VERSION ""

NS_ :

BS_:

BU_: L_3HKBD L_FHPTC L_ATCU L_2HKBD L_PCM L_ATCU_vMON L_EVNT L_HKBD L_RHPTC

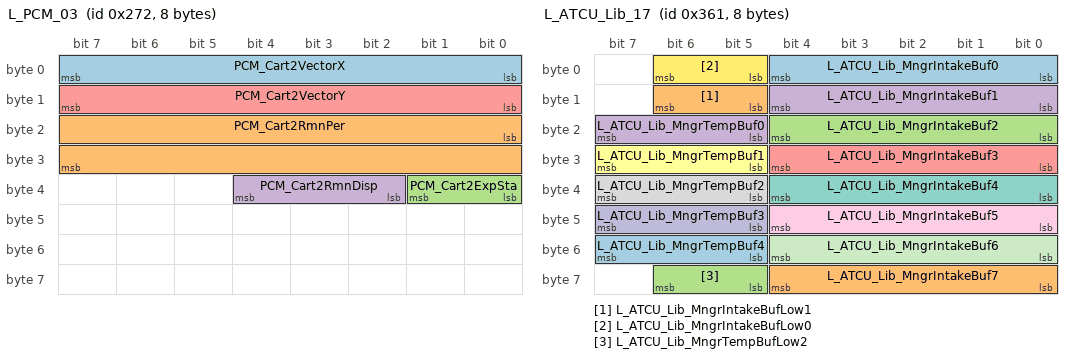
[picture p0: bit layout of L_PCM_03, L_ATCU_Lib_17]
BO_ 626 L_PCM_03: 8 L_PCM
 SG_ PCM_Cart2VectorX : 0|8@1+ (1,0) [0|0] ""  L_ATCU
 SG_ PCM_Cart2RmnPer : 16|16@1+ (0.01,0) [0|0] "%"  L_ATCU
 SG_ PCM_Cart2ExpSta : 32|2@1+ (1,0) [0|0] ""  L_ATCU
 SG_ PCM_Cart2RmnDisp : 34|3@1+ (1,0) [0|0] ""  L_ATCU
 SG_ PCM_Cart2VectorY : 8|8@1+ (1,0) [0|0] ""  L_ATCU

BO_ 327 L_FHPTC_08: 8 L_FHPTC
 SG_ FHPTC_2ndPsFlt : 0|1@1+ (1,0) [0|0] ""  L_ATCU
 SG_ FHPTC_2ndPsFltLVLow : 1|1@1+ (1,0) [0|0] ""  L_ATCU
 SG_ FHPTC_2ndPsFailLVSnr : 10|1@1+ (1,0) [0|0] ""  L_ATCU
 SG_ FHPTC_2ndPsFailCurrentSnr : 11|1@1+ (1,0) [0|0] ""  L_ATCU
 SG_ FHPTC_2ndPsFailCoreTempSnr : 12|1@1+ (1,0) [0|0] ""  L_ATCU
 SG_ FHPTC_2ndPsFailPcbTempSnr : 13|1@1+ (1,0) [0|0] ""  L_ATCU
 SG_ FHPTC_2ndPsFailIGBT : 14|1@1+ (1,0) [0|0] ""  L_ATCU
 SG_ FHPTC_2ndPsFailOpenLoad : 15|1@1+ (1,0) [0|0] ""  L_ATCU
 SG_ FHPTC_2ndPsLtdOpCause : 16|8@1+ (1,0) [0|0] ""  L_ATCU
 SG_ FHPTC_2ndPsFltLVHigh : 2|1@1+ (1,0) [0|0] ""  L_ATCU
 SG_ FHPTC_2ndPsSwVer : 24|8@1+ (1,0) [0|255] ""  L_ATCU
 SG_ FHPTC_2ndPsFltHVLow : 3|1@1+ (1,0) [0|0] ""  L_ATCU
 SG_ FHPTC_2ndPsFltHVHigh : 4|1@1+ (1,0) [0|0] ""  L_ATCU
 SG_ FHPTC_2ndPsFltOverCurrent : 5|1@1+ (1,0) [0|0] ""  L_ATCU
 SG_ FHPTC_2ndPsFltThermalShutDn : 6|1@1+ (1,0) [0|0] ""  L_ATCU
 SG_ FHPTC_2ndPsFltPcbThermalShutDn : 7|1@1+ (1,0) [0|0] ""  L_ATCU
 SG_ FHPTC_2ndPsFltMsgTmOutATCU : 8|1@1+ (1,0) [0|0] ""  L_ATCU
 SG_ FHPTC_2ndPsFailHVSnr : 9|1@1+ (1,0) [0|0] ""  L_ATCU

BO_ 865 L_ATCU_Lib_17: 8 L_ATCU
 SG_ L_ATCU_Lib_MngrIntakeBuf0 : 0|5@1+ (1,0) [0|31] ""  L_ATCU_vMON
 SG_ L_ATCU_Lib_MngrIntakeBufLow1 : 13|2@1+ (1,0) [0|3] ""  L_ATCU_vMON
 SG_ L_ATCU_Lib_MngrIntakeBuf2 : 16|5@1+ (1,0) [0|31] ""  L_ATCU_vMON
 SG_ L_ATCU_Lib_MngrTempBuf0 : 21|3@1+ (1,0) [0|7] ""  L_ATCU_vMON
 SG_ L_ATCU_Lib_MngrIntakeBuf3 : 24|5@1+ (1,0) [0|31] ""  L_ATCU_vMON
 SG_ L_ATCU_Lib_MngrTempBuf1 : 29|3@1+ (1,0) [0|7] ""  L_ATCU_vMON
 SG_ L_ATCU_Lib_MngrIntakeBuf4 : 32|5@1+ (1,0) [0|31] ""  L_ATCU_vMON
 SG_ L_ATCU_Lib_MngrTempBuf2 : 37|3@1+ (1,0) [0|7] ""  L_ATCU_vMON
 SG_ L_ATCU_Lib_MngrIntakeBuf5 : 40|5@1+ (1,0) [0|31] ""  L_ATCU_vMON
 SG_ L_ATCU_Lib_MngrTempBuf3 : 45|3@1+ (1,0) [0|7] ""  L_ATCU_vMON
 SG_ L_ATCU_Lib_MngrIntakeBuf6 : 48|5@1+ (1,0) [0|31] ""  L_ATCU_vMON
 SG_ L_ATCU_Lib_MngrIntakeBufLow0 : 5|2@1+ (1,0) [0|3] ""  L_ATCU_vMON
 SG_ L_ATCU_Lib_MngrTempBuf4 : 53|3@1+ (1,0) [0|7] ""  L_ATCU_vMON
 SG_ L_ATCU_Lib_MngrIntakeBuf7 : 56|5@1+ (1,0) [0|31] ""  L_ATCU_vMON
 SG_ L_ATCU_Lib_MngrTempBufLow2 : 61|2@1+ (1,0) [0|3] ""  L_ATCU_vMON
 SG_ L_ATCU_Lib_MngrIntakeBuf1 : 8|5@1+ (1,0) [0|31] ""  L_ATCU_vMON

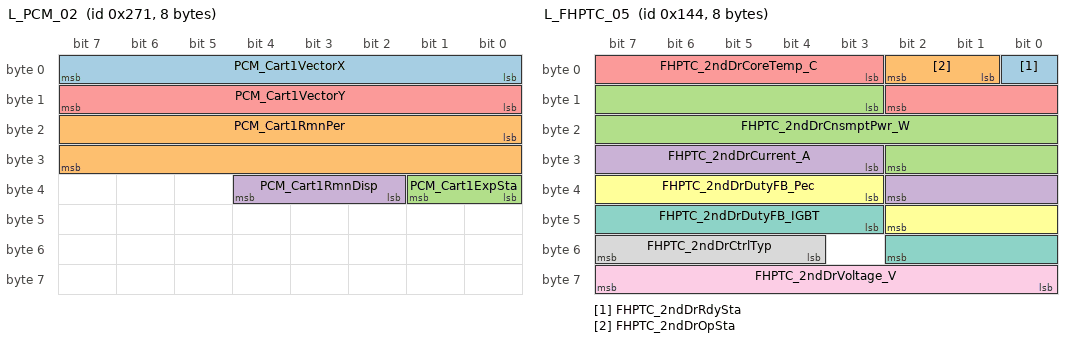
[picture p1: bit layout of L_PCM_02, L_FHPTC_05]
BO_ 625 L_PCM_02: 8 L_PCM
 SG_ PCM_Cart1VectorX : 0|8@1+ (1,0) [0|0] ""  L_ATCU
 SG_ PCM_Cart1RmnPer : 16|16@1+ (0.01,0) [0|0] "%"  L_ATCU
 SG_ PCM_Cart1ExpSta : 32|2@1+ (1,0) [0|0] ""  L_ATCU
 SG_ PCM_Cart1RmnDisp : 34|3@1+ (1,0) [0|0] ""  L_ATCU
 SG_ PCM_Cart1VectorY : 8|8@1+ (1,0) [0|0] ""  L_ATCU

BO_ 324 L_FHPTC_05: 8 L_FHPTC
 SG_ FHPTC_2ndDrRdySta : 0|1@1+ (1,0) [0|0] ""  L_ATCU
 SG_ FHPTC_2ndDrOpSta : 1|2@1+ (1,0) [0|0] ""  L_ATCU
 SG_ FHPTC_2ndDrCnsmptPwr_W : 11|16@1+ (1,0) [0|10000] "W"  L_ATCU
 SG_ FHPTC_2ndDrCurrent_A : 27|8@1+ (0.2,0) [0|50] "A"  L_ATCU
 SG_ FHPTC_2ndDrCoreTemp_C : 3|8@1+ (1,-40) [-40|200] "¡É"  L_ATCU
 SG_ FHPTC_2ndDrDutyFB_Pec : 35|8@1+ (0.5,0) [0|100] "%"  L_ATCU
 SG_ FHPTC_2ndDrDutyFB_IGBT : 43|8@1+ (0.5,0) [0|100] "%"  L_ATCU
 SG_ FHPTC_2ndDrCtrlTyp : 52|4@1+ (1,0) [0|0] ""  L_ATCU
 SG_ FHPTC_2ndDrVoltage_V : 56|8@1+ (4,0) [0|1000] "V"  L_ATCU

BO_ 866 L_ATCU_Lib_18: 8 L_ATCU
 SG_ L_ATCU_Lib_2LHMngrModBuf0 : 0|4@1+ (1,0) [0|15] ""  L_ATCU_vMON
 SG_ L_ATCU_Lib_2LHMngrModBuf3 : 12|4@1+ (1,0) [0|15] ""  L_ATCU_vMON
 SG_ L_ATCU_Lib_2LHMngrModBuf4 : 16|4@1+ (1,0) [0|15] ""  L_ATCU_vMON
 SG_ L_ATCU_Lib_2LHMngrModBuf5 : 20|4@1+ (1,0) [0|15] ""  L_ATCU_vMON
 SG_ L_ATCU_Lib_2LHMngrModBuf6 : 24|4@1+ (1,0) [0|15] ""  L_ATCU_vMON
 SG_ L_ATCU_Lib_2LHMngrModBuf7 : 28|4@1+ (1,0) [0|15] ""  L_ATCU_vMON
 SG_ L_ATCU_Lib_2LHMngrBlwBuf0 : 32|4@1+ (1,0) [0|15] ""  L_ATCU_vMON
 SG_ L_ATCU_Lib_2LHMngrBlwBuf1 : 36|4@1+ (1,0) [0|15] ""  L_ATCU_vMON
 SG_ L_ATCU_Lib_2LHMngrModBuf1 : 4|4@1+ (1,0) [0|15] ""  L_ATCU_vMON
 SG_ L_ATCU_Lib_2LHMngrBlwBuf2 : 40|4@1+ (1,0) [0|15] ""  L_ATCU_vMON
 SG_ L_ATCU_Lib_2LHMngrBlwBuf3 : 44|4@1+ (1,0) [0|15] ""  L_ATCU_vMON
 SG_ L_ATCU_Lib_2LHMngrBlwBuf4 : 48|4@1+ (1,0) [0|15] ""  L_ATCU_vMON
 SG_ L_ATCU_Lib_2LHMngrBlwBuf5 : 52|4@1+ (1,0) [0|15] ""  L_ATCU_vMON
 SG_ L_ATCU_Lib_2LHMngrBlwBuf6 : 56|4@1+ (1,0) [0|15] ""  L_ATCU_vMON
 SG_ L_ATCU_Lib_2LHMngrBlwBufHi0 : 60|2@1+ (1,0) [0|3] ""  L_ATCU_vMON
 SG_ L_ATCU_Lib_2LHMngrBlwBufHi1 : 62|2@1+ (1,0) [0|3] ""  L_ATCU_vMON
 SG_ L_ATCU_Lib_2LHMngrModBuf2 : 8|4@1+ (1,0) [0|15] ""  L_ATCU_vMON

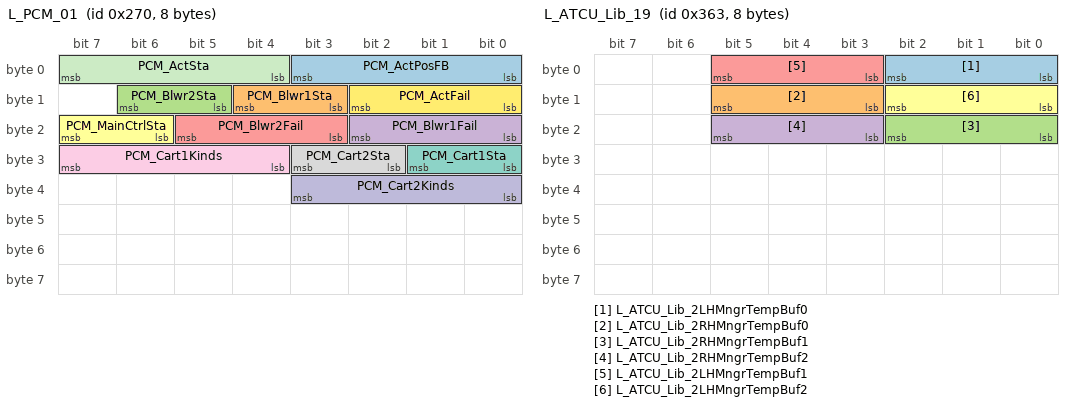
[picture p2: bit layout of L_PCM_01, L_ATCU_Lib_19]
BO_ 624 L_PCM_01: 8 L_PCM
 SG_ PCM_ActPosFB : 0|4@1+ (1,0) [0|0] ""  L_ATCU
 SG_ PCM_Blwr1Sta : 11|2@1+ (1,0) [0|0] ""  L_ATCU
 SG_ PCM_Blwr2Sta : 13|2@1+ (1,0) [0|0] ""  L_ATCU
 SG_ PCM_Blwr1Fail : 16|3@1+ (1,0) [0|0] ""  L_ATCU
 SG_ PCM_Blwr2Fail : 19|3@1+ (1,0) [0|0] ""  L_ATCU
 SG_ PCM_MainCtrlSta : 22|2@1+ (1,0) [0|0] ""  L_ATCU
 SG_ PCM_Cart1Sta : 24|2@1+ (1,0) [0|0] ""  L_ATCU
 SG_ PCM_Cart2Sta : 26|2@1+ (1,0) [0|0] ""  L_ATCU
 SG_ PCM_Cart1Kinds : 28|4@1+ (1,0) [0|0] ""  L_ATCU
 SG_ PCM_Cart2Kinds : 32|4@1+ (1,0) [0|0] ""  L_ATCU
 SG_ PCM_ActSta : 4|4@1+ (1,0) [0|0] ""  L_ATCU
 SG_ PCM_ActFail : 8|3@1+ (1,0) [0|0] ""  L_ATCU

BO_ 325 L_FHPTC_06: 8 L_FHPTC
 SG_ FHPTC_2ndDrFlt : 0|1@1+ (1,0) [0|0] ""  L_ATCU
 SG_ FHPTC_2ndDrFltLVLow : 1|1@1+ (1,0) [0|0] ""  L_ATCU
 SG_ FHPTC_2ndDrFailLVSnr : 10|1@1+ (1,0) [0|0] ""  L_ATCU
 SG_ FHPTC_2ndDrFailCurrentSnr : 11|1@1+ (1,0) [0|0] ""  L_ATCU
 SG_ FHPTC_2ndDrFailCoreTempSnr : 12|1@1+ (1,0) [0|0] ""  L_ATCU
 SG_ FHPTC_2ndDrFailPcbTempSnr : 13|1@1+ (1,0) [0|0] ""  L_ATCU
 SG_ FHPTC_2ndDrFailIGBT : 14|1@1+ (1,0) [0|0] ""  L_ATCU
 SG_ FHPTC_2ndDrFailOpenLoad : 15|1@1+ (1,0) [0|0] ""  L_ATCU
 SG_ FHPTC_2ndDrLtdOpCause : 16|8@1+ (1,0) [0|0] ""  L_ATCU
 SG_ FHPTC_2ndDrFltLVHigh : 2|1@1+ (1,0) [0|0] ""  L_ATCU
 SG_ FHPTC_2ndDrSwVer : 24|8@1+ (1,0) [0|0] ""  L_ATCU
 SG_ FHPTC_2ndDrFltHVLow : 3|1@1+ (1,0) [0|0] ""  L_ATCU
 SG_ FHPTC_2ndDrFltHVHigh : 4|1@1+ (1,0) [0|0] ""  L_ATCU
 SG_ FHPTC_2ndDrFltOverCurrent : 5|1@1+ (1,0) [0|0] ""  L_ATCU
 SG_ FHPTC_2ndDrFltThermalShutDn : 6|1@1+ (1,0) [0|0] ""  L_ATCU
 SG_ FHPTC_2ndDrFltPcbThermalShutDn : 7|1@1+ (1,0) [0|0] ""  L_ATCU
 SG_ FHPTC_2ndDrFltMsgTmOutATCU : 8|1@1+ (1,0) [0|0] ""  L_ATCU
 SG_ FHPTC_2ndDrFailHVSnr : 9|1@1+ (1,0) [0|0] ""  L_ATCU

BO_ 867 L_ATCU_Lib_19: 8 L_ATCU
 SG_ L_ATCU_Lib_2LHMngrTempBuf0 : 0|3@1+ (1,0) [0|7] ""  L_ATCU_vMON
 SG_ L_ATCU_Lib_2RHMngrTempBuf0 : 11|3@1+ (1,0) [0|7] ""  L_ATCU_vMON
 SG_ L_ATCU_Lib_2RHMngrTempBuf1 : 16|3@1+ (1,0) [0|7] ""  L_ATCU_vMON
 SG_ L_ATCU_Lib_2RHMngrTempBuf2 : 19|3@1+ (1,0) [0|7] ""  L_ATCU_vMON
 SG_ L_ATCU_Lib_2LHMngrTempBuf1 : 3|3@1+ (1,0) [0|7] ""  L_ATCU_vMON
 SG_ L_ATCU_Lib_2LHMngrTempBuf2 : 8|3@1+ (1,0) [0|7] ""  L_ATCU_vMON

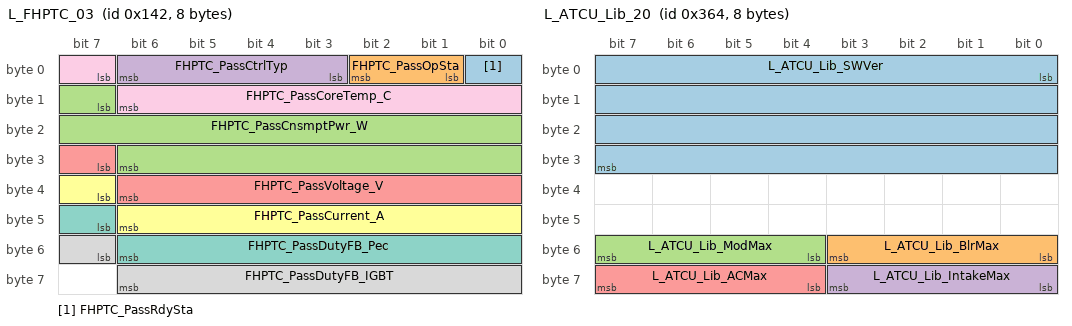
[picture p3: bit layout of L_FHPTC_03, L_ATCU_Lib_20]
BO_ 322 L_FHPTC_03: 8 L_FHPTC
 SG_ FHPTC_PassRdySta : 0|1@1+ (1,0) [0|0] ""  L_ATCU
 SG_ FHPTC_PassOpSta : 1|2@1+ (1,0) [0|0] ""  L_ATCU
 SG_ FHPTC_PassCnsmptPwr_W : 15|16@1+ (1,0) [0|10000] "W"  L_ATCU
 SG_ FHPTC_PassCtrlTyp : 3|4@1+ (1,0) [0|0] ""  L_ATCU
 SG_ FHPTC_PassVoltage_V : 31|8@1+ (4,0) [0|1000] "V"  L_ATCU
 SG_ FHPTC_PassCurrent_A : 39|8@1+ (0.2,0) [0|50] "A"  L_ATCU
 SG_ FHPTC_PassDutyFB_Pec : 47|8@1+ (0.5,0) [0|100] "%"  L_ATCU
 SG_ FHPTC_PassDutyFB_IGBT : 55|8@1+ (0.5,0) [0|100] "%"  L_ATCU
 SG_ FHPTC_PassCoreTemp_C : 7|8@1+ (1,-40) [-40|200] "¡É"  L_ATCU

BO_ 868 L_ATCU_Lib_20: 8 L_ATCU
 SG_ L_ATCU_Lib_SWVer : 0|32@1+ (1,0) [0|0] ""  L_ATCU_vMON
 SG_ L_ATCU_Lib_BlrMax : 48|4@1+ (1,0) [0|0] ""  L_ATCU_vMON
 SG_ L_ATCU_Lib_ModMax : 52|4@1+ (1,0) [0|0] ""  L_ATCU_vMON
 SG_ L_ATCU_Lib_IntakeMax : 56|4@1+ (1,0) [0|0] ""  L_ATCU_vMON
 SG_ L_ATCU_Lib_ACMax : 60|4@1+ (1,0) [0|0] ""  L_ATCU_vMON

BO_ 323 L_FHPTC_04: 8 L_FHPTC
 SG_ FHPTC_PassFlt : 0|1@1+ (1,0) [0|0] ""  L_ATCU
 SG_ FHPTC_PassFltLVLow : 1|1@1+ (1,0) [0|0] ""  L_ATCU
 SG_ FHPTC_PassFailLVSnr : 10|1@1+ (1,0) [0|0] ""  L_ATCU
 SG_ FHPTC_PassFailCurrentSnr : 11|1@1+ (1,0) [0|0] ""  L_ATCU
 SG_ FHPTC_PassFailCoreTempSnr : 12|1@1+ (1,0) [0|0] ""  L_ATCU
 SG_ FHPTC_PassFailPcbTempSnr : 13|1@1+ (1,0) [0|0] ""  L_ATCU
 SG_ FHPTC_PassFailIGBT : 14|1@1+ (1,0) [0|0] ""  L_ATCU
 SG_ FHPTC_PassFailOpenLoad : 15|1@1+ (1,0) [0|0] ""  L_ATCU
 SG_ FHPTC_PassLtdOpCause : 16|8@1+ (1,0) [0|0] ""  L_ATCU
 SG_ FHPTC_PassFltLVHigh : 2|1@1+ (1,0) [0|0] ""  L_ATCU
 SG_ FHPTC_PassSwVer : 24|8@1+ (1,0) [0|255] ""  L_ATCU
 SG_ FHPTC_PassFltHVLow : 3|1@1+ (1,0) [0|0] ""  L_ATCU
 SG_ FHPTC_PassFltHVHigh : 4|1@1+ (1,0) [0|0] ""  L_ATCU
 SG_ FHPTC_PassFltOverCurrent : 5|1@1+ (1,0) [0|0] ""  L_ATCU
 SG_ FHPTC_PassFltThermalShutDn : 6|1@1+ (1,0) [0|0] ""  L_ATCU
 SG_ FHPTC_PassFltPcbThermalShutDn : 7|1@1+ (1,0) [0|0] ""  L_ATCU
 SG_ FHPTC_PassFltMsgTmOutATCU : 8|1@1+ (1,0) [0|0] ""  L_ATCU
 SG_ FHPTC_PassFailHVSnr : 9|1@1+ (1,0) [0|0] ""  L_ATCU

BO_ 869 L_ATCU_Lib_21: 8 L_ATCU
 SG_ L_ATCU_Lib_StatMngr_Humid : 0|64@1+ (1,0) [0|0] ""  L_ATCU_vMON

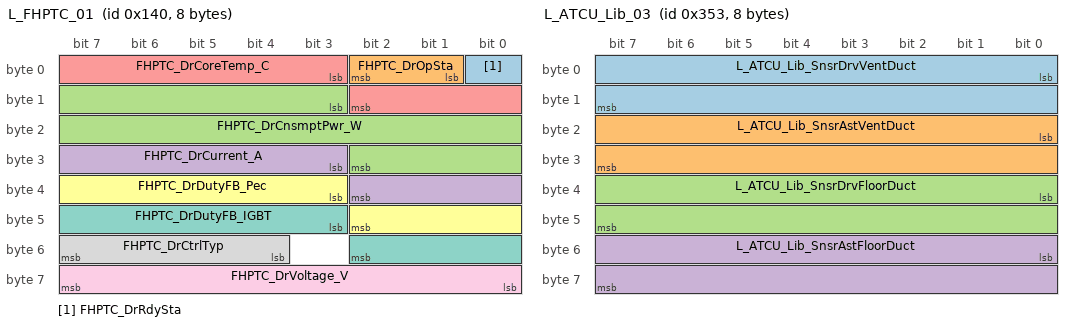
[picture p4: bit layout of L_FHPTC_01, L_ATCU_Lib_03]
BO_ 320 L_FHPTC_01: 8 L_FHPTC
 SG_ FHPTC_DrRdySta : 0|1@1+ (1,0) [0|0] ""  L_ATCU
 SG_ FHPTC_DrOpSta : 1|2@1+ (1,0) [0|0] ""  L_ATCU
 SG_ FHPTC_DrCnsmptPwr_W : 11|16@1+ (1,0) [0|10000] "W"  L_ATCU
 SG_ FHPTC_DrCurrent_A : 27|8@1+ (0.2,0) [0|50] "A"  L_ATCU
 SG_ FHPTC_DrCoreTemp_C : 3|8@1+ (1,-40) [-40|200] "¡É"  L_ATCU
 SG_ FHPTC_DrDutyFB_Pec : 35|8@1+ (0.5,0) [0|100] "%"  L_ATCU
 SG_ FHPTC_DrDutyFB_IGBT : 43|8@1+ (0.5,0) [0|100] "%"  L_ATCU
 SG_ FHPTC_DrCtrlTyp : 52|4@1+ (1,0) [0|0] ""  L_ATCU
 SG_ FHPTC_DrVoltage_V : 56|8@1+ (4,0) [0|1000] "V"  L_ATCU

BO_ 870 L_ATCU_Lib_22: 8 L_ATCU
 SG_ L_ATCU_Lib_StatMngr_Temp : 0|64@1+ (1,0) [0|0] ""  L_ATCU_vMON

BO_ 321 L_FHPTC_02: 8 L_FHPTC
 SG_ FHPTC_DrFlt : 0|1@1+ (1,0) [0|0] ""  L_ATCU
 SG_ FHPTC_DrFltLVLow : 1|1@1+ (1,0) [0|0] ""  L_ATCU
 SG_ FHPTC_DrFailLVSnr : 10|1@1+ (1,0) [0|0] ""  L_ATCU
 SG_ FHPTC_DrFailCurrentSnr : 11|1@1+ (1,0) [0|0] ""  L_ATCU
 SG_ FHPTC_DrFailCoreTempSnr : 12|1@1+ (1,0) [0|0] ""  L_ATCU
 SG_ FHPTC_DrFailPcbTempSnr : 13|1@1+ (1,0) [0|0] ""  L_ATCU
 SG_ FHPTC_DrFailIGBT : 14|1@1+ (1,0) [0|0] ""  L_ATCU
 SG_ FHPTC_DrFailOpenLoad : 15|1@1+ (1,0) [0|0] ""  L_ATCU
 SG_ FHPTC_DrLtdOpCause : 16|8@1+ (1,0) [0|0] ""  L_ATCU
 SG_ FHPTC_DrFltLVHigh : 2|1@1+ (1,0) [0|0] ""  L_ATCU
 SG_ FHPTC_DrSwVer : 24|8@1+ (1,0) [0|0] ""  L_ATCU
 SG_ FHPTC_DrFltHVLow : 3|1@1+ (1,0) [0|0] ""  L_ATCU
 SG_ FHPTC_CnsmptPwrTtl_W : 32|16@1+ (1,0) [0|10000] "W"  L_ATCU
 SG_ FHPTC_DrFltHVHigh : 4|1@1+ (1,0) [0|0] ""  L_ATCU
 SG_ FHPTC_IntlkSta : 48|2@1+ (1,0) [0|0] ""  L_ATCU
 SG_ FHPTC_DrFltOverCurrent : 5|1@1+ (1,0) [0|0] ""  L_ATCU
 SG_ FHPTC_DrFltThermalShutDn : 6|1@1+ (1,0) [0|0] ""  L_ATCU
 SG_ FHPTC_DrFltPcbThermalShutDn : 7|1@1+ (1,0) [0|0] ""  L_ATCU
 SG_ FHPTC_DrFltMsgTmOutATCU : 8|1@1+ (1,0) [0|0] ""  L_ATCU
 SG_ FHPTC_DrFailHVSnr : 9|1@1+ (1,0) [0|0] ""  L_ATCU

BO_ 871 L_ATCU_Lib_23: 8 L_ATCU
 SG_ L_ATCU_Lib_StatMngr_SafetynCool : 0|64@1+ (1,0) [0|0] ""  L_ATCU_vMON

BO_ 872 L_ATCU_Lib_24: 8 L_ATCU
 SG_ L_ATCU_Lib_StatMngr_Mngr : 0|64@1+ (1,0) [0|0] ""  L_ATCU_vMON

BO_ 1040 L_EVNT_10: 8 L_EVNT
 SG_ L_EVNT_FrDrEVntAutoFlowOSDReq : 0|2@1+ (1,0) [0|0] ""  L_ATCU
 SG_ L_EVNT_FrAstEVntAutoFlowOSDReq : 2|2@1+ (1,0) [0|0] ""  L_ATCU

BO_ 873 L_ATCU_Lib_25: 8 L_ATCU
 SG_ L_ATCU_Lib_StatMngr_Convenience : 0|64@1+ (1,0) [0|0] ""  L_ATCU_vMON

BO_ 874 L_ATCU_Lib_26: 8 L_ATCU
 SG_ L_ATCU_Lib_StatMngr_AirQuality : 0|64@1+ (1,0) [0|0] ""  L_ATCU_vMON

BO_ 875 L_ATCU_Lib_27: 8 L_ATCU
 SG_ L_ATCU_Lib_StatMngr_ETC : 0|64@1+ (1,0) [0|0] ""  L_ATCU_vMON

BO_ 876 L_ATCU_Lib_28: 8 L_ATCU
 SG_ L_ATCU_Lib_StatMngr_FuelEfficiency : 0|64@1+ (1,0) [0|0] ""  L_ATCU_vMON

BO_ 877 L_ATCU_Lib_29: 8 L_ATCU
 SG_ L_ATCU_Lib_StatMngr_Snsr : 0|64@1+ (1,0) [0|0] ""  L_ATCU_vMON

BO_ 878 L_ATCU_Lib_30: 8 L_ATCU
 SG_ L_ATCU_Lib_StatMngr_2ndHumid : 0|64@1+ (1,0) [0|0] ""  L_ATCU_vMON

BO_ 879 L_ATCU_Lib_31: 8 L_ATCU
 SG_ L_ATCU_Lib_StatMngr_2ndTemp : 0|64@1+ (1,0) [0|0] ""  L_ATCU_vMON

BO_ 851 L_ATCU_Lib_03: 8 L_ATCU
 SG_ L_ATCU_Lib_SnsrDrvVentDuct : 0|16@1+ (0.1,-40) [-40|120] "¡É"  L_ATCU_vMON
 SG_ L_ATCU_Lib_SnsrAstVentDuct : 16|16@1+ (0.1,-40) [-40|120] "¡É"  L_ATCU_vMON
 SG_ L_ATCU_Lib_SnsrDrvFloorDuct : 32|16@1+ (0.1,-40) [-40|120] "¡É"  L_ATCU_vMON
 SG_ L_ATCU_Lib_SnsrAstFloorDuct : 48|16@1+ (0.1,-40) [-40|120] "¡É"  L_ATCU_vMON

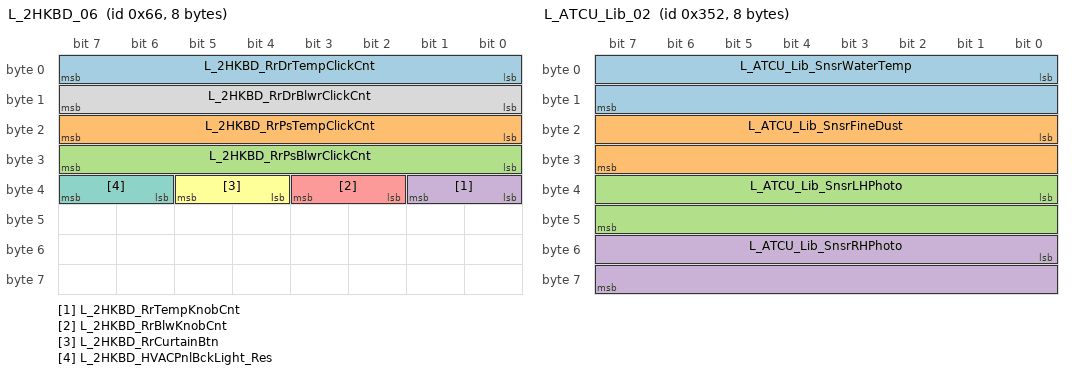
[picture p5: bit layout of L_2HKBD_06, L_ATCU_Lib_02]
BO_ 102 L_2HKBD_06: 8 L_2HKBD
 SG_ L_2HKBD_RrDrTempClickCnt : 0|8@1+ (1,0) [0|0] ""  L_ATCU
 SG_ L_2HKBD_RrPsTempClickCnt : 16|8@1+ (1,0) [0|0] ""  L_ATCU
 SG_ L_2HKBD_RrPsBlwrClickCnt : 24|8@1+ (1,0) [0|0] ""  L_ATCU
 SG_ L_2HKBD_RrTempKnobCnt : 32|2@1+ (1,0) [0|0] ""  L_ATCU
 SG_ L_2HKBD_RrBlwKnobCnt : 34|2@1+ (1,0) [0|0] ""  L_ATCU
 SG_ L_2HKBD_RrCurtainBtn : 36|2@1+ (1,0) [0|0] ""  L_ATCU
 SG_ L_2HKBD_HVACPnlBckLight_Res : 38|2@1+ (1,0) [0|0] ""  L_ATCU
 SG_ L_2HKBD_RrDrBlwrClickCnt : 8|8@1+ (1,0) [0|0] ""  L_ATCU

BO_ 850 L_ATCU_Lib_02: 8 L_ATCU
 SG_ L_ATCU_Lib_SnsrWaterTemp : 0|16@1+ (0.01,-48) [-48|200] "¡É"  L_ATCU_vMON
 SG_ L_ATCU_Lib_SnsrFineDust : 16|16@1+ (1,0) [0|255] ""  L_ATCU_vMON
 SG_ L_ATCU_Lib_SnsrLHPhoto : 32|16@1+ (0.001,0) [0|5] "V"  L_ATCU_vMON
 SG_ L_ATCU_Lib_SnsrRHPhoto : 48|16@1+ (0.001,0) [0|5] "V"  L_ATCU_vMON

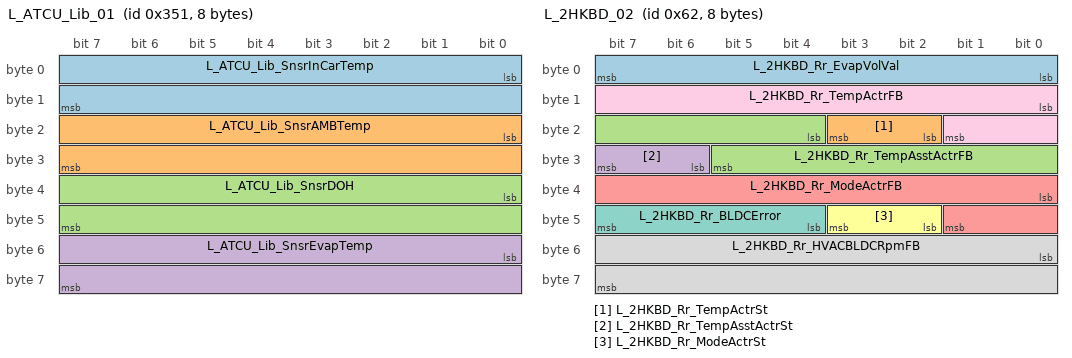
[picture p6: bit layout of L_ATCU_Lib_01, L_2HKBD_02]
BO_ 849 L_ATCU_Lib_01: 8 L_ATCU
 SG_ L_ATCU_Lib_SnsrInCarTemp : 0|16@1+ (0.1,-40) [-40|60] "¡É"  L_ATCU_vMON
 SG_ L_ATCU_Lib_SnsrAMBTemp : 16|16@1+ (0.1,-40) [-40|60] "¡É"  L_ATCU_vMON
 SG_ L_ATCU_Lib_SnsrDOH : 32|16@1+ (1,0) [0|100] "%"  L_ATCU_vMON
 SG_ L_ATCU_Lib_SnsrEvapTemp : 48|16@1+ (0.1,-20) [-20|40] "¡É"  L_ATCU_vMON

BO_ 100 L_2HKBD_04: 8 L_2HKBD
 SG_ L_2HKBD_RrDrModeDnSw : 0|1@1+ (1,0) [0|0] ""  L_ATCU
 SG_ L_2HKBD_RrDrModeUpSw : 1|1@1+ (1,0) [0|0] ""  L_ATCU
 SG_ L_2HKBD_RrDrAutoSw : 10|1@1+ (1,0) [0|0] ""  L_ATCU
 SG_ L_2HKBD_Rr_OffSw : 11|1@1+ (1,0) [0|0] ""  L_ATCU
 SG_ L_2HKBD_RrSyncSw : 12|1@1+ (1,0) [0|0] ""  L_ATCU
 SG_ L_2HKBD_RrAcSw : 13|1@1+ (1,0) [0|0] ""  L_ATCU
 SG_ L_2HKBD_RLStHtrSwReq : 14|1@1+ (1,0) [0|0] ""  L_ATCU
 SG_ L_2HKBD_RLStVentSwReq : 15|1@1+ (1,0) [0|0] ""  L_ATCU
 SG_ L_2HKBD_RRStHtrSwReq : 16|1@1+ (1,0) [0|0] ""  L_ATCU
 SG_ L_2HKBD_RRStVentSwReq : 17|1@1+ (1,0) [0|0] ""  L_ATCU
 SG_ L_2HKBD_RrDrMultiAutoSw : 18|3@1+ (1,0) [0|0] ""  L_ATCU
 SG_ L_2HKBD_RrDrModeSw : 2|1@1+ (1,0) [0|0] ""  L_ATCU
 SG_ L_2HKBD_RrPsModeSw : 21|1@1+ (1,0) [0|0] ""  L_ATCU
 SG_ L_2HKBD_RrPsModeDnSw : 22|1@1+ (1,0) [0|0] ""  L_ATCU
 SG_ L_2HKBD_RrPsModeUpSw : 23|1@1+ (1,0) [0|0] ""  L_ATCU
 SG_ L_2HKBD_RrPsModeVentSw : 24|1@1+ (1,0) [0|0] ""  L_ATCU
 SG_ L_2HKBD_RrPsModeFloorSw : 25|1@1+ (1,0) [0|0] ""  L_ATCU
 SG_ L_2HKBD_RrPsModeBiLvlSw : 26|1@1+ (1,0) [0|0] ""  L_ATCU
 SG_ L_2HKBD_RrPsTempDnSw : 27|1@1+ (1,0) [0|0] ""  L_ATCU
 SG_ L_2HKBD_RrPsTempUpSw : 28|1@1+ (1,0) [0|0] ""  L_ATCU
 SG_ L_2HKBD_RrPsBlwUpSw : 29|1@1+ (1,0) [0|0] ""  L_ATCU
 SG_ L_2HKBD_RrDRModeVentSw : 3|1@1+ (1,0) [0|0] ""  L_ATCU
 SG_ L_2HKBD_RrPsBlwDnSw : 30|1@1+ (1,0) [0|0] ""  L_ATCU
 SG_ L_2HKBD_RrPsAutoSw : 31|1@1+ (1,0) [0|0] ""  L_ATCU
 SG_ L_2HKBD_RrPsMultiAutoSw : 32|3@1+ (1,0) [0|0] ""  L_ATCU
 SG_ L_2HKBD_RrDrBlwDnOffSw : 35|1@1+ (1,0) [0|0] ""  L_ATCU
 SG_ L_2HKBD_RrPsBlwDnOffSw : 36|1@1+ (1,0) [0|0] ""  L_ATCU
 SG_ L_2HKBD_RrOnOffSet : 37|2@1+ (1,0) [0|0] ""  L_ATCU
 SG_ L_2HKBD_RrDrblwUpMaxSw : 39|1@1+ (1,0) [0|0] ""  L_ATCU
 SG_ L_2HKBD_RrDrModeFloorSw : 4|1@1+ (1,0) [0|0] ""  L_ATCU
 SG_ L_2HKBD_RrPsblwUpMaxSw : 40|1@1+ (1,0) [0|0] ""  L_ATCU
 SG_ L_2HKBD_RrDrModeBiLvlSw : 5|1@1+ (1,0) [0|0] ""  L_ATCU
 SG_ L_2HKBD_RrDrTempDnSw : 6|1@1+ (1,0) [0|0] ""  L_ATCU
 SG_ L_2HKBD_RrDrTempUpSw : 7|1@1+ (1,0) [0|0] ""  L_ATCU
 SG_ L_2HKBD_RrDrBlwDnSw : 8|1@1+ (1,0) [0|0] ""  L_ATCU
 SG_ L_2HKBD_RrDrBlwUpSw : 9|1@1+ (1,0) [0|0] ""  L_ATCU

BO_ 101 L_2HKBD_05: 8 L_2HKBD
 SG_ L_2HKBD_RrFlrDuctSnsr : 0|8@1+ (0.02,0) [0|0] "V"  L_ATCU
 SG_ L_2HKBD_RrVntDuctSnsr : 9|8@1+ (0.02,0) [0|0] "V"  L_ATCU

BO_ 98 L_2HKBD_02: 8 L_2HKBD
 SG_ L_2HKBD_Rr_EvapVolVal : 0|8@1+ (0.02,0) [0|0] ""  L_ATCU
 SG_ L_2HKBD_Rr_TempActrSt : 18|2@1+ (1,0) [0|0] ""  L_ATCU
 SG_ L_2HKBD_Rr_TempAsstActrFB : 20|10@1+ (1,0) [0|0] ""  L_ATCU
 SG_ L_2HKBD_Rr_TempAsstActrSt : 30|2@1+ (1,0) [0|0] ""  L_ATCU
 SG_ L_2HKBD_Rr_ModeActrFB : 32|10@1+ (1,0) [0|0] ""  L_ATCU
 SG_ L_2HKBD_Rr_ModeActrSt : 42|2@1+ (1,0) [0|0] ""  L_ATCU
 SG_ L_2HKBD_Rr_BLDCError : 44|4@1+ (1,0) [0|0] ""  L_ATCU
 SG_ L_2HKBD_Rr_HVACBLDCRpmFB : 48|16@1+ (5,0) [0|0] "RPM"  L_ATCU
 SG_ L_2HKBD_Rr_TempActrFB : 8|10@1+ (1,0) [0|0] ""  L_ATCU

BO_ 855 L_ATCU_Lib_07: 8 L_ATCU
 SG_ L_ATCU_Lib_2ndAutoSw : 0|1@1+ (1,0) [0|1] ""  L_ATCU_vMON
 SG_ L_ATCU_Lib_2ndAutoUpSw : 1|1@1+ (1,0) [0|1] ""  L_ATCU_vMON
 SG_ L_ATCU_Lib_2LHTempUpSw : 10|1@1+ (1,0) [0|1] ""  L_ATCU_vMON
 SG_ L_ATCU_Lib_2LHTempDnSw : 11|1@1+ (1,0) [0|1] ""  L_ATCU_vMON
 SG_ L_ATCU_Lib_2RHTempUpSw : 12|1@1+ (1,0) [0|1] ""  L_ATCU_vMON
 SG_ L_ATCU_Lib_2RHTempDnSw : 13|1@1+ (1,0) [0|1] ""  L_ATCU_vMON
 SG_ L_ATCU_Lib_2ndSyncSw : 14|1@1+ (1,0) [0|1] ""  L_ATCU_vMON
 SG_ L_ATCU_Lib_2ndLockSw : 15|1@1+ (1,0) [0|1] ""  L_ATCU_vMON
 SG_ L_ATCU_Lib_2LHSeatHeatSw : 16|1@1+ (1,0) [0|1] ""  L_ATCU_vMON
 SG_ L_ATCU_Lib_2LHSeatVentSw : 17|1@1+ (1,0) [0|1] ""  L_ATCU_vMON
 SG_ L_ATCU_Lib_2RHSeatHeatSw : 18|1@1+ (1,0) [0|1] ""  L_ATCU_vMON
 SG_ L_ATCU_Lib_2RHSeatVentSw : 19|1@1+ (1,0) [0|1] ""  L_ATCU_vMON
 SG_ L_ATCU_Lib_2ndAutoDnSw : 2|1@1+ (1,0) [0|1] ""  L_ATCU_vMON
 SG_ L_ATCU_Lib_2LHSeatTumblerSw : 20|2@1+ (1,0) [0|3] ""  L_ATCU_vMON
 SG_ L_ATCU_Lib_2RHSeatTumblerSw : 22|2@1+ (1,0) [0|3] ""  L_ATCU_vMON
 SG_ L_ATCU_Lib_2ndOffSetSw : 24|2@1+ (1,0) [0|3] ""  L_ATCU_vMON
 SG_ L_ATCU_Lib_2ndAutoSetSw : 26|2@1+ (1,0) [0|3] ""  L_ATCU_vMON
 SG_ L_ATCU_Lib_2ndMultiAutoSetSw : 28|2@1+ (1,0) [0|3] ""  L_ATCU_vMON
 SG_ L_ATCU_Lib_2LHModSw : 3|1@1+ (1,0) [0|1] ""  L_ATCU_vMON
 SG_ L_ATCU_Lib_2ndACSetSw : 30|2@1+ (1,0) [0|3] ""  L_ATCU_vMON
 SG_ L_ATCU_Lib_2LHModSetSw : 32|4@1+ (1,0) [0|15] ""  L_ATCU_vMON
 SG_ L_ATCU_Lib_2LHBlrSetSw : 36|4@1+ (1,0) [0|15] ""  L_ATCU_vMON
 SG_ L_ATCU_Lib_2LHModUpSw : 4|1@1+ (1,0) [0|1] ""  L_ATCU_vMON
 SG_ L_ATCU_Lib_2LHTempSetSw : 40|5@1+ (1,0) [0|31] ""  L_ATCU_vMON
 SG_ L_ATCU_Lib_2ndSyncSetSw : 45|2@1+ (1,0) [0|3] ""  L_ATCU_vMON
 SG_ L_ATCU_Lib_2ndOffSw : 47|1@1+ (1,0) [0|1] ""  L_ATCU_vMON
 SG_ L_ATCU_Lib_2RHTempSetSw : 48|5@1+ (1,0) [0|31] ""  L_ATCU_vMON
 SG_ L_ATCU_Lib_2LHModDnSw : 5|1@1+ (1,0) [0|1] ""  L_ATCU_vMON
 SG_ L_ATCU_Lib_2ndLockSetSw : 53|2@1+ (1,0) [0|3] ""  L_ATCU_vMON
 SG_ L_ATCU_Lib_DrvBlrClickCnt : 56|8@1+ (1,0) [0|255] ""  L_ATCU_vMON
 SG_ L_ATCU_Lib_2LHBlrUpSw : 6|1@1+ (1,0) [0|1] ""  L_ATCU_vMON
 SG_ L_ATCU_Lib_2LHBlrDnSw : 7|1@1+ (1,0) [0|1] ""  L_ATCU_vMON
 SG_ L_ATCU_Lib_2LHBlrDnOffReq : 8|1@1+ (1,0) [0|1] ""  L_ATCU_vMON
 SG_ L_ATCU_Lib_2ndACSw : 9|1@1+ (1,0) [0|1] ""  L_ATCU_vMON

BO_ 368 L_ATCU_40: 8 L_ATCU
 SG_ L_ATCU_AVNCluUSMReset : 0|2@1+ (1,0) [0|0] ""  L_2HKBD,L_3HKBD,L_EVNT,L_HKBD
 SG_ L_ATCU_HVACPnlBckLight_Set : 2|2@1+ (1,0) [0|0] ""  L_2HKBD,L_3HKBD,L_EVNT,L_HKBD

BO_ 99 L_2HKBD_03: 8 L_2HKBD
 SG_ L_2HKBD_SwBtnTyp : 0|40@1+ (1,0) [0|0] ""  L_ATCU
 SG_ L_2HKBD_ResetOpSta : 62|2@1+ (1,0) [0|0] ""  L_ATCU

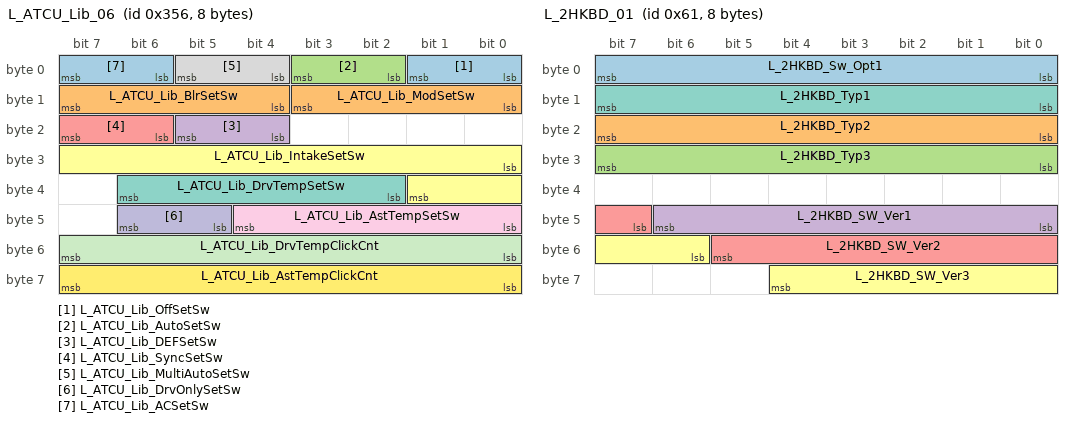
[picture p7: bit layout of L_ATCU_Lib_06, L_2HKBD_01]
BO_ 854 L_ATCU_Lib_06: 8 L_ATCU
 SG_ L_ATCU_Lib_OffSetSw : 0|2@1+ (1,0) [0|3] ""  L_ATCU_vMON
 SG_ L_ATCU_Lib_BlrSetSw : 12|4@1+ (1,0) [0|15] ""  L_ATCU_vMON
 SG_ L_ATCU_Lib_AutoSetSw : 2|2@1+ (1,0) [0|3] ""  L_ATCU_vMON
 SG_ L_ATCU_Lib_DEFSetSw : 20|2@1+ (1,0) [0|3] ""  L_ATCU_vMON
 SG_ L_ATCU_Lib_SyncSetSw : 22|2@1+ (1,0) [0|3] ""  L_ATCU_vMON
 SG_ L_ATCU_Lib_IntakeSetSw : 24|10@1+ (1,0) [0|1023] ""  L_ATCU_vMON
 SG_ L_ATCU_Lib_DrvTempSetSw : 34|5@1+ (1,0) [0|31] ""  L_ATCU_vMON
 SG_ L_ATCU_Lib_MultiAutoSetSw : 4|2@1+ (1,0) [0|3] ""  L_ATCU_vMON
 SG_ L_ATCU_Lib_AstTempSetSw : 40|5@1+ (1,0) [0|31] ""  L_ATCU_vMON
 SG_ L_ATCU_Lib_DrvOnlySetSw : 45|2@1+ (1,0) [0|3] ""  L_ATCU_vMON
 SG_ L_ATCU_Lib_DrvTempClickCnt : 48|8@1+ (1,0) [0|255] ""  L_ATCU_vMON
 SG_ L_ATCU_Lib_AstTempClickCnt : 56|8@1+ (1,0) [0|255] ""  L_ATCU_vMON
 SG_ L_ATCU_Lib_ACSetSw : 6|2@1+ (1,0) [0|3] ""  L_ATCU_vMON
 SG_ L_ATCU_Lib_ModSetSw : 8|4@1+ (1,0) [0|15] ""  L_ATCU_vMON

BO_ 853 L_ATCU_Lib_05: 8 L_ATCU
 SG_ L_ATCU_Lib_OffSw : 0|1@1+ (1,0) [0|1] ""  L_ATCU_vMON
 SG_ L_ATCU_Lib_AutoSw : 1|1@1+ (1,0) [0|1] ""  L_ATCU_vMON
 SG_ L_ATCU_Lib_BlrDnOffReq : 10|1@1+ (1,0) [0|1] ""  L_ATCU_vMON
 SG_ L_ATCU_Lib_IntakeRECSw : 11|1@1+ (1,0) [0|1] ""  L_ATCU_vMON
 SG_ L_ATCU_Lib_IntakeFRESw : 12|1@1+ (1,0) [0|1] ""  L_ATCU_vMON
 SG_ L_ATCU_Lib_ACSw : 13|1@1+ (1,0) [0|1] ""  L_ATCU_vMON
 SG_ L_ATCU_Lib_DEFSw : 14|1@1+ (1,0) [0|1] ""  L_ATCU_vMON
 SG_ L_ATCU_Lib_DrvTempUpSw : 15|1@1+ (1,0) [0|1] ""  L_ATCU_vMON
 SG_ L_ATCU_Lib_DrvTempDnSw : 16|1@1+ (1,0) [0|1] ""  L_ATCU_vMON
 SG_ L_ATCU_Lib_AstTempUpSw : 17|1@1+ (1,0) [0|1] ""  L_ATCU_vMON
 SG_ L_ATCU_Lib_AstTempDnSw : 18|1@1+ (1,0) [0|1] ""  L_ATCU_vMON
 SG_ L_ATCU_Lib_SyncSw : 19|1@1+ (1,0) [0|1] ""  L_ATCU_vMON
 SG_ L_ATCU_Lib_ModSw : 2|1@1+ (1,0) [0|1] ""  L_ATCU_vMON
 SG_ L_ATCU_Lib_DrvOnlySw : 20|1@1+ (1,0) [0|1] ""  L_ATCU_vMON
 SG_ L_ATCU_Lib_ClimateSw : 21|1@1+ (1,0) [0|1] ""  L_ATCU_vMON
 SG_ L_ATCU_Lib_RearDEFSw : 22|1@1+ (1,0) [0|1] ""  L_ATCU_vMON
 SG_ L_ATCU_Lib_StrWhlSw : 23|1@1+ (1,0) [0|1] ""  L_ATCU_vMON
 SG_ L_ATCU_Lib_DrvSeatHeatSw : 24|1@1+ (1,0) [0|1] ""  L_ATCU_vMON
 SG_ L_ATCU_Lib_DrvSeatVentSw : 25|1@1+ (1,0) [0|1] ""  L_ATCU_vMON
 SG_ L_ATCU_Lib_AstSeatHeatSw : 26|1@1+ (1,0) [0|1] ""  L_ATCU_vMON
 SG_ L_ATCU_Lib_AstSeatVentSw : 27|1@1+ (1,0) [0|1] ""  L_ATCU_vMON
 SG_ L_ATCU_Lib_DrvSeatTumblerSw : 28|2@1+ (1,0) [0|3] ""  L_ATCU_vMON
 SG_ L_ATCU_Lib_ModUpSw : 3|1@1+ (1,0) [0|1] ""  L_ATCU_vMON
 SG_ L_ATCU_Lib_AstSeatTumblerSw : 30|2@1+ (1,0) [0|3] ""  L_ATCU_vMON
 SG_ L_ATCU_Lib_ModDnSw : 4|1@1+ (1,0) [0|1] ""  L_ATCU_vMON
 SG_ L_ATCU_Lib_BlrUpSw : 8|1@1+ (1,0) [0|1] ""  L_ATCU_vMON
 SG_ L_ATCU_Lib_BlrDnSw : 9|1@1+ (1,0) [0|1] ""  L_ATCU_vMON

BO_ 97 L_2HKBD_01: 8 L_2HKBD
 SG_ L_2HKBD_Sw_Opt1 : 0|8@1+ (1,0) [0|0] ""  L_ATCU
 SG_ L_2HKBD_Typ2 : 16|8@1+ (1,0) [0|0] ""  L_ATCU
 SG_ L_2HKBD_Typ3 : 24|8@1+ (1,0) [0|0] ""  L_ATCU
 SG_ L_2HKBD_SW_Ver1 : 40|7@1+ (1,0) [0|0] ""  L_ATCU_vMON
 SG_ L_2HKBD_SW_Ver2 : 47|7@1+ (1,0) [0|0] ""  L_ATCU_vMON
 SG_ L_2HKBD_SW_Ver3 : 54|7@1+ (1,0) [0|0] ""  L_ATCU_vMON
 SG_ L_2HKBD_Typ1 : 8|8@1+ (1,0) [0|0] ""  L_ATCU

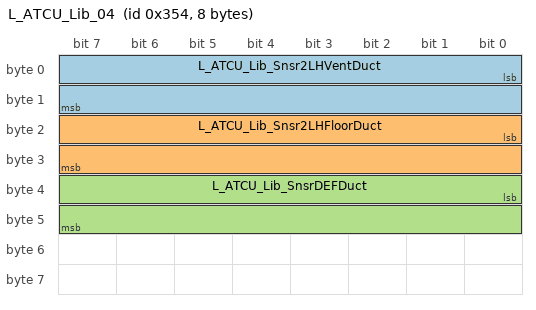
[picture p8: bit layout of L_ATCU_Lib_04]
BO_ 852 L_ATCU_Lib_04: 8 L_ATCU
 SG_ L_ATCU_Lib_Snsr2LHVentDuct : 0|16@1+ (0.1,-40) [-40|120] "¡É"  L_ATCU_vMON
 SG_ L_ATCU_Lib_Snsr2LHFloorDuct : 16|16@1+ (0.1,-40) [-40|120] "¡É"  L_ATCU_vMON
 SG_ L_ATCU_Lib_SnsrDEFDuct : 32|16@1+ (0.1,-40) [-40|120] "¡É"  L_ATCU_vMON

CM_ BO_ 97 "[PE] Periodic and On Event";
CM_ SG_ 97 L_2HKBD_Sw_Opt1 "2HKBD_Switch_Option1";
CM_ SG_ 97 L_2HKBD_Typ2 "2HKBD_Type2";
CM_ SG_ 97 L_2HKBD_Typ3 "2HKBD_Type3";
CM_ SG_ 97 L_2HKBD_SW_Ver1 "2HKBD_SoftWare_Version1";
CM_ SG_ 97 L_2HKBD_SW_Ver2 "2HKBD_SoftWare_Version2";
CM_ SG_ 97 L_2HKBD_SW_Ver3 "2HKBD_SoftWare_Version3";
CM_ SG_ 97 L_2HKBD_Typ1 "2HKBD_Type1";
CM_ BO_ 98 "[P] Periodic";
CM_ SG_ 98 L_2HKBD_Rr_EvapVolVal "2HKBD_Rear_EvaporatorVoltageValue";
CM_ SG_ 98 L_2HKBD_Rr_TempActrSt "2HKBD_Rear_TemperatureActuatorStatus";
CM_ SG_ 98 L_2HKBD_Rr_TempAsstActrFB "2HKBD_Rear_TemperatureAssistActuatorFeedback";
CM_ SG_ 98 L_2HKBD_Rr_TempAsstActrSt "2HKBD_Rear_TemperatureAssistActuatorStatus";
CM_ SG_ 98 L_2HKBD_Rr_ModeActrFB "2HKBD_Rear_ModeActuatorFeedback";
CM_ SG_ 98 L_2HKBD_Rr_ModeActrSt "2HKBD_Rear_ModeActuatorStatus";
CM_ SG_ 98 L_2HKBD_Rr_BLDCError "2HKBD_Rear_BLDCError";
CM_ SG_ 98 L_2HKBD_Rr_HVACBLDCRpmFB "2HKBD_Rear_HVACBLDCRpmFeedBack";
CM_ SG_ 98 L_2HKBD_Rr_TempActrFB "2HKBD_Rear_TemperatureActuatorFeedback";
CM_ BO_ 99 "[PE] Periodic and On Event";
CM_ SG_ 99 L_2HKBD_SwBtnTyp "2HKBD-SwitchButtonType";
CM_ SG_ 99 L_2HKBD_ResetOpSta "This signal indicates whether the reset operation has been completed or not";
CM_ BO_ 100 "[PE] Periodic and On Event";
CM_ SG_ 100 L_2HKBD_RrDrModeDnSw "2HKBD_RearDriverModeDownSwitch";
CM_ SG_ 100 L_2HKBD_RrDrModeUpSw "2HKBD_RearDriverModeUpSwitch";
CM_ SG_ 100 L_2HKBD_RrDrAutoSw "2HKBD_RearDriverAutoSwitch";
CM_ SG_ 100 L_2HKBD_Rr_OffSw "2HKBD_Rear_OffSwitch";
CM_ SG_ 100 L_2HKBD_RrSyncSw "2HKBD_Rear_SyncSwitch";
CM_ SG_ 100 L_2HKBD_RrAcSw "2HKBD_Rear_ACSwitch";
CM_ SG_ 100 L_2HKBD_RLStHtrSwReq "2HKBD_RearLeftSeatHeaterSwitchRequest";
CM_ SG_ 100 L_2HKBD_RLStVentSwReq "2HKBD_RearLeftSeatVentSwitchRequest";
CM_ SG_ 100 L_2HKBD_RRStHtrSwReq "2HKBD_RearRightSeatHeaterSwitchRequest";
CM_ SG_ 100 L_2HKBD_RRStVentSwReq "2HKBD_RearRightSeatVentSwitchRequest";
CM_ SG_ 100 L_2HKBD_RrDrMultiAutoSw "2HKBD_RearDriverMultiAutoSwitch";
CM_ SG_ 100 L_2HKBD_RrDrModeSw "2HKBD_RearDriverModeSwitch";
CM_ SG_ 100 L_2HKBD_RrPsModeSw "2HKBD_RearPassengerModeSwitch";
CM_ SG_ 100 L_2HKBD_RrPsModeDnSw "2HKBD_RearPassengerModeDownSwitch";
CM_ SG_ 100 L_2HKBD_RrPsModeUpSw "2HKBD_RearPassengerModeUpSwitch";
CM_ SG_ 100 L_2HKBD_RrPsModeVentSw "2HKBD_RearPassengerModeVentSwitch";
CM_ SG_ 100 L_2HKBD_RrPsModeFloorSw "2HKBD_RearPassengerModeFloorSwitch";
CM_ SG_ 100 L_2HKBD_RrPsModeBiLvlSw "2HKBD_RearPassengerModeBiLevelSwitch";
CM_ SG_ 100 L_2HKBD_RrPsTempDnSw "2HKBD_RearPassengerTemperatureDownSwitch";
CM_ SG_ 100 L_2HKBD_RrPsTempUpSw "2HKBD_RearPassengerTemperatureUpSwitch";
CM_ SG_ 100 L_2HKBD_RrPsBlwUpSw "2HKBD_RearPassengerBlowerUpSwitch";
CM_ SG_ 100 L_2HKBD_RrDRModeVentSw "2HKBD_RearDriverModeVentSwitch";
CM_ SG_ 100 L_2HKBD_RrPsBlwDnSw "2HKBD_RearPassengerBlowerDownSwitch";
CM_ SG_ 100 L_2HKBD_RrPsAutoSw "2HKBD_RearPassengerAutoSwitch";
CM_ SG_ 100 L_2HKBD_RrPsMultiAutoSw "2HKBD_RearPassengerMultiAutoSwitch";
CM_ SG_ 100 L_2HKBD_RrDrBlwDnOffSw "2HKBD_RearDriverBlowerDownOffSwitch";
CM_ SG_ 100 L_2HKBD_RrPsBlwDnOffSw "2HKBD_ReaerPassengerBlowerDownOffSwitch";
CM_ SG_ 100 L_2HKBD_RrOnOffSet "2HKBD_RearOnOffSet";
CM_ SG_ 100 L_2HKBD_RrDrblwUpMaxSw "L_2HKBD_RrDrblwUpMaxSw";
CM_ SG_ 100 L_2HKBD_RrDrModeFloorSw "2HKBD_RearDriverModeFloorSwitch";
CM_ SG_ 100 L_2HKBD_RrPsblwUpMaxSw "L_2HKBD_RrPsblwUpMaxSw";
CM_ SG_ 100 L_2HKBD_RrDrModeBiLvlSw "2HKBD_RearDriverModeBiLevelSwitch";
CM_ SG_ 100 L_2HKBD_RrDrTempDnSw "2HKBD_RearDriverTempDownSwitch";
CM_ SG_ 100 L_2HKBD_RrDrTempUpSw "2HKBD_RearDriverTempUpSwitch";
CM_ SG_ 100 L_2HKBD_RrDrBlwDnSw "2HKBD_RearDriverBlowerDownSwitch";
CM_ SG_ 100 L_2HKBD_RrDrBlwUpSw "2HKBD_RearDriverBlowerUpSwitch";
CM_ BO_ 101 "[P] Periodic";
CM_ SG_ 101 L_2HKBD_RrFlrDuctSnsr "2HKBD_RearFloorDuctSensor";
CM_ SG_ 101 L_2HKBD_RrVntDuctSnsr "2HKBD_RearVentDuctSensor";
CM_ BO_ 102 "[EC] On Event and On Change";
CM_ SG_ 102 L_2HKBD_RrDrTempClickCnt "2HKBD_RearDriverTempClickCount";
CM_ SG_ 102 L_2HKBD_RrPsTempClickCnt "2HKBD_RearPassengerTempClickCount";
CM_ SG_ 102 L_2HKBD_RrPsBlwrClickCnt "2HKBD_RearPassengerBlowerClickCount";
CM_ SG_ 102 L_2HKBD_RrTempKnobCnt "2HKBD_RearTemperatureKnobCount (for knobs rotate count)";
CM_ SG_ 102 L_2HKBD_RrBlwKnobCnt "2HKBD_RearBlowerKnobCount (for knobs rotate count)";
CM_ SG_ 102 L_2HKBD_RrCurtainBtn "Rear Curtain Touch Button";
CM_ SG_ 102 L_2HKBD_HVACPnlBckLight_Res "Vehicle API HVAC Control Panel BackLight Response";
CM_ SG_ 102 L_2HKBD_RrDrBlwrClickCnt "2HKBD_RearDriverBlowerClickCount";
CM_ BO_ 368 "[EC] On Event and On Change";
CM_ SG_ 368 L_ATCU_AVNCluUSMReset "Request to reset all USM service";
CM_ SG_ 368 L_ATCU_HVACPnlBckLight_Set "Vehicle API HVAC Control Panel BackLight Set";
CM_ BO_ 849 "[PE] Periodic and On Event";
CM_ SG_ 849 L_ATCU_Lib_SnsrInCarTemp "ATCU Library InCarTemp Filtering Value";
CM_ SG_ 849 L_ATCU_Lib_SnsrAMBTemp "ATCU Library AmbTemp Filtering Value";
CM_ SG_ 849 L_ATCU_Lib_SnsrDOH "ATCU Library DOH Filtering Value";
CM_ SG_ 849 L_ATCU_Lib_SnsrEvapTemp "ATCU Library EvapTemp Filtering Value";
CM_ BO_ 850 "[PE] Periodic and On Event";
CM_ SG_ 850 L_ATCU_Lib_SnsrWaterTemp "ATCU Library WaterTemp Filtering Value";
CM_ SG_ 850 L_ATCU_Lib_SnsrFineDust "ATCU Library FineDust Filtering Value";
CM_ SG_ 850 L_ATCU_Lib_SnsrLHPhoto "ATCU Library Photo Sensor(Drv) Filtering Value";
CM_ SG_ 850 L_ATCU_Lib_SnsrRHPhoto "ATCU Library Photo Sensor(Ast) Filtering Value";
CM_ BO_ 851 "[PE] Periodic and On Event";
CM_ SG_ 851 L_ATCU_Lib_SnsrDrvVentDuct "ATCU Library Driver Vent Duct Temp Filtering Value";
CM_ SG_ 851 L_ATCU_Lib_SnsrAstVentDuct "ATCU Library Assist Vent Duct Temp Filtering Value";
CM_ SG_ 851 L_ATCU_Lib_SnsrDrvFloorDuct "ATCU Library Driver Floor Duct Temp Filtering Value";
CM_ SG_ 851 L_ATCU_Lib_SnsrAstFloorDuct "ATCU Library Assist Floor Duct Temp Filtering Value";
CM_ BO_ 852 "[PE] Periodic and On Event";
CM_ SG_ 852 L_ATCU_Lib_Snsr2LHVentDuct "ATCU Library 2nd LH Vent Duct Temp Filtering Value";
CM_ SG_ 852 L_ATCU_Lib_Snsr2LHFloorDuct "ATCU Library 2nd LH Floor Duct Temp Filtering Value";
CM_ SG_ 852 L_ATCU_Lib_SnsrDEFDuct "ATCU Library DEF Duct Temp Filtering Value";
CM_ BO_ 853 "[PE] Periodic and On Event";
CM_ SG_ 853 L_ATCU_Lib_OffSw "ATCU Library Off Switch";
CM_ SG_ 853 L_ATCU_Lib_AutoSw "ATCU Library Auto Switch";
CM_ SG_ 853 L_ATCU_Lib_BlrDnOffReq "ATCU Library Blower DownOff Switch (DownOff Type)";
CM_ SG_ 853 L_ATCU_Lib_IntakeRECSw "ATCU Library Intake REC Switch (1button/2button type)";
CM_ SG_ 853 L_ATCU_Lib_IntakeFRESw "ATCU Library Intake FRE Switch (2button type)";
CM_ SG_ 853 L_ATCU_Lib_ACSw "ATCU Library AC Switch";
CM_ SG_ 853 L_ATCU_Lib_DEFSw "ATCU Library DEF Switch";
CM_ SG_ 853 L_ATCU_Lib_DrvTempUpSw "ATCU Library Driverside Temp Up Switch";
CM_ SG_ 853 L_ATCU_Lib_DrvTempDnSw "ATCU Library Driverside Temp Down Switch";
CM_ SG_ 853 L_ATCU_Lib_AstTempUpSw "ATCU Library Assistside Temp Up Switch";
CM_ SG_ 853 L_ATCU_Lib_AstTempDnSw "ATCU Library Assistside Temp Down Switch";
CM_ SG_ 853 L_ATCU_Lib_SyncSw "ATCU Library Sync Switch";
CM_ SG_ 853 L_ATCU_Lib_ModSw "ATCU Library Mode Switch (1button type)";
CM_ SG_ 853 L_ATCU_Lib_DrvOnlySw "ATCU Library DriverOnly Switch";
CM_ SG_ 853 L_ATCU_Lib_ClimateSw "ATCU Library Climate Switch";
CM_ SG_ 853 L_ATCU_Lib_RearDEFSw "ATCU Library RearDEF Switch";
CM_ SG_ 853 L_ATCU_Lib_StrWhlSw "ATCU Library SteeringWheel Heater Switch";
CM_ SG_ 853 L_ATCU_Lib_DrvSeatHeatSw "ATCU Library Driverside Seat Heater Switch";
CM_ SG_ 853 L_ATCU_Lib_DrvSeatVentSw "ATCU Library Driverside Seat Vent Switch";
CM_ SG_ 853 L_ATCU_Lib_AstSeatHeatSw "ATCU Library Assistside Seat Heater Switch";
CM_ SG_ 853 L_ATCU_Lib_AstSeatVentSw "ATCU Library Assistside Seat Vent Switch";
CM_ SG_ 853 L_ATCU_Lib_DrvSeatTumblerSw "ATCU Library Driverside Seat Tumbler Switch";
CM_ SG_ 853 L_ATCU_Lib_ModUpSw "ATCU Library Mode Up Switch (2button type)";
CM_ SG_ 853 L_ATCU_Lib_AstSeatTumblerSw "ATCU Library Assistside Seat Tumbler Switch";
CM_ SG_ 853 L_ATCU_Lib_ModDnSw "ATCU Library Mode Down Switch (2button type)";
CM_ SG_ 853 L_ATCU_Lib_BlrUpSw "ATCU Library Blower Up Switch";
CM_ SG_ 853 L_ATCU_Lib_BlrDnSw "ATCU Library Blower Down Switch";
CM_ BO_ 854 "[PE] Periodic and On Event";
CM_ SG_ 854 L_ATCU_Lib_OffSetSw "ATCU Library Off Set Switch";
CM_ SG_ 854 L_ATCU_Lib_BlrSetSw "ATCU Library Blower Set Switch";
CM_ SG_ 854 L_ATCU_Lib_AutoSetSw "ATCU Library Auto Set Switch";
CM_ SG_ 854 L_ATCU_Lib_DEFSetSw "ATCU Library DEF Set Switch";
CM_ SG_ 854 L_ATCU_Lib_SyncSetSw "ATCU Library Sync Set Switch";
CM_ SG_ 854 L_ATCU_Lib_IntakeSetSw "ATCU Library Intake Set Switch";
CM_ SG_ 854 L_ATCU_Lib_DrvTempSetSw "ATCU Library Driverside Temp Set Switch";
CM_ SG_ 854 L_ATCU_Lib_MultiAutoSetSw "ATCU Library MultiAuto Set Switch";
CM_ SG_ 854 L_ATCU_Lib_AstTempSetSw "ATCU Library Assistside Temp Set Switch";
CM_ SG_ 854 L_ATCU_Lib_DrvOnlySetSw "ATCU Library DriverOnly Set Switch";
CM_ SG_ 854 L_ATCU_Lib_DrvTempClickCnt "ATCU Library Driverside Temp Switch";
CM_ SG_ 854 L_ATCU_Lib_AstTempClickCnt "ATCU Library Driverside Temp Switch";
CM_ SG_ 854 L_ATCU_Lib_ACSetSw "ATCU Library AC Set Switch";
CM_ SG_ 854 L_ATCU_Lib_ModSetSw "ATCU Library Mode Set Switch";
CM_ BO_ 855 "[PE] Periodic and On Event";
CM_ SG_ 855 L_ATCU_Lib_2ndAutoSw "ATCU Library 2nd Auto Switch";
CM_ SG_ 855 L_ATCU_Lib_2ndAutoUpSw "ATCU Library 2nd Auto Up Switch";
CM_ SG_ 855 L_ATCU_Lib_2LHTempUpSw "ATCU Library 2nd Leftside Temp Up Switch";
CM_ SG_ 855 L_ATCU_Lib_2LHTempDnSw "ATCU Library 2nd Leftside Temp Down Switch";
CM_ SG_ 855 L_ATCU_Lib_2RHTempUpSw "ATCU Library 2nd Rightside Temp Up Switch";
CM_ SG_ 855 L_ATCU_Lib_2RHTempDnSw "ATCU Library 2nd Rightside Temp Down Switch";
CM_ SG_ 855 L_ATCU_Lib_2ndSyncSw "ATCU Library 2nd Sync Switch";
CM_ SG_ 855 L_ATCU_Lib_2ndLockSw "ATCU Library 2nd Lock Switch";
CM_ SG_ 855 L_ATCU_Lib_2LHSeatHeatSw "ATCU Library 2nd Leftside Seat Heater Switch";
CM_ SG_ 855 L_ATCU_Lib_2LHSeatVentSw "ATCU Library 2nd Leftside Seat Vent Switch";
CM_ SG_ 855 L_ATCU_Lib_2RHSeatHeatSw "ATCU Library 2nd Rightside Seat Heater Switch";
CM_ SG_ 855 L_ATCU_Lib_2RHSeatVentSw "ATCU Library 2nd Rightside Seat Vent Switch";
CM_ SG_ 855 L_ATCU_Lib_2ndAutoDnSw "ATCU Library 2nd Auto Down Switch";
CM_ SG_ 855 L_ATCU_Lib_2LHSeatTumblerSw "ATCU Library 2nd Leftside Seat Tumbler Switch";
CM_ SG_ 855 L_ATCU_Lib_2RHSeatTumblerSw "ATCU Library 2nd Rightside Seat Tumbler Switch";
CM_ SG_ 855 L_ATCU_Lib_2ndOffSetSw "ATCU Library 2nd Off Set Switch";
CM_ SG_ 855 L_ATCU_Lib_2ndAutoSetSw "ATCU Library 2nd Auto Set Switch";
CM_ SG_ 855 L_ATCU_Lib_2ndMultiAutoSetSw "ATCU Library 2nd MultiAuto Set Switch";
CM_ SG_ 855 L_ATCU_Lib_2LHModSw "ATCU Library 2nd Mode Switch";
CM_ SG_ 855 L_ATCU_Lib_2ndACSetSw "ATCU Library 2nd AC Set Switch";
CM_ SG_ 855 L_ATCU_Lib_2LHModSetSw "ATCU Library 2nd Mode Set Switch";
CM_ SG_ 855 L_ATCU_Lib_2LHBlrSetSw "ATCU Library 2nd Blower Set Switch";
CM_ SG_ 855 L_ATCU_Lib_2LHModUpSw "ATCU Library 2nd Mode Up Switch";
CM_ SG_ 855 L_ATCU_Lib_2LHTempSetSw "ATCU Library 2nd Leftside Temp Set Switch";
CM_ SG_ 855 L_ATCU_Lib_2ndSyncSetSw "ATCU Library 2nd Sync Set Switch";
CM_ SG_ 855 L_ATCU_Lib_2ndOffSw "ATCU Library 2nd Off Switch";
CM_ SG_ 855 L_ATCU_Lib_2RHTempSetSw "ATCU Library 2nd Rightside Temp Set Switch";
CM_ SG_ 855 L_ATCU_Lib_2LHModDnSw "ATCU Library 2nd Mode Down Switch";
CM_ SG_ 855 L_ATCU_Lib_2ndLockSetSw "ATCU Library 2nd Lock Set Switch";
CM_ SG_ 855 L_ATCU_Lib_DrvBlrClickCnt "ATCU Library Driverside Blower Knob Click Count";
CM_ SG_ 855 L_ATCU_Lib_2LHBlrUpSw "ATCU Library 2nd Blower Up Switch";
CM_ SG_ 855 L_ATCU_Lib_2LHBlrDnSw "ATCU Library 2nd Blower Down Switch";
CM_ SG_ 855 L_ATCU_Lib_2LHBlrDnOffReq "ATCU Library 2nd Blower DownOff Switch";
CM_ SG_ 855 L_ATCU_Lib_2ndACSw "ATCU Library 2nd AC Switch";
CM_ BO_ 865 "[PE] Periodic and On Event";
CM_ SG_ 865 L_ATCU_Lib_MngrIntakeBuf0 "ATCU Library Intake Manager Buffer 0";
CM_ SG_ 865 L_ATCU_Lib_MngrIntakeBufLow1 "ATCU Library Intake Manager Lower Limit Buffer 1";
CM_ SG_ 865 L_ATCU_Lib_MngrIntakeBuf2 "ATCU Library Intake Manager Buffer 2";
CM_ SG_ 865 L_ATCU_Lib_MngrTempBuf0 "ATCU Library Temp Manager Buffer 0";
CM_ SG_ 865 L_ATCU_Lib_MngrIntakeBuf3 "ATCU Library Intake Manager Buffer 3";
CM_ SG_ 865 L_ATCU_Lib_MngrTempBuf1 "ATCU Library Temp Manager Buffer 1";
CM_ SG_ 865 L_ATCU_Lib_MngrIntakeBuf4 "ATCU Library Intake Manager Buffer 4";
CM_ SG_ 865 L_ATCU_Lib_MngrTempBuf2 "ATCU Library Temp Manager Buffer 2";
CM_ SG_ 865 L_ATCU_Lib_MngrIntakeBuf5 "ATCU Library Intake Manager Buffer 5";
CM_ SG_ 865 L_ATCU_Lib_MngrTempBuf3 "ATCU Library Temp Manager Buffer 3";
CM_ SG_ 865 L_ATCU_Lib_MngrIntakeBuf6 "ATCU Library Intake Manager Buffer 6";
CM_ SG_ 865 L_ATCU_Lib_MngrIntakeBufLow0 "ATCU Library Intake Manager Lower Limit Buffer 0";
CM_ SG_ 865 L_ATCU_Lib_MngrTempBuf4 "ATCU Library Temp Manager Buffer 4";
CM_ SG_ 865 L_ATCU_Lib_MngrIntakeBuf7 "ATCU Library Intake Manager Buffer 7";
CM_ SG_ 865 L_ATCU_Lib_MngrTempBufLow2 "ATCU Library Temp Manager Lower Limit Buffer 2";
CM_ SG_ 865 L_ATCU_Lib_MngrIntakeBuf1 "ATCU Library Intake Manager Buffer 1";
CM_ BO_ 866 "[PE] Periodic and On Event";
CM_ SG_ 866 L_ATCU_Lib_2LHMngrModBuf0 "ATCU Library 2nd Leftside Mode Manager Buffer 0";
CM_ SG_ 866 L_ATCU_Lib_2LHMngrModBuf3 "ATCU Library 2nd Leftside Mode Manager Buffer 3";
CM_ SG_ 866 L_ATCU_Lib_2LHMngrModBuf4 "ATCU Library 2nd Leftside Mode Manager Buffer 4";
CM_ SG_ 866 L_ATCU_Lib_2LHMngrModBuf5 "ATCU Library 2nd Leftside Mode Manager Buffer 5";
CM_ SG_ 866 L_ATCU_Lib_2LHMngrModBuf6 "ATCU Library 2nd Leftside Mode Manager Buffer 6";
CM_ SG_ 866 L_ATCU_Lib_2LHMngrModBuf7 "ATCU Library 2nd Leftside Mode Manager Buffer 7";
CM_ SG_ 866 L_ATCU_Lib_2LHMngrBlwBuf0 "ATCU Library 2nd Leftside Blower Manager Buffer 0";
CM_ SG_ 866 L_ATCU_Lib_2LHMngrBlwBuf1 "ATCU Library 2nd Leftside Blower Manager Buffer 1";
CM_ SG_ 866 L_ATCU_Lib_2LHMngrModBuf1 "ATCU Library 2nd Leftside Mode Manager Buffer 1";
CM_ SG_ 866 L_ATCU_Lib_2LHMngrBlwBuf2 "ATCU Library 2nd Leftside Blower Manager Buffer 2";
CM_ SG_ 866 L_ATCU_Lib_2LHMngrBlwBuf3 "ATCU Library 2nd Leftside Blower Manager Buffer 3";
CM_ SG_ 866 L_ATCU_Lib_2LHMngrBlwBuf4 "ATCU Library 2nd Leftside Blower Manager Buffer 4";
CM_ SG_ 866 L_ATCU_Lib_2LHMngrBlwBuf5 "ATCU Library 2nd Leftside Blower Manager Buffer 5";
CM_ SG_ 866 L_ATCU_Lib_2LHMngrBlwBuf6 "ATCU Library 2nd Leftside Blower Manager Buffer 6";
CM_ SG_ 866 L_ATCU_Lib_2LHMngrBlwBufHi0 "ATCU Library 2nd Leftside Blower Manager Upper Limit Buffer 0";
CM_ SG_ 866 L_ATCU_Lib_2LHMngrBlwBufHi1 "ATCU Library 2nd Leftside Blower Manager Upper Limit Buffer 1";
CM_ SG_ 866 L_ATCU_Lib_2LHMngrModBuf2 "ATCU Library 2nd Leftside Mode Manager Buffer 2";
CM_ BO_ 867 "[PE] Periodic and On Event";
CM_ SG_ 867 L_ATCU_Lib_2LHMngrTempBuf0 "ATCU Library 2nd Leftside Temp Manager Buffer 0";
CM_ SG_ 867 L_ATCU_Lib_2RHMngrTempBuf0 "ATCU Library 2nd Rightside Temp Manager Buffer 0";
CM_ SG_ 867 L_ATCU_Lib_2RHMngrTempBuf1 "ATCU Library 2nd Rightside Temp Manager Buffer 1";
CM_ SG_ 867 L_ATCU_Lib_2RHMngrTempBuf2 "ATCU Library 2nd Rightside Temp Manager Buffer 2";
CM_ SG_ 867 L_ATCU_Lib_2LHMngrTempBuf1 "ATCU Library 2nd Leftside Temp Manager Buffer 1";
CM_ SG_ 867 L_ATCU_Lib_2LHMngrTempBuf2 "ATCU Library 2nd Leftside Temp Manager Buffer 2";
CM_ BO_ 868 "[PE] Periodic and On Event";
CM_ SG_ 868 L_ATCU_Lib_SWVer "ATCU_SoftWare_Version";
CM_ SG_ 868 L_ATCU_Lib_BlrMax "ATCU Library Blower Manager Buffer Max Data";
CM_ SG_ 868 L_ATCU_Lib_ModMax "ATCU Library Mode Manager Buffer Max Data";
CM_ SG_ 868 L_ATCU_Lib_IntakeMax "ATCU Library Intake Manager Buffer Max Data";
CM_ SG_ 868 L_ATCU_Lib_ACMax "ATCU Library AC Manager Buffer Max Data";
CM_ BO_ 869 "[PE] Periodic and On Event";
CM_ SG_ 869 L_ATCU_Lib_StatMngr_Humid "ATCU StateManagement Control Data (Humid)";
CM_ BO_ 870 "[PE] Periodic and On Event";
CM_ SG_ 870 L_ATCU_Lib_StatMngr_Temp "ATCU StateManagement Control Data (Temp)";
CM_ BO_ 871 "[PE] Periodic and On Event";
CM_ SG_ 871 L_ATCU_Lib_StatMngr_SafetynCool "ATCU StateManagement Control Data (SafetynCool)";
CM_ BO_ 872 "[PE] Periodic and On Event";
CM_ SG_ 872 L_ATCU_Lib_StatMngr_Mngr "ATCU StateManagement Control Data (Mngr)";
CM_ BO_ 873 "[PE] Periodic and On Event";
CM_ SG_ 873 L_ATCU_Lib_StatMngr_Convenience "ATCU StateManagement Control Data (Convenience)";
CM_ BO_ 874 "[PE] Periodic and On Event";
CM_ SG_ 874 L_ATCU_Lib_StatMngr_AirQuality "ATCU StateManagement Control Data (AirQuality)";
CM_ BO_ 875 "[PE] Periodic and On Event";
CM_ SG_ 875 L_ATCU_Lib_StatMngr_ETC "ATCU StateManagement Control Data (ETC)";
CM_ BO_ 876 "[PE] Periodic and On Event";
CM_ SG_ 876 L_ATCU_Lib_StatMngr_FuelEfficiency "ATCU StateManagement Control Data (FuelEfficiency)";
CM_ BO_ 877 "[PE] Periodic and On Event";
CM_ SG_ 877 L_ATCU_Lib_StatMngr_Snsr "ATCU StateManagement Control Data (Snsr)";
CM_ BO_ 878 "[PE] Periodic and On Event";
CM_ SG_ 878 L_ATCU_Lib_StatMngr_2ndHumid "ATCU StateManagement Control Data (2ndHumid)";
CM_ BO_ 879 "[PE] Periodic and On Event";
CM_ SG_ 879 L_ATCU_Lib_StatMngr_2ndTemp "ATCU StateManagement Control Data (2ndTemp)";
CM_ BO_ 1040 "[EC] On Event and On Change";
CM_ SG_ 1040 L_EVNT_FrDrEVntAutoFlowOSDReq "L_EVNT_FrDrEVntAutoAirFlowHotKeySw";
CM_ SG_ 1040 L_EVNT_FrAstEVntAutoFlowOSDReq "L_EVNT_FrAstEVntAutoAirFlowHotKeySw";
CM_ BO_ 320 "[P] Periodic";
CM_ SG_ 320 FHPTC_DrRdySta "FHPTC_DrReadyStatus";
CM_ SG_ 320 FHPTC_DrOpSta "FHPTC_DrOperationStatus";
CM_ SG_ 320 FHPTC_DrCnsmptPwr_W "FHPTC_DrConsumptionPower_W";
CM_ SG_ 320 FHPTC_DrCurrent_A "FHPTC_DrCurrent_A";
CM_ SG_ 320 FHPTC_DrCoreTemp_C "FHPTC_DrCoreTemp_C";
CM_ SG_ 320 FHPTC_DrDutyFB_Pec "FHPTC_DrDutyFeedBack_Percentile";
CM_ SG_ 320 FHPTC_DrDutyFB_IGBT "FHPTC_DrDutyFeedBack_IGBT";
CM_ SG_ 320 FHPTC_DrCtrlTyp "FHPTC_DrControlType";
CM_ SG_ 320 FHPTC_DrVoltage_V "FHPTC_DrVoltage_V";
CM_ BO_ 321 "[P] Periodic";
CM_ SG_ 321 FHPTC_DrFlt "FHPTC_DrFault";
CM_ SG_ 321 FHPTC_DrFltLVLow "FHPTC_DrFaultLVLow";
CM_ SG_ 321 FHPTC_DrFailLVSnr "FHPTC_DrFailLowVoltageSensor";
CM_ SG_ 321 FHPTC_DrFailCurrentSnr "FHPTC_DrFailCurrentSensor";
CM_ SG_ 321 FHPTC_DrFailCoreTempSnr "FHPTC_DrFailCoreTempSensor";
CM_ SG_ 321 FHPTC_DrFailPcbTempSnr "FHPTC_DrFailPcbTempSensor";
CM_ SG_ 321 FHPTC_DrFailIGBT "FHPTC_DrFailIGBT";
CM_ SG_ 321 FHPTC_DrFailOpenLoad "FHPTC_DrFailOpenLoad";
CM_ SG_ 321 FHPTC_DrLtdOpCause "FHPTC_DrLtdOperationCauseFlag";
CM_ SG_ 321 FHPTC_DrFltLVHigh "FHPTC_DrFaultLVHigh";
CM_ SG_ 321 FHPTC_DrSwVer "FHPTC_DrSoftwareVer";
CM_ SG_ 321 FHPTC_DrFltHVLow "FHPTC_DrFaultHVLow";
CM_ SG_ 321 FHPTC_CnsmptPwrTtl_W "FHPTC_ConsumptionPowerTotal_W";
CM_ SG_ 321 FHPTC_DrFltHVHigh "FHPTC_DrFaultHVHigh";
CM_ SG_ 321 FHPTC_IntlkSta "FHPTC_InterlockStatus";
CM_ SG_ 321 FHPTC_DrFltOverCurrent "FHPTC_DrFaultOverCurrent";
CM_ SG_ 321 FHPTC_DrFltThermalShutDn "FHPTC_DrFaultThermalShutDown";
CM_ SG_ 321 FHPTC_DrFltPcbThermalShutDn "FHPTC_DrFaultPcbThermalShutDown";
CM_ SG_ 321 FHPTC_DrFltMsgTmOutATCU "FHPTC_DrFaultMassgeTimemOutATCU";
CM_ SG_ 321 FHPTC_DrFailHVSnr "FHPTC_DrFailHighVoltageSensor";
CM_ BO_ 322 "[P] Periodic";
CM_ SG_ 322 FHPTC_PassRdySta "FHPTC_PassReadyStatus";
CM_ SG_ 322 FHPTC_PassOpSta "FHPTC_PassOperationStatus";
CM_ SG_ 322 FHPTC_PassCnsmptPwr_W "FHPTC_PassConsumptionPower_W";
CM_ SG_ 322 FHPTC_PassCtrlTyp "FHPTC_PassControlType";
CM_ SG_ 322 FHPTC_PassVoltage_V "FHPTC_PassVoltage_V";
CM_ SG_ 322 FHPTC_PassCurrent_A "FHPTC_PassCurrent_A";
CM_ SG_ 322 FHPTC_PassDutyFB_Pec "FHPTC_PassDutyFB_Percentile";
CM_ SG_ 322 FHPTC_PassDutyFB_IGBT "FHPTC_PassDutyFeedBack_IGBT";
CM_ SG_ 322 FHPTC_PassCoreTemp_C "FHPTC_PassCoreTemp_C";
CM_ BO_ 323 "[P] Periodic";
CM_ SG_ 323 FHPTC_PassFlt "FHPTC_PassFault";
CM_ SG_ 323 FHPTC_PassFltLVLow "FHPTC_PassFaultLVLow";
CM_ SG_ 323 FHPTC_PassFailLVSnr "FHPTC_PassFailLVSensor";
CM_ SG_ 323 FHPTC_PassFailCurrentSnr "FHPTC_PassFailCurrentSensor";
CM_ SG_ 323 FHPTC_PassFailCoreTempSnr "FHPTC_PassFailCoreTempSensor";
CM_ SG_ 323 FHPTC_PassFailPcbTempSnr "FHPTC_PassFailPcbTempSensor";
CM_ SG_ 323 FHPTC_PassFailIGBT "FHPTC_PassFailIGBT";
CM_ SG_ 323 FHPTC_PassFailOpenLoad "FHPTC_PassFailOpenLoad";
CM_ SG_ 323 FHPTC_PassLtdOpCause "FHPTC_PassLtdOperationCause";
CM_ SG_ 323 FHPTC_PassFltLVHigh "FHPTC_PassFaultLVHigh";
CM_ SG_ 323 FHPTC_PassSwVer "FHPTC_PassSoftwareVer";
CM_ SG_ 323 FHPTC_PassFltHVLow "FHPTC_PassFaultHVLow";
CM_ SG_ 323 FHPTC_PassFltHVHigh "FHPTC_PassFaultHVHigh";
CM_ SG_ 323 FHPTC_PassFltOverCurrent "FHPTC_PassFaultOverCurrent";
CM_ SG_ 323 FHPTC_PassFltThermalShutDn "FHPTC_PassFaultThermalShutDown";
CM_ SG_ 323 FHPTC_PassFltPcbThermalShutDn "FHPTC_PassFaultPcbThermalShutDown";
CM_ SG_ 323 FHPTC_PassFltMsgTmOutATCU "FHPTC_PassFaultMessageTimeOutATCU";
CM_ SG_ 323 FHPTC_PassFailHVSnr "FHPTC_PassFailHVSensor";
CM_ BO_ 324 "[P] Periodic";
CM_ SG_ 324 FHPTC_2ndDrRdySta "FHPTC_2ndDriverReadyStatus";
CM_ SG_ 324 FHPTC_2ndDrOpSta "FHPTC_2ndDriverOperationStatus";
CM_ SG_ 324 FHPTC_2ndDrCnsmptPwr_W "FHPTC_2ndDriverConsumptionPower_W";
CM_ SG_ 324 FHPTC_2ndDrCurrent_A "FHPTC_2ndDriverCurrent_A";
CM_ SG_ 324 FHPTC_2ndDrCoreTemp_C "FHPTC_2ndDriverCoreTemp_C";
CM_ SG_ 324 FHPTC_2ndDrDutyFB_Pec "FHPTC_2ndDriverDutyFeedBack_Percentile";
CM_ SG_ 324 FHPTC_2ndDrDutyFB_IGBT "FHPTC_2ndDriverDutyFeedBack_IGBT";
CM_ SG_ 324 FHPTC_2ndDrCtrlTyp "FHPTC_2ndDriverControlType";
CM_ SG_ 324 FHPTC_2ndDrVoltage_V "FHPTC_2ndDriverVoltage_V";
CM_ BO_ 325 "[P] Periodic";
CM_ SG_ 325 FHPTC_2ndDrFlt "FHPTC_2ndDriverFault";
CM_ SG_ 325 FHPTC_2ndDrFltLVLow "FHPTC_2ndDriverFaultLVLow";
CM_ SG_ 325 FHPTC_2ndDrFailLVSnr "FHPTC_2ndDriverFailLowVoltageSensor";
CM_ SG_ 325 FHPTC_2ndDrFailCurrentSnr "FHPTC_2ndDriverFailCurrentSensor";
CM_ SG_ 325 FHPTC_2ndDrFailCoreTempSnr "FHPTC_2ndDriverFailCoreTempSensor";
CM_ SG_ 325 FHPTC_2ndDrFailPcbTempSnr "FHPTC_2ndDriverFailPcbTempSensor";
CM_ SG_ 325 FHPTC_2ndDrFailIGBT "FHPTC_2ndDriverFailIGBT";
CM_ SG_ 325 FHPTC_2ndDrFailOpenLoad "FHPTC_2ndDriverFailOpenLoad";
CM_ SG_ 325 FHPTC_2ndDrLtdOpCause "FHPTC_2ndDriverLtdOperationCauseFlag";
CM_ SG_ 325 FHPTC_2ndDrFltLVHigh "FHPTC_2ndDriverFaultLVHigh";
CM_ SG_ 325 FHPTC_2ndDrSwVer "FHPTC_2ndDriverSoftwareVer";
CM_ SG_ 325 FHPTC_2ndDrFltHVLow "FHPTC_2ndDriverFaultHVLow";
CM_ SG_ 325 FHPTC_2ndDrFltHVHigh "FHPTC_2ndDriverFaultHVHigh";
CM_ SG_ 325 FHPTC_2ndDrFltOverCurrent "FHPTC_2ndDriverFaultOverCurrent";
CM_ SG_ 325 FHPTC_2ndDrFltThermalShutDn "FHPTC_2ndDriverFaultThermalShutDown";
CM_ SG_ 325 FHPTC_2ndDrFltPcbThermalShutDn "FHPTC_2ndDriverFaultPcbThermalShutDown";
CM_ SG_ 325 FHPTC_2ndDrFltMsgTmOutATCU "FHPTC_2ndDriverFaultMassgeTimemOutATCU";
CM_ SG_ 325 FHPTC_2ndDrFailHVSnr "FHPTC_2ndDriverFailHighVoltageSensor";
CM_ BO_ 327 "[P] Periodic";
CM_ SG_ 327 FHPTC_2ndPsFlt "FHPTC_2ndPassengerFault";
CM_ SG_ 327 FHPTC_2ndPsFltLVLow "FHPTC_2ndPassengerFaultLVLow";
CM_ SG_ 327 FHPTC_2ndPsFailLVSnr "FHPTC_2ndPassengerFailLVSensor";
CM_ SG_ 327 FHPTC_2ndPsFailCurrentSnr "FHPTC_2ndPassengerFailCurrentSensor";
CM_ SG_ 327 FHPTC_2ndPsFailCoreTempSnr "FHPTC_2ndPassengerFailCoreTempSensor";
CM_ SG_ 327 FHPTC_2ndPsFailPcbTempSnr "FHPTC_2ndPassengerFailPcbTempSensor";
CM_ SG_ 327 FHPTC_2ndPsFailIGBT "FHPTC_2ndPassengerFailIGBT";
CM_ SG_ 327 FHPTC_2ndPsFailOpenLoad "FHPTC_2ndPassengerFailOpenLoad";
CM_ SG_ 327 FHPTC_2ndPsLtdOpCause "FHPTC_2ndPassengerLtdOperationCause";
CM_ SG_ 327 FHPTC_2ndPsFltLVHigh "FHPTC_2ndPassengerFaultLVHigh";
CM_ SG_ 327 FHPTC_2ndPsSwVer "FHPTC_2ndPassengerSoftwareVer";
CM_ SG_ 327 FHPTC_2ndPsFltHVLow "FHPTC_2ndPassengerFaultHVLow";
CM_ SG_ 327 FHPTC_2ndPsFltHVHigh "FHPTC_2ndPassengerFaultHVHigh";
CM_ SG_ 327 FHPTC_2ndPsFltOverCurrent "FHPTC_2ndPassengerFaultOverCurrent";
CM_ SG_ 327 FHPTC_2ndPsFltThermalShutDn "FHPTC_2ndPassengerFaultThermalShutDown";
CM_ SG_ 327 FHPTC_2ndPsFltPcbThermalShutDn "FHPTC_2ndPassengerFaultPcbThermalShutDown";
CM_ SG_ 327 FHPTC_2ndPsFltMsgTmOutATCU "FHPTC_2ndPassengerFaultMessageTimeOutATCU";
CM_ SG_ 327 FHPTC_2ndPsFailHVSnr "FHPTC_2ndPassengerFailHVSensor";
CM_ BO_ 624 "[P] Periodic";
CM_ SG_ 624 PCM_ActPosFB "Actuator Position F/B of Unit-Air Aroma";
CM_ SG_ 624 PCM_Blwr1Sta "Blower#1 Operating Status of Unit-Air Aroma";
CM_ SG_ 624 PCM_Blwr2Sta "Blower#2 Operating Status of Unit-Air Aroma";
CM_ SG_ 624 PCM_Blwr1Fail "Blower#1 Failure Flag";
CM_ SG_ 624 PCM_Blwr2Fail "Blower#2 Failure Flag";
CM_ SG_ 624 PCM_MainCtrlSta "Operation status of UAA Main Controller";
CM_ SG_ 624 PCM_Cart1Sta "Cartridge#1 Contact Status";
CM_ SG_ 624 PCM_Cart2Sta "Cartridge#2 Contact Status";
CM_ SG_ 624 PCM_Cart1Kinds "Cartridge#1 Fragnance Name";
CM_ SG_ 624 PCM_Cart2Kinds "Cartridge#2 Fragnance Name";
CM_ SG_ 624 PCM_ActSta "Actuator Operating Status of Unit-Air Aroma";
CM_ SG_ 624 PCM_ActFail "Actuator Failure Flag for Motor Stall";
CM_ BO_ 625 "[PE] Periodic and On Event";
CM_ SG_ 625 PCM_Cart1VectorX "X coordinate of Cartridge #1 for Mood Therapy";
CM_ SG_ 625 PCM_Cart1RmnPer "Percent of remaining perfume liquid of Cartridge #1";
CM_ SG_ 625 PCM_Cart1ExpSta "Status of Expiration Date of Cartridge #1";
CM_ SG_ 625 PCM_Cart1RmnDisp "Display for remaining perfume liquid of Cartridge #1";
CM_ SG_ 625 PCM_Cart1VectorY "Y coordinate of Cartridge #1 for Mood Therapy";
CM_ BO_ 626 "[PE] Periodic and On Event";
CM_ SG_ 626 PCM_Cart2VectorX "X coordinate of Cartridge #2 for Mood Therapy";
CM_ SG_ 626 PCM_Cart2RmnPer "Percent of remaining perfume liquid of Cartridge #2";
CM_ SG_ 626 PCM_Cart2ExpSta "Status of Expiration Date of Cartridge #1";
CM_ SG_ 626 PCM_Cart2RmnDisp "Display for remaining perfume liquid of Cartridge #2";
CM_ SG_ 626 PCM_Cart2VectorY "Y coordinate of Cartridge #2 for Mood Therapy";
BA_DEF_ BO_ "UsrMsgIDSforwardDeviation" INT 0 100 ;
BA_DEF_ BO_ "UsrMsgIDSbackwardDeviation" INT 50 1000 ;
BA_DEF_ BO_ "GenMsgCycleTime" INT 0 2000 ;
BA_DEF_ BO_ "GenMsgStartDelayTime" INT 0 2000 ;
BA_DEF_ BO_ "GenMsgSendType" ENUM "Cyclic","NoMsgSendType" ;
BA_DEF_ BO_ "GenMsgCycleTimeFast" INT 0 500 ;
BA_DEF_ BO_ "GenMsgDelayTime" INT 0 20 ;
BA_DEF_ BO_ "GenMsgILSupport" ENUM "No","Yes" ;
BA_DEF_ BO_ "GenMsgNrOfRepetition" INT 0 3 ;
BA_DEF_ BO_ "VFrameFormat" ENUM "StandardCAN","ExtendedCAN","reserved","reserved","reserved","reserved","reserved","reserved","reserved","reserved","reserved","reserved","reserved","reserved","StandardCAN_FD","ExtendedCAN_FD" ;
BA_DEF_ SG_ "UserSigValidity" ENUM "B+","ACC","IG","IG1","IG2","IG3","IG1 or IG2","IG1 or IG3","Undef" ;
BA_DEF_ SG_ "UsrSigPurpose" ENUM "Undef","FN","DIAG","DIAG(Req)","DIAG(Res)","DIAG(Phy)","DEV","CCP(Req)","CCP(Res)","NM","TP" ;
BA_DEF_ SG_ "GenSigStartValue" INT 0 1215752192 ;
BA_DEF_ SG_ "NetworkRequestHoldingTime" INT 0 65535 ;
BA_DEF_ SG_ "Description" STRING ;
BA_DEF_ SG_ "Version" STRING ;
BA_DEF_ SG_ "GenSigEnvVarType" ENUM "Int","Float","Undef" ;
BA_DEF_ SG_ "GenSigSendType" ENUM "Cyclic","OnWrite","OnWriteWithRepetition","OnChange","OnChangeWithRepetition","IfActive","IfActiveWithRepetition","NoSigSendType","OnChangeAndIfActive","OnChangeAndIfActiveWithRepetition" ;
BA_DEF_ SG_ "GwSigLatencyTime" INT 0 65536 ;
BA_DEF_ SG_ "GwSigMissingSourceType" ENUM "Undef","OldValue","DefaultValue","InitialValue" ;
BA_DEF_ SG_ "NWM-WakeupAllowed" ENUM "<n.a.>" ;
BA_DEF_ SG_ "RoutingFactor" INT 1 1215752192 ;
BA_DEF_REL_ BU_SG_REL_ "GenSigTimeoutTime" INT 0 7000 ;
BA_DEF_DEF_ "UsrMsgIDSforwardDeviation" 10 ;
BA_DEF_DEF_ "UsrMsgIDSbackwardDeviation" 100 ;
BA_DEF_DEF_ "GenMsgCycleTime" 200 ;
BA_DEF_DEF_ "GenMsgStartDelayTime" 0 ;
BA_DEF_DEF_ "GenMsgSendType" "NoMsgSendType" ;
BA_DEF_DEF_ "GenMsgCycleTimeFast" 40 ;
BA_DEF_DEF_ "GenMsgDelayTime" 20 ;
BA_DEF_DEF_ "GenMsgILSupport" "Yes" ;
BA_DEF_DEF_ "GenMsgNrOfRepetition" 3 ;
BA_DEF_DEF_ "VFrameFormat" "StandardCAN" ;
BA_DEF_DEF_ "UserSigValidity" "IG" ;
BA_DEF_DEF_ "UsrSigPurpose" "FN" ;
BA_DEF_DEF_ "GenSigStartValue" 0 ;
BA_DEF_DEF_ "NetworkRequestHoldingTime" 0 ;
BA_DEF_DEF_ "Description" "" ;
BA_DEF_DEF_ "Version" "" ;
BA_DEF_DEF_ "GenSigEnvVarType" "Undef" ;
BA_DEF_DEF_ "GenSigSendType" "NoSigSendType" ;
BA_DEF_DEF_ "GwSigLatencyTime" 40 ;
BA_DEF_DEF_ "GwSigMissingSourceType" "Undef" ;
BA_DEF_DEF_ "NWM-WakeupAllowed" "<n.a.>" ;
BA_DEF_DEF_ "RoutingFactor" 1 ;
BA_DEF_DEF_REL_ "GenSigTimeoutTime" 500 ;
BA_ "GenMsgSendType" BO_ 97 0;
BA_ "GenMsgCycleTime" BO_ 97 500;
BA_ "Description" SG_ 97 L_2HKBD_Sw_Opt1 "Bit0~2:RESERVED

Bit3~4:(Type):0 - None/1 - ATC/2 - MTC 

Bit5~7:RESERVED";
BA_ "GenSigSendType" SG_ 97 L_2HKBD_Sw_Opt1 4;
BA_ "UserSigValidity" SG_ 97 L_2HKBD_Sw_Opt1 7;
BA_REL_ "GenSigTimeoutTime" BU_SG_REL_ L_ATCU SG_ 97 L_2HKBD_Sw_Opt1 5000;
BA_ "Version" SG_ 97 L_2HKBD_Sw_Opt1 "23.11.09";
BA_ "Description" SG_ 97 L_2HKBD_Typ2 "Bit 0 : 2nd ROOF DR DUCT Snsr : 0 ? Not Apply / 1 ? Apply

Bit 1 : 2nd ROOF Ast DUCT Snsr : 0 ? Not Apply / 1 ? Apply

Bit 2 : 2nd FLOOR DR DUCT Snsr : 0 ? Not Apply / 1 ? Apply

Bit 3 : 2nd FLOOR Ast DUCT Snsr : 0 ? Not Apply / 1 - Apply

Bit 4 : RESERVED

Bit 5~6 (2nd Multi Auto Text):0 - Multi Auto State Text Not Applied/1 - Multi Auto State Text Display Only Applied/2 - Multi Auto State Text Display & Control Applied/3 ? RESERVED

Bit7:(2nd REAR LOCK):0 ? NON REAR LOCK/1 ? REAR LOCK";
BA_ "GenSigSendType" SG_ 97 L_2HKBD_Typ2 4;
BA_ "UserSigValidity" SG_ 97 L_2HKBD_Typ2 7;
BA_REL_ "GenSigTimeoutTime" BU_SG_REL_ L_ATCU SG_ 97 L_2HKBD_Typ2 5000;
BA_ "Version" SG_ 97 L_2HKBD_Typ2 "24.11.00";
BA_ "Description" SG_ 97 L_2HKBD_Typ3 "Bit 0~1 (2nd Rear Ps Auto Step):0 ? None/1 ? Single(On/Off)/2 ? 2 Step Type (High/Low/Off)/3 ? 3 Step Type(High/Medium/Low/Off)

Bit 2~3 RESERVED

Bit 4~5 (2nd Rear Ps Multi Auto Text):0 - Multi Auto State Text Not Applied/1 - Multi Auto State Text Display Only Applied/2 - Multi Auto State Text Display & Control Applied/3 ? RESERVED";
BA_ "GenSigSendType" SG_ 97 L_2HKBD_Typ3 4;
BA_ "UserSigValidity" SG_ 97 L_2HKBD_Typ3 7;
BA_REL_ "GenSigTimeoutTime" BU_SG_REL_ L_ATCU SG_ 97 L_2HKBD_Typ3 5000;
BA_ "Version" SG_ 97 L_2HKBD_Typ3 "24.02.01";
BA_ "GenSigSendType" SG_ 97 L_2HKBD_SW_Ver1 4;
BA_ "UserSigValidity" SG_ 97 L_2HKBD_SW_Ver1 7;
BA_REL_ "GenSigTimeoutTime" BU_SG_REL_ L_ATCU_vMON SG_ 97 L_2HKBD_SW_Ver1 5000;
BA_ "Version" SG_ 97 L_2HKBD_SW_Ver1 "25.05.04";
BA_ "GenSigSendType" SG_ 97 L_2HKBD_SW_Ver2 4;
BA_ "UserSigValidity" SG_ 97 L_2HKBD_SW_Ver2 7;
BA_REL_ "GenSigTimeoutTime" BU_SG_REL_ L_ATCU_vMON SG_ 97 L_2HKBD_SW_Ver2 5000;
BA_ "Version" SG_ 97 L_2HKBD_SW_Ver2 "25.05.04";
BA_ "GenSigSendType" SG_ 97 L_2HKBD_SW_Ver3 4;
BA_ "UserSigValidity" SG_ 97 L_2HKBD_SW_Ver3 7;
BA_REL_ "GenSigTimeoutTime" BU_SG_REL_ L_ATCU_vMON SG_ 97 L_2HKBD_SW_Ver3 5000;
BA_ "Version" SG_ 97 L_2HKBD_SW_Ver3 "25.05.04";
BA_ "Description" SG_ 97 L_2HKBD_Typ1 "Bit 0~7 : RESERVED";
BA_ "GenSigSendType" SG_ 97 L_2HKBD_Typ1 4;
BA_ "UserSigValidity" SG_ 97 L_2HKBD_Typ1 7;
BA_REL_ "GenSigTimeoutTime" BU_SG_REL_ L_ATCU SG_ 97 L_2HKBD_Typ1 5000;
BA_ "Version" SG_ 97 L_2HKBD_Typ1 "24.02.01";
BA_ "GenMsgSendType" BO_ 98 0;
BA_ "GenMsgCycleTime" BO_ 98 20;
BA_ "GenMsgCycleTimeFast" BO_ 98 0;
BA_ "GenMsgNrOfRepetition" BO_ 98 0;
BA_ "GenMsgDelayTime" BO_ 98 0;
BA_ "UserSigValidity" SG_ 98 L_2HKBD_Rr_EvapVolVal 7;
BA_ "Version" SG_ 98 L_2HKBD_Rr_EvapVolVal "23.09.05";
BA_ "UserSigValidity" SG_ 98 L_2HKBD_Rr_TempActrSt 7;
BA_ "Version" SG_ 98 L_2HKBD_Rr_TempActrSt "23.09.01";
BA_ "UserSigValidity" SG_ 98 L_2HKBD_Rr_TempAsstActrFB 7;
BA_ "Version" SG_ 98 L_2HKBD_Rr_TempAsstActrFB "23.09.01";
BA_ "UserSigValidity" SG_ 98 L_2HKBD_Rr_TempAsstActrSt 7;
BA_ "Version" SG_ 98 L_2HKBD_Rr_TempAsstActrSt "23.09.01";
BA_ "UserSigValidity" SG_ 98 L_2HKBD_Rr_ModeActrFB 7;
BA_ "Version" SG_ 98 L_2HKBD_Rr_ModeActrFB "23.09.01";
BA_ "UserSigValidity" SG_ 98 L_2HKBD_Rr_ModeActrSt 7;
BA_ "Version" SG_ 98 L_2HKBD_Rr_ModeActrSt "23.09.01";
BA_ "UserSigValidity" SG_ 98 L_2HKBD_Rr_BLDCError 7;
BA_ "Version" SG_ 98 L_2HKBD_Rr_BLDCError "23.09.01";
BA_ "Description" SG_ 98 L_2HKBD_Rr_HVACBLDCRpmFB "00H~3E8H:RPM = Factor * Hex + Offset/3E9H ~ FFFFH:RESERVED";
BA_ "UserSigValidity" SG_ 98 L_2HKBD_Rr_HVACBLDCRpmFB 7;
BA_ "Version" SG_ 98 L_2HKBD_Rr_HVACBLDCRpmFB "23.09.05";
BA_ "UserSigValidity" SG_ 98 L_2HKBD_Rr_TempActrFB 7;
BA_ "Version" SG_ 98 L_2HKBD_Rr_TempActrFB "23.09.01";
BA_ "GenMsgSendType" BO_ 99 0;
BA_ "GenMsgCycleTime" BO_ 99 500;
BA_ "Description" SG_ 99 L_2HKBD_SwBtnTyp "Each bit for button type is defined as

0-None/1-Hardkey/2-Touch(Used Beep)/3-Touch(Not Used Beep)

Bit 0~1 : 2nd Temp Button / Bit 2~3 : 2nd Blower Button / Bit 4~5 : 2nd Mode Button / Bit 6~7 : 2nd Auto Button / Bit 8~9 : 2nd A/C Button / Bit 10~11 : 2nd Sync Button / Bit 12~13 : 2nd StHeatVnt Button / Bit 14~15 : OFF / 16~19 : Reserved";
BA_ "GenSigSendType" SG_ 99 L_2HKBD_SwBtnTyp 4;
BA_ "UserSigValidity" SG_ 99 L_2HKBD_SwBtnTyp 7;
BA_REL_ "GenSigTimeoutTime" BU_SG_REL_ L_ATCU SG_ 99 L_2HKBD_SwBtnTyp 5000;
BA_ "Version" SG_ 99 L_2HKBD_SwBtnTyp "23.11.09";
BA_ "Description" SG_ 99 L_2HKBD_ResetOpSta "This signal indicates whether the reset operation has been completed or not";
BA_ "GenSigSendType" SG_ 99 L_2HKBD_ResetOpSta 4;
BA_ "UserSigValidity" SG_ 99 L_2HKBD_ResetOpSta 0;
BA_REL_ "GenSigTimeoutTime" BU_SG_REL_ L_ATCU SG_ 99 L_2HKBD_ResetOpSta 1000;
BA_ "Version" SG_ 99 L_2HKBD_ResetOpSta "24.10.05";
BA_ "GenMsgSendType" BO_ 100 0;
BA_ "GenSigSendType" SG_ 100 L_2HKBD_RrDrModeDnSw 4;
BA_ "UserSigValidity" SG_ 100 L_2HKBD_RrDrModeDnSw 7;
BA_REL_ "GenSigTimeoutTime" BU_SG_REL_ L_ATCU SG_ 100 L_2HKBD_RrDrModeDnSw 1500;
BA_ "Version" SG_ 100 L_2HKBD_RrDrModeDnSw "23.09.01";
BA_ "GenSigSendType" SG_ 100 L_2HKBD_RrDrModeUpSw 4;
BA_ "UserSigValidity" SG_ 100 L_2HKBD_RrDrModeUpSw 7;
BA_REL_ "GenSigTimeoutTime" BU_SG_REL_ L_ATCU SG_ 100 L_2HKBD_RrDrModeUpSw 1500;
BA_ "Version" SG_ 100 L_2HKBD_RrDrModeUpSw "23.09.01";
BA_ "GenSigSendType" SG_ 100 L_2HKBD_RrDrAutoSw 4;
BA_ "UserSigValidity" SG_ 100 L_2HKBD_RrDrAutoSw 7;
BA_REL_ "GenSigTimeoutTime" BU_SG_REL_ L_ATCU SG_ 100 L_2HKBD_RrDrAutoSw 1500;
BA_ "Version" SG_ 100 L_2HKBD_RrDrAutoSw "23.09.01";
BA_ "GenSigSendType" SG_ 100 L_2HKBD_Rr_OffSw 4;
BA_ "UserSigValidity" SG_ 100 L_2HKBD_Rr_OffSw 7;
BA_REL_ "GenSigTimeoutTime" BU_SG_REL_ L_ATCU SG_ 100 L_2HKBD_Rr_OffSw 1500;
BA_ "Version" SG_ 100 L_2HKBD_Rr_OffSw "23.09.01";
BA_ "GenSigSendType" SG_ 100 L_2HKBD_RrSyncSw 4;
BA_ "UserSigValidity" SG_ 100 L_2HKBD_RrSyncSw 7;
BA_REL_ "GenSigTimeoutTime" BU_SG_REL_ L_ATCU SG_ 100 L_2HKBD_RrSyncSw 1500;
BA_ "Version" SG_ 100 L_2HKBD_RrSyncSw "23.09.01";
BA_ "GenSigSendType" SG_ 100 L_2HKBD_RrAcSw 4;
BA_ "UserSigValidity" SG_ 100 L_2HKBD_RrAcSw 7;
BA_REL_ "GenSigTimeoutTime" BU_SG_REL_ L_ATCU SG_ 100 L_2HKBD_RrAcSw 1500;
BA_ "Version" SG_ 100 L_2HKBD_RrAcSw "23.09.01";
BA_ "GenSigSendType" SG_ 100 L_2HKBD_RLStHtrSwReq 4;
BA_ "UserSigValidity" SG_ 100 L_2HKBD_RLStHtrSwReq 7;
BA_REL_ "GenSigTimeoutTime" BU_SG_REL_ L_ATCU SG_ 100 L_2HKBD_RLStHtrSwReq 1500;
BA_ "Version" SG_ 100 L_2HKBD_RLStHtrSwReq "23.09.01";
BA_ "GenSigSendType" SG_ 100 L_2HKBD_RLStVentSwReq 4;
BA_ "UserSigValidity" SG_ 100 L_2HKBD_RLStVentSwReq 7;
BA_REL_ "GenSigTimeoutTime" BU_SG_REL_ L_ATCU SG_ 100 L_2HKBD_RLStVentSwReq 1500;
BA_ "Version" SG_ 100 L_2HKBD_RLStVentSwReq "23.09.01";
BA_ "GenSigSendType" SG_ 100 L_2HKBD_RRStHtrSwReq 4;
BA_ "UserSigValidity" SG_ 100 L_2HKBD_RRStHtrSwReq 7;
BA_REL_ "GenSigTimeoutTime" BU_SG_REL_ L_ATCU SG_ 100 L_2HKBD_RRStHtrSwReq 1500;
BA_ "Version" SG_ 100 L_2HKBD_RRStHtrSwReq "23.09.01";
BA_ "GenSigSendType" SG_ 100 L_2HKBD_RRStVentSwReq 4;
BA_ "UserSigValidity" SG_ 100 L_2HKBD_RRStVentSwReq 7;
BA_REL_ "GenSigTimeoutTime" BU_SG_REL_ L_ATCU SG_ 100 L_2HKBD_RRStVentSwReq 1500;
BA_ "Version" SG_ 100 L_2HKBD_RRStVentSwReq "23.09.01";
BA_ "GenSigSendType" SG_ 100 L_2HKBD_RrDrMultiAutoSw 4;
BA_ "GenSigStartValue" SG_ 100 L_2HKBD_RrDrMultiAutoSw 7;
BA_ "UserSigValidity" SG_ 100 L_2HKBD_RrDrMultiAutoSw 7;
BA_REL_ "GenSigTimeoutTime" BU_SG_REL_ L_ATCU SG_ 100 L_2HKBD_RrDrMultiAutoSw 1500;
BA_ "Version" SG_ 100 L_2HKBD_RrDrMultiAutoSw "24.01.00";
BA_ "GenSigSendType" SG_ 100 L_2HKBD_RrDrModeSw 4;
BA_ "UserSigValidity" SG_ 100 L_2HKBD_RrDrModeSw 7;
BA_REL_ "GenSigTimeoutTime" BU_SG_REL_ L_ATCU SG_ 100 L_2HKBD_RrDrModeSw 1500;
BA_ "Version" SG_ 100 L_2HKBD_RrDrModeSw "23.09.01";
BA_ "GenSigSendType" SG_ 100 L_2HKBD_RrPsModeSw 4;
BA_ "UserSigValidity" SG_ 100 L_2HKBD_RrPsModeSw 7;
BA_REL_ "GenSigTimeoutTime" BU_SG_REL_ L_ATCU SG_ 100 L_2HKBD_RrPsModeSw 1500;
BA_ "Version" SG_ 100 L_2HKBD_RrPsModeSw "23.09.01";
BA_ "GenSigSendType" SG_ 100 L_2HKBD_RrPsModeDnSw 4;
BA_ "UserSigValidity" SG_ 100 L_2HKBD_RrPsModeDnSw 7;
BA_REL_ "GenSigTimeoutTime" BU_SG_REL_ L_ATCU SG_ 100 L_2HKBD_RrPsModeDnSw 1500;
BA_ "Version" SG_ 100 L_2HKBD_RrPsModeDnSw "23.09.01";
BA_ "GenSigSendType" SG_ 100 L_2HKBD_RrPsModeUpSw 4;
BA_ "UserSigValidity" SG_ 100 L_2HKBD_RrPsModeUpSw 7;
BA_REL_ "GenSigTimeoutTime" BU_SG_REL_ L_ATCU SG_ 100 L_2HKBD_RrPsModeUpSw 1500;
BA_ "Version" SG_ 100 L_2HKBD_RrPsModeUpSw "23.09.01";
BA_ "GenSigSendType" SG_ 100 L_2HKBD_RrPsModeVentSw 4;
BA_ "UserSigValidity" SG_ 100 L_2HKBD_RrPsModeVentSw 7;
BA_REL_ "GenSigTimeoutTime" BU_SG_REL_ L_ATCU SG_ 100 L_2HKBD_RrPsModeVentSw 1500;
BA_ "Version" SG_ 100 L_2HKBD_RrPsModeVentSw "23.09.01";
BA_ "GenSigSendType" SG_ 100 L_2HKBD_RrPsModeFloorSw 4;
BA_ "UserSigValidity" SG_ 100 L_2HKBD_RrPsModeFloorSw 7;
BA_REL_ "GenSigTimeoutTime" BU_SG_REL_ L_ATCU SG_ 100 L_2HKBD_RrPsModeFloorSw 1500;
BA_ "Version" SG_ 100 L_2HKBD_RrPsModeFloorSw "23.09.01";
BA_ "GenSigSendType" SG_ 100 L_2HKBD_RrPsModeBiLvlSw 4;
BA_ "UserSigValidity" SG_ 100 L_2HKBD_RrPsModeBiLvlSw 7;
BA_REL_ "GenSigTimeoutTime" BU_SG_REL_ L_ATCU SG_ 100 L_2HKBD_RrPsModeBiLvlSw 1500;
BA_ "Version" SG_ 100 L_2HKBD_RrPsModeBiLvlSw "23.09.01";
BA_ "GenSigSendType" SG_ 100 L_2HKBD_RrPsTempDnSw 4;
BA_ "UserSigValidity" SG_ 100 L_2HKBD_RrPsTempDnSw 7;
BA_REL_ "GenSigTimeoutTime" BU_SG_REL_ L_ATCU SG_ 100 L_2HKBD_RrPsTempDnSw 1500;
BA_ "Version" SG_ 100 L_2HKBD_RrPsTempDnSw "23.09.01";
BA_ "GenSigSendType" SG_ 100 L_2HKBD_RrPsTempUpSw 4;
BA_ "UserSigValidity" SG_ 100 L_2HKBD_RrPsTempUpSw 7;
BA_REL_ "GenSigTimeoutTime" BU_SG_REL_ L_ATCU SG_ 100 L_2HKBD_RrPsTempUpSw 1500;
BA_ "Version" SG_ 100 L_2HKBD_RrPsTempUpSw "23.09.01";
BA_ "GenSigSendType" SG_ 100 L_2HKBD_RrPsBlwUpSw 4;
BA_ "UserSigValidity" SG_ 100 L_2HKBD_RrPsBlwUpSw 7;
BA_REL_ "GenSigTimeoutTime" BU_SG_REL_ L_ATCU SG_ 100 L_2HKBD_RrPsBlwUpSw 1500;
BA_ "Version" SG_ 100 L_2HKBD_RrPsBlwUpSw "23.09.01";
BA_ "GenSigSendType" SG_ 100 L_2HKBD_RrDRModeVentSw 4;
BA_ "UserSigValidity" SG_ 100 L_2HKBD_RrDRModeVentSw 7;
BA_REL_ "GenSigTimeoutTime" BU_SG_REL_ L_ATCU SG_ 100 L_2HKBD_RrDRModeVentSw 1500;
BA_ "Version" SG_ 100 L_2HKBD_RrDRModeVentSw "23.09.01";
BA_ "GenSigSendType" SG_ 100 L_2HKBD_RrPsBlwDnSw 4;
BA_ "UserSigValidity" SG_ 100 L_2HKBD_RrPsBlwDnSw 7;
BA_REL_ "GenSigTimeoutTime" BU_SG_REL_ L_ATCU SG_ 100 L_2HKBD_RrPsBlwDnSw 1500;
BA_ "Version" SG_ 100 L_2HKBD_RrPsBlwDnSw "23.09.01";
BA_ "GenSigSendType" SG_ 100 L_2HKBD_RrPsAutoSw 4;
BA_ "UserSigValidity" SG_ 100 L_2HKBD_RrPsAutoSw 7;
BA_REL_ "GenSigTimeoutTime" BU_SG_REL_ L_ATCU SG_ 100 L_2HKBD_RrPsAutoSw 1500;
BA_ "Version" SG_ 100 L_2HKBD_RrPsAutoSw "23.09.01";
BA_ "GenSigSendType" SG_ 100 L_2HKBD_RrPsMultiAutoSw 4;
BA_ "GenSigStartValue" SG_ 100 L_2HKBD_RrPsMultiAutoSw 7;
BA_ "UserSigValidity" SG_ 100 L_2HKBD_RrPsMultiAutoSw 7;
BA_REL_ "GenSigTimeoutTime" BU_SG_REL_ L_ATCU SG_ 100 L_2HKBD_RrPsMultiAutoSw 1500;
BA_ "Version" SG_ 100 L_2HKBD_RrPsMultiAutoSw "24.01.00";
BA_ "GenSigSendType" SG_ 100 L_2HKBD_RrDrBlwDnOffSw 4;
BA_ "UserSigValidity" SG_ 100 L_2HKBD_RrDrBlwDnOffSw 7;
BA_REL_ "GenSigTimeoutTime" BU_SG_REL_ L_ATCU SG_ 100 L_2HKBD_RrDrBlwDnOffSw 1500;
BA_ "Version" SG_ 100 L_2HKBD_RrDrBlwDnOffSw "23.09.01";
BA_ "GenSigSendType" SG_ 100 L_2HKBD_RrPsBlwDnOffSw 4;
BA_ "UserSigValidity" SG_ 100 L_2HKBD_RrPsBlwDnOffSw 7;
BA_REL_ "GenSigTimeoutTime" BU_SG_REL_ L_ATCU SG_ 100 L_2HKBD_RrPsBlwDnOffSw 1500;
BA_ "Version" SG_ 100 L_2HKBD_RrPsBlwDnOffSw "23.09.01";
BA_ "GenSigSendType" SG_ 100 L_2HKBD_RrOnOffSet 4;
BA_ "UserSigValidity" SG_ 100 L_2HKBD_RrOnOffSet 7;
BA_REL_ "GenSigTimeoutTime" BU_SG_REL_ L_ATCU SG_ 100 L_2HKBD_RrOnOffSet 1500;
BA_ "Version" SG_ 100 L_2HKBD_RrOnOffSet "23.09.01";
BA_ "GenSigSendType" SG_ 100 L_2HKBD_RrDrblwUpMaxSw 4;
BA_ "UserSigValidity" SG_ 100 L_2HKBD_RrDrblwUpMaxSw 7;
BA_REL_ "GenSigTimeoutTime" BU_SG_REL_ L_ATCU SG_ 100 L_2HKBD_RrDrblwUpMaxSw 1500;
BA_ "Version" SG_ 100 L_2HKBD_RrDrblwUpMaxSw "25.05.04";
BA_ "GenSigSendType" SG_ 100 L_2HKBD_RrDrModeFloorSw 4;
BA_ "UserSigValidity" SG_ 100 L_2HKBD_RrDrModeFloorSw 7;
BA_REL_ "GenSigTimeoutTime" BU_SG_REL_ L_ATCU SG_ 100 L_2HKBD_RrDrModeFloorSw 1500;
BA_ "Version" SG_ 100 L_2HKBD_RrDrModeFloorSw "23.09.01";
BA_ "GenSigSendType" SG_ 100 L_2HKBD_RrPsblwUpMaxSw 4;
BA_ "UserSigValidity" SG_ 100 L_2HKBD_RrPsblwUpMaxSw 7;
BA_REL_ "GenSigTimeoutTime" BU_SG_REL_ L_ATCU SG_ 100 L_2HKBD_RrPsblwUpMaxSw 1500;
BA_ "Version" SG_ 100 L_2HKBD_RrPsblwUpMaxSw "25.05.04";
BA_ "GenSigSendType" SG_ 100 L_2HKBD_RrDrModeBiLvlSw 4;
BA_ "UserSigValidity" SG_ 100 L_2HKBD_RrDrModeBiLvlSw 7;
BA_REL_ "GenSigTimeoutTime" BU_SG_REL_ L_ATCU SG_ 100 L_2HKBD_RrDrModeBiLvlSw 1500;
BA_ "Version" SG_ 100 L_2HKBD_RrDrModeBiLvlSw "23.09.01";
BA_ "GenSigSendType" SG_ 100 L_2HKBD_RrDrTempDnSw 4;
BA_ "UserSigValidity" SG_ 100 L_2HKBD_RrDrTempDnSw 7;
BA_REL_ "GenSigTimeoutTime" BU_SG_REL_ L_ATCU SG_ 100 L_2HKBD_RrDrTempDnSw 1500;
BA_ "Version" SG_ 100 L_2HKBD_RrDrTempDnSw "23.09.01";
BA_ "GenSigSendType" SG_ 100 L_2HKBD_RrDrTempUpSw 4;
BA_ "UserSigValidity" SG_ 100 L_2HKBD_RrDrTempUpSw 7;
BA_REL_ "GenSigTimeoutTime" BU_SG_REL_ L_ATCU SG_ 100 L_2HKBD_RrDrTempUpSw 1500;
BA_ "Version" SG_ 100 L_2HKBD_RrDrTempUpSw "23.09.01";
BA_ "GenSigSendType" SG_ 100 L_2HKBD_RrDrBlwDnSw 4;
BA_ "UserSigValidity" SG_ 100 L_2HKBD_RrDrBlwDnSw 7;
BA_REL_ "GenSigTimeoutTime" BU_SG_REL_ L_ATCU SG_ 100 L_2HKBD_RrDrBlwDnSw 1500;
BA_ "Version" SG_ 100 L_2HKBD_RrDrBlwDnSw "23.09.01";
BA_ "GenSigSendType" SG_ 100 L_2HKBD_RrDrBlwUpSw 4;
BA_ "UserSigValidity" SG_ 100 L_2HKBD_RrDrBlwUpSw 7;
BA_REL_ "GenSigTimeoutTime" BU_SG_REL_ L_ATCU SG_ 100 L_2HKBD_RrDrBlwUpSw 1500;
BA_ "Version" SG_ 100 L_2HKBD_RrDrBlwUpSw "23.09.01";
BA_ "GenMsgSendType" BO_ 101 0;
BA_ "GenMsgCycleTime" BO_ 101 20;
BA_ "GenMsgCycleTimeFast" BO_ 101 0;
BA_ "GenMsgNrOfRepetition" BO_ 101 0;
BA_ "GenMsgDelayTime" BO_ 101 0;
BA_ "UserSigValidity" SG_ 101 L_2HKBD_RrFlrDuctSnsr 7;
BA_ "Version" SG_ 101 L_2HKBD_RrFlrDuctSnsr "23.09.05";
BA_ "UserSigValidity" SG_ 101 L_2HKBD_RrVntDuctSnsr 7;
BA_ "Version" SG_ 101 L_2HKBD_RrVntDuctSnsr "23.09.05";
BA_ "GenMsgCycleTime" BO_ 102 0;
BA_ "GenSigSendType" SG_ 102 L_2HKBD_RrDrTempClickCnt 4;
BA_ "GenSigStartValue" SG_ 102 L_2HKBD_RrDrTempClickCnt 255;
BA_ "UserSigValidity" SG_ 102 L_2HKBD_RrDrTempClickCnt 7;
BA_REL_ "GenSigTimeoutTime" BU_SG_REL_ L_ATCU SG_ 102 L_2HKBD_RrDrTempClickCnt 0;
BA_ "Version" SG_ 102 L_2HKBD_RrDrTempClickCnt "24.01.00";
BA_ "GenSigSendType" SG_ 102 L_2HKBD_RrPsTempClickCnt 4;
BA_ "GenSigStartValue" SG_ 102 L_2HKBD_RrPsTempClickCnt 255;
BA_ "UserSigValidity" SG_ 102 L_2HKBD_RrPsTempClickCnt 7;
BA_REL_ "GenSigTimeoutTime" BU_SG_REL_ L_ATCU SG_ 102 L_2HKBD_RrPsTempClickCnt 0;
BA_ "Version" SG_ 102 L_2HKBD_RrPsTempClickCnt "24.01.00";
BA_ "GenSigSendType" SG_ 102 L_2HKBD_RrPsBlwrClickCnt 4;
BA_ "GenSigStartValue" SG_ 102 L_2HKBD_RrPsBlwrClickCnt 255;
BA_ "UserSigValidity" SG_ 102 L_2HKBD_RrPsBlwrClickCnt 7;
BA_REL_ "GenSigTimeoutTime" BU_SG_REL_ L_ATCU SG_ 102 L_2HKBD_RrPsBlwrClickCnt 0;
BA_ "Version" SG_ 102 L_2HKBD_RrPsBlwrClickCnt "24.01.00";
BA_ "GenSigSendType" SG_ 102 L_2HKBD_RrTempKnobCnt 4;
BA_ "GenSigStartValue" SG_ 102 L_2HKBD_RrTempKnobCnt 3;
BA_ "UserSigValidity" SG_ 102 L_2HKBD_RrTempKnobCnt 7;
BA_REL_ "GenSigTimeoutTime" BU_SG_REL_ L_ATCU SG_ 102 L_2HKBD_RrTempKnobCnt 0;
BA_ "Version" SG_ 102 L_2HKBD_RrTempKnobCnt "24.01.00";
BA_ "GenSigSendType" SG_ 102 L_2HKBD_RrBlwKnobCnt 4;
BA_ "GenSigStartValue" SG_ 102 L_2HKBD_RrBlwKnobCnt 3;
BA_ "UserSigValidity" SG_ 102 L_2HKBD_RrBlwKnobCnt 7;
BA_REL_ "GenSigTimeoutTime" BU_SG_REL_ L_ATCU SG_ 102 L_2HKBD_RrBlwKnobCnt 0;
BA_ "Version" SG_ 102 L_2HKBD_RrBlwKnobCnt "24.01.00";
BA_ "Description" SG_ 102 L_2HKBD_RrCurtainBtn "Rear Curtain Touch Button";
BA_ "GenSigSendType" SG_ 102 L_2HKBD_RrCurtainBtn 4;
BA_ "UserSigValidity" SG_ 102 L_2HKBD_RrCurtainBtn 7;
BA_REL_ "GenSigTimeoutTime" BU_SG_REL_ L_ATCU SG_ 102 L_2HKBD_RrCurtainBtn 0;
BA_ "Version" SG_ 102 L_2HKBD_RrCurtainBtn "25.08.06";
BA_ "Description" SG_ 102 L_2HKBD_HVACPnlBckLight_Res "Vehicle API HVAC Control Panel BackLight Response";
BA_ "GenSigSendType" SG_ 102 L_2HKBD_HVACPnlBckLight_Res 4;
BA_ "UserSigValidity" SG_ 102 L_2HKBD_HVACPnlBckLight_Res 7;
BA_REL_ "GenSigTimeoutTime" BU_SG_REL_ L_ATCU SG_ 102 L_2HKBD_HVACPnlBckLight_Res 0;
BA_ "Version" SG_ 102 L_2HKBD_HVACPnlBckLight_Res "25.08.06";
BA_ "GenSigSendType" SG_ 102 L_2HKBD_RrDrBlwrClickCnt 4;
BA_ "GenSigStartValue" SG_ 102 L_2HKBD_RrDrBlwrClickCnt 255;
BA_ "UserSigValidity" SG_ 102 L_2HKBD_RrDrBlwrClickCnt 7;
BA_REL_ "GenSigTimeoutTime" BU_SG_REL_ L_ATCU SG_ 102 L_2HKBD_RrDrBlwrClickCnt 0;
BA_ "Version" SG_ 102 L_2HKBD_RrDrBlwrClickCnt "24.01.00";
BA_ "GenMsgCycleTime" BO_ 368 0;
BA_ "GenSigSendType" SG_ 368 L_ATCU_AVNCluUSMReset 4;
BA_ "UserSigValidity" SG_ 368 L_ATCU_AVNCluUSMReset 7;
BA_REL_ "GenSigTimeoutTime" BU_SG_REL_ L_2HKBD SG_ 368 L_ATCU_AVNCluUSMReset 0;
BA_REL_ "GenSigTimeoutTime" BU_SG_REL_ L_3HKBD SG_ 368 L_ATCU_AVNCluUSMReset 0;
BA_REL_ "GenSigTimeoutTime" BU_SG_REL_ L_EVNT SG_ 368 L_ATCU_AVNCluUSMReset 0;
BA_REL_ "GenSigTimeoutTime" BU_SG_REL_ L_HKBD SG_ 368 L_ATCU_AVNCluUSMReset 0;
BA_ "Version" SG_ 368 L_ATCU_AVNCluUSMReset "25.08.06";
BA_ "GenSigSendType" SG_ 368 L_ATCU_HVACPnlBckLight_Set 4;
BA_ "UserSigValidity" SG_ 368 L_ATCU_HVACPnlBckLight_Set 7;
BA_REL_ "GenSigTimeoutTime" BU_SG_REL_ L_2HKBD SG_ 368 L_ATCU_HVACPnlBckLight_Set 0;
BA_REL_ "GenSigTimeoutTime" BU_SG_REL_ L_3HKBD SG_ 368 L_ATCU_HVACPnlBckLight_Set 0;
BA_REL_ "GenSigTimeoutTime" BU_SG_REL_ L_EVNT SG_ 368 L_ATCU_HVACPnlBckLight_Set 0;
BA_REL_ "GenSigTimeoutTime" BU_SG_REL_ L_HKBD SG_ 368 L_ATCU_HVACPnlBckLight_Set 0;
BA_ "Version" SG_ 368 L_ATCU_HVACPnlBckLight_Set "25.08.06";
BA_ "GenMsgSendType" BO_ 849 0;
BA_ "GenMsgCycleTime" BO_ 849 500;
BA_ "Description" SG_ 849 L_ATCU_Lib_SnsrInCarTemp "This value only use for ATCU Library data monitoring (Only use before SOP)";
BA_ "GenSigSendType" SG_ 849 L_ATCU_Lib_SnsrInCarTemp 4;
BA_ "UserSigValidity" SG_ 849 L_ATCU_Lib_SnsrInCarTemp 0;
BA_REL_ "GenSigTimeoutTime" BU_SG_REL_ L_ATCU_vMON SG_ 849 L_ATCU_Lib_SnsrInCarTemp 5000;
BA_ "Version" SG_ 849 L_ATCU_Lib_SnsrInCarTemp "23.11.10";
BA_ "Description" SG_ 849 L_ATCU_Lib_SnsrAMBTemp "This value only use for ATCU Library data monitoring (Only use before SOP)";
BA_ "GenSigSendType" SG_ 849 L_ATCU_Lib_SnsrAMBTemp 4;
BA_ "UserSigValidity" SG_ 849 L_ATCU_Lib_SnsrAMBTemp 0;
BA_REL_ "GenSigTimeoutTime" BU_SG_REL_ L_ATCU_vMON SG_ 849 L_ATCU_Lib_SnsrAMBTemp 5000;
BA_ "Version" SG_ 849 L_ATCU_Lib_SnsrAMBTemp "23.11.10";
BA_ "Description" SG_ 849 L_ATCU_Lib_SnsrDOH "This value only use for ATCU Library data monitoring (Only use before SOP)";
BA_ "GenSigSendType" SG_ 849 L_ATCU_Lib_SnsrDOH 4;
BA_ "UserSigValidity" SG_ 849 L_ATCU_Lib_SnsrDOH 0;
BA_REL_ "GenSigTimeoutTime" BU_SG_REL_ L_ATCU_vMON SG_ 849 L_ATCU_Lib_SnsrDOH 5000;
BA_ "Version" SG_ 849 L_ATCU_Lib_SnsrDOH "23.11.10";
BA_ "Description" SG_ 849 L_ATCU_Lib_SnsrEvapTemp "This value only use for ATCU Library data monitoring (Only use before SOP)";
BA_ "GenSigSendType" SG_ 849 L_ATCU_Lib_SnsrEvapTemp 4;
BA_ "UserSigValidity" SG_ 849 L_ATCU_Lib_SnsrEvapTemp 0;
BA_REL_ "GenSigTimeoutTime" BU_SG_REL_ L_ATCU_vMON SG_ 849 L_ATCU_Lib_SnsrEvapTemp 5000;
BA_ "Version" SG_ 849 L_ATCU_Lib_SnsrEvapTemp "23.11.10";
BA_ "GenMsgSendType" BO_ 850 0;
BA_ "GenMsgCycleTime" BO_ 850 500;
BA_ "Description" SG_ 850 L_ATCU_Lib_SnsrWaterTemp "This value only use for ATCU Library data monitoring (Only use before SOP)";
BA_ "GenSigSendType" SG_ 850 L_ATCU_Lib_SnsrWaterTemp 4;
BA_ "UserSigValidity" SG_ 850 L_ATCU_Lib_SnsrWaterTemp 0;
BA_REL_ "GenSigTimeoutTime" BU_SG_REL_ L_ATCU_vMON SG_ 850 L_ATCU_Lib_SnsrWaterTemp 5000;
BA_ "Version" SG_ 850 L_ATCU_Lib_SnsrWaterTemp "23.11.10";
BA_ "Description" SG_ 850 L_ATCU_Lib_SnsrFineDust "This value only use for ATCU Library data monitoring (Only use before SOP)";
BA_ "GenSigSendType" SG_ 850 L_ATCU_Lib_SnsrFineDust 4;
BA_ "UserSigValidity" SG_ 850 L_ATCU_Lib_SnsrFineDust 0;
BA_REL_ "GenSigTimeoutTime" BU_SG_REL_ L_ATCU_vMON SG_ 850 L_ATCU_Lib_SnsrFineDust 5000;
BA_ "Version" SG_ 850 L_ATCU_Lib_SnsrFineDust "23.11.10";
BA_ "Description" SG_ 850 L_ATCU_Lib_SnsrLHPhoto "This value only use for ATCU Library data monitoring (Only use before SOP)";
BA_ "GenSigSendType" SG_ 850 L_ATCU_Lib_SnsrLHPhoto 4;
BA_ "UserSigValidity" SG_ 850 L_ATCU_Lib_SnsrLHPhoto 0;
BA_REL_ "GenSigTimeoutTime" BU_SG_REL_ L_ATCU_vMON SG_ 850 L_ATCU_Lib_SnsrLHPhoto 5000;
BA_ "Version" SG_ 850 L_ATCU_Lib_SnsrLHPhoto "23.11.10";
BA_ "Description" SG_ 850 L_ATCU_Lib_SnsrRHPhoto "This value only use for ATCU Library data monitoring (Only use before SOP)";
BA_ "GenSigSendType" SG_ 850 L_ATCU_Lib_SnsrRHPhoto 4;
BA_ "UserSigValidity" SG_ 850 L_ATCU_Lib_SnsrRHPhoto 0;
BA_REL_ "GenSigTimeoutTime" BU_SG_REL_ L_ATCU_vMON SG_ 850 L_ATCU_Lib_SnsrRHPhoto 5000;
BA_ "Version" SG_ 850 L_ATCU_Lib_SnsrRHPhoto "23.11.10";
BA_ "GenMsgSendType" BO_ 851 0;
BA_ "GenMsgCycleTime" BO_ 851 500;
BA_ "Description" SG_ 851 L_ATCU_Lib_SnsrDrvVentDuct "This value only use for ATCU Library data monitoring (Only use before SOP)";
BA_ "GenSigSendType" SG_ 851 L_ATCU_Lib_SnsrDrvVentDuct 4;
BA_ "UserSigValidity" SG_ 851 L_ATCU_Lib_SnsrDrvVentDuct 0;
BA_REL_ "GenSigTimeoutTime" BU_SG_REL_ L_ATCU_vMON SG_ 851 L_ATCU_Lib_SnsrDrvVentDuct 5000;
BA_ "Version" SG_ 851 L_ATCU_Lib_SnsrDrvVentDuct "23.11.10";
BA_ "Description" SG_ 851 L_ATCU_Lib_SnsrAstVentDuct "This value only use for ATCU Library data monitoring (Only use before SOP)";
BA_ "GenSigSendType" SG_ 851 L_ATCU_Lib_SnsrAstVentDuct 4;
BA_ "UserSigValidity" SG_ 851 L_ATCU_Lib_SnsrAstVentDuct 0;
BA_REL_ "GenSigTimeoutTime" BU_SG_REL_ L_ATCU_vMON SG_ 851 L_ATCU_Lib_SnsrAstVentDuct 5000;
BA_ "Version" SG_ 851 L_ATCU_Lib_SnsrAstVentDuct "23.11.10";
BA_ "Description" SG_ 851 L_ATCU_Lib_SnsrDrvFloorDuct "This value only use for ATCU Library data monitoring (Only use before SOP)";
BA_ "GenSigSendType" SG_ 851 L_ATCU_Lib_SnsrDrvFloorDuct 4;
BA_ "UserSigValidity" SG_ 851 L_ATCU_Lib_SnsrDrvFloorDuct 0;
BA_REL_ "GenSigTimeoutTime" BU_SG_REL_ L_ATCU_vMON SG_ 851 L_ATCU_Lib_SnsrDrvFloorDuct 5000;
BA_ "Version" SG_ 851 L_ATCU_Lib_SnsrDrvFloorDuct "23.11.10";
BA_ "Description" SG_ 851 L_ATCU_Lib_SnsrAstFloorDuct "This value only use for ATCU Library data monitoring (Only use before SOP)";
BA_ "GenSigSendType" SG_ 851 L_ATCU_Lib_SnsrAstFloorDuct 4;
BA_ "UserSigValidity" SG_ 851 L_ATCU_Lib_SnsrAstFloorDuct 0;
BA_REL_ "GenSigTimeoutTime" BU_SG_REL_ L_ATCU_vMON SG_ 851 L_ATCU_Lib_SnsrAstFloorDuct 5000;
BA_ "Version" SG_ 851 L_ATCU_Lib_SnsrAstFloorDuct "23.11.10";
BA_ "GenMsgSendType" BO_ 852 0;
BA_ "GenMsgCycleTime" BO_ 852 500;
BA_ "Description" SG_ 852 L_ATCU_Lib_Snsr2LHVentDuct "This value only use for ATCU Library data monitoring (Only use before SOP)";
BA_ "GenSigSendType" SG_ 852 L_ATCU_Lib_Snsr2LHVentDuct 4;
BA_ "UserSigValidity" SG_ 852 L_ATCU_Lib_Snsr2LHVentDuct 0;
BA_REL_ "GenSigTimeoutTime" BU_SG_REL_ L_ATCU_vMON SG_ 852 L_ATCU_Lib_Snsr2LHVentDuct 5000;
BA_ "Version" SG_ 852 L_ATCU_Lib_Snsr2LHVentDuct "23.11.10";
BA_ "Description" SG_ 852 L_ATCU_Lib_Snsr2LHFloorDuct "This value only use for ATCU Library data monitoring (Only use before SOP)";
BA_ "GenSigSendType" SG_ 852 L_ATCU_Lib_Snsr2LHFloorDuct 4;
BA_ "UserSigValidity" SG_ 852 L_ATCU_Lib_Snsr2LHFloorDuct 0;
BA_REL_ "GenSigTimeoutTime" BU_SG_REL_ L_ATCU_vMON SG_ 852 L_ATCU_Lib_Snsr2LHFloorDuct 5000;
BA_ "Version" SG_ 852 L_ATCU_Lib_Snsr2LHFloorDuct "23.11.10";
BA_ "Description" SG_ 852 L_ATCU_Lib_SnsrDEFDuct "This value only use for ATCU Library data monitoring (Only use before SOP)";
BA_ "GenSigSendType" SG_ 852 L_ATCU_Lib_SnsrDEFDuct 4;
BA_ "UserSigValidity" SG_ 852 L_ATCU_Lib_SnsrDEFDuct 0;
BA_REL_ "GenSigTimeoutTime" BU_SG_REL_ L_ATCU_vMON SG_ 852 L_ATCU_Lib_SnsrDEFDuct 5000;
BA_ "Version" SG_ 852 L_ATCU_Lib_SnsrDEFDuct "23.11.10";
BA_ "GenMsgSendType" BO_ 853 0;
BA_ "GenMsgCycleTime" BO_ 853 500;
BA_ "Description" SG_ 853 L_ATCU_Lib_OffSw "This value only use for ATCU Library data monitoring (Only use before SOP)";
BA_ "GenSigSendType" SG_ 853 L_ATCU_Lib_OffSw 4;
BA_ "UserSigValidity" SG_ 853 L_ATCU_Lib_OffSw 0;
BA_REL_ "GenSigTimeoutTime" BU_SG_REL_ L_ATCU_vMON SG_ 853 L_ATCU_Lib_OffSw 5000;
BA_ "Version" SG_ 853 L_ATCU_Lib_OffSw "23.11.10";
BA_ "Description" SG_ 853 L_ATCU_Lib_AutoSw "This value only use for ATCU Library data monitoring (Only use before SOP)";
BA_ "GenSigSendType" SG_ 853 L_ATCU_Lib_AutoSw 4;
BA_ "UserSigValidity" SG_ 853 L_ATCU_Lib_AutoSw 0;
BA_REL_ "GenSigTimeoutTime" BU_SG_REL_ L_ATCU_vMON SG_ 853 L_ATCU_Lib_AutoSw 5000;
BA_ "Version" SG_ 853 L_ATCU_Lib_AutoSw "23.11.10";
BA_ "Description" SG_ 853 L_ATCU_Lib_BlrDnOffReq "This value only use for ATCU Library data monitoring (Only use before SOP)";
BA_ "GenSigSendType" SG_ 853 L_ATCU_Lib_BlrDnOffReq 4;
BA_ "UserSigValidity" SG_ 853 L_ATCU_Lib_BlrDnOffReq 0;
BA_REL_ "GenSigTimeoutTime" BU_SG_REL_ L_ATCU_vMON SG_ 853 L_ATCU_Lib_BlrDnOffReq 5000;
BA_ "Version" SG_ 853 L_ATCU_Lib_BlrDnOffReq "23.11.10";
BA_ "Description" SG_ 853 L_ATCU_Lib_IntakeRECSw "This value only use for ATCU Library data monitoring (Only use before SOP)";
BA_ "GenSigSendType" SG_ 853 L_ATCU_Lib_IntakeRECSw 4;
BA_ "UserSigValidity" SG_ 853 L_ATCU_Lib_IntakeRECSw 0;
BA_REL_ "GenSigTimeoutTime" BU_SG_REL_ L_ATCU_vMON SG_ 853 L_ATCU_Lib_IntakeRECSw 5000;
BA_ "Version" SG_ 853 L_ATCU_Lib_IntakeRECSw "23.11.10";
BA_ "Description" SG_ 853 L_ATCU_Lib_IntakeFRESw "This value only use for ATCU Library data monitoring (Only use before SOP)";
BA_ "GenSigSendType" SG_ 853 L_ATCU_Lib_IntakeFRESw 4;
BA_ "UserSigValidity" SG_ 853 L_ATCU_Lib_IntakeFRESw 0;
BA_REL_ "GenSigTimeoutTime" BU_SG_REL_ L_ATCU_vMON SG_ 853 L_ATCU_Lib_IntakeFRESw 5000;
BA_ "Version" SG_ 853 L_ATCU_Lib_IntakeFRESw "23.11.10";
BA_ "Description" SG_ 853 L_ATCU_Lib_ACSw "This value only use for ATCU Library data monitoring (Only use before SOP)";
BA_ "GenSigSendType" SG_ 853 L_ATCU_Lib_ACSw 4;
BA_ "UserSigValidity" SG_ 853 L_ATCU_Lib_ACSw 0;
BA_REL_ "GenSigTimeoutTime" BU_SG_REL_ L_ATCU_vMON SG_ 853 L_ATCU_Lib_ACSw 5000;
BA_ "Version" SG_ 853 L_ATCU_Lib_ACSw "23.11.10";
BA_ "Description" SG_ 853 L_ATCU_Lib_DEFSw "This value only use for ATCU Library data monitoring (Only use before SOP)";
BA_ "GenSigSendType" SG_ 853 L_ATCU_Lib_DEFSw 4;
BA_ "UserSigValidity" SG_ 853 L_ATCU_Lib_DEFSw 0;
BA_REL_ "GenSigTimeoutTime" BU_SG_REL_ L_ATCU_vMON SG_ 853 L_ATCU_Lib_DEFSw 5000;
BA_ "Version" SG_ 853 L_ATCU_Lib_DEFSw "23.11.10";
BA_ "Description" SG_ 853 L_ATCU_Lib_DrvTempUpSw "This value only use for ATCU Library data monitoring (Only use before SOP)";
BA_ "GenSigSendType" SG_ 853 L_ATCU_Lib_DrvTempUpSw 4;
BA_ "UserSigValidity" SG_ 853 L_ATCU_Lib_DrvTempUpSw 0;
BA_REL_ "GenSigTimeoutTime" BU_SG_REL_ L_ATCU_vMON SG_ 853 L_ATCU_Lib_DrvTempUpSw 5000;
BA_ "Version" SG_ 853 L_ATCU_Lib_DrvTempUpSw "23.11.10";
BA_ "Description" SG_ 853 L_ATCU_Lib_DrvTempDnSw "This value only use for ATCU Library data monitoring (Only use before SOP)";
BA_ "GenSigSendType" SG_ 853 L_ATCU_Lib_DrvTempDnSw 4;
BA_ "UserSigValidity" SG_ 853 L_ATCU_Lib_DrvTempDnSw 0;
BA_REL_ "GenSigTimeoutTime" BU_SG_REL_ L_ATCU_vMON SG_ 853 L_ATCU_Lib_DrvTempDnSw 5000;
BA_ "Version" SG_ 853 L_ATCU_Lib_DrvTempDnSw "23.11.10";
BA_ "Description" SG_ 853 L_ATCU_Lib_AstTempUpSw "This value only use for ATCU Library data monitoring (Only use before SOP)";
BA_ "GenSigSendType" SG_ 853 L_ATCU_Lib_AstTempUpSw 4;
BA_ "UserSigValidity" SG_ 853 L_ATCU_Lib_AstTempUpSw 0;
BA_REL_ "GenSigTimeoutTime" BU_SG_REL_ L_ATCU_vMON SG_ 853 L_ATCU_Lib_AstTempUpSw 5000;
BA_ "Version" SG_ 853 L_ATCU_Lib_AstTempUpSw "23.11.10";
BA_ "Description" SG_ 853 L_ATCU_Lib_AstTempDnSw "This value only use for ATCU Library data monitoring (Only use before SOP)";
BA_ "GenSigSendType" SG_ 853 L_ATCU_Lib_AstTempDnSw 4;
BA_ "UserSigValidity" SG_ 853 L_ATCU_Lib_AstTempDnSw 0;
BA_REL_ "GenSigTimeoutTime" BU_SG_REL_ L_ATCU_vMON SG_ 853 L_ATCU_Lib_AstTempDnSw 5000;
BA_ "Version" SG_ 853 L_ATCU_Lib_AstTempDnSw "23.11.10";
BA_ "Description" SG_ 853 L_ATCU_Lib_SyncSw "This value only use for ATCU Library data monitoring (Only use before SOP)";
BA_ "GenSigSendType" SG_ 853 L_ATCU_Lib_SyncSw 4;
BA_ "UserSigValidity" SG_ 853 L_ATCU_Lib_SyncSw 0;
BA_REL_ "GenSigTimeoutTime" BU_SG_REL_ L_ATCU_vMON SG_ 853 L_ATCU_Lib_SyncSw 5000;
BA_ "Version" SG_ 853 L_ATCU_Lib_SyncSw "23.11.10";
BA_ "Description" SG_ 853 L_ATCU_Lib_ModSw "This value only use for ATCU Library data monitoring (Only use before SOP)";
BA_ "GenSigSendType" SG_ 853 L_ATCU_Lib_ModSw 4;
BA_ "UserSigValidity" SG_ 853 L_ATCU_Lib_ModSw 0;
BA_REL_ "GenSigTimeoutTime" BU_SG_REL_ L_ATCU_vMON SG_ 853 L_ATCU_Lib_ModSw 5000;
BA_ "Version" SG_ 853 L_ATCU_Lib_ModSw "23.11.10";
BA_ "Description" SG_ 853 L_ATCU_Lib_DrvOnlySw "This value only use for ATCU Library data monitoring (Only use before SOP)";
BA_ "GenSigSendType" SG_ 853 L_ATCU_Lib_DrvOnlySw 4;
BA_ "UserSigValidity" SG_ 853 L_ATCU_Lib_DrvOnlySw 0;
BA_REL_ "GenSigTimeoutTime" BU_SG_REL_ L_ATCU_vMON SG_ 853 L_ATCU_Lib_DrvOnlySw 5000;
BA_ "Version" SG_ 853 L_ATCU_Lib_DrvOnlySw "23.11.10";
BA_ "Description" SG_ 853 L_ATCU_Lib_ClimateSw "This value only use for ATCU Library data monitoring (Only use before SOP)";
BA_ "GenSigSendType" SG_ 853 L_ATCU_Lib_ClimateSw 4;
BA_ "UserSigValidity" SG_ 853 L_ATCU_Lib_ClimateSw 0;
BA_REL_ "GenSigTimeoutTime" BU_SG_REL_ L_ATCU_vMON SG_ 853 L_ATCU_Lib_ClimateSw 5000;
BA_ "Version" SG_ 853 L_ATCU_Lib_ClimateSw "23.11.10";
BA_ "Description" SG_ 853 L_ATCU_Lib_RearDEFSw "This value only use for ATCU Library data monitoring (Only use before SOP)";
BA_ "GenSigSendType" SG_ 853 L_ATCU_Lib_RearDEFSw 4;
BA_ "UserSigValidity" SG_ 853 L_ATCU_Lib_RearDEFSw 0;
BA_REL_ "GenSigTimeoutTime" BU_SG_REL_ L_ATCU_vMON SG_ 853 L_ATCU_Lib_RearDEFSw 5000;
BA_ "Version" SG_ 853 L_ATCU_Lib_RearDEFSw "23.11.10";
BA_ "Description" SG_ 853 L_ATCU_Lib_StrWhlSw "This value only use for ATCU Library data monitoring (Only use before SOP)";
BA_ "GenSigSendType" SG_ 853 L_ATCU_Lib_StrWhlSw 4;
BA_ "UserSigValidity" SG_ 853 L_ATCU_Lib_StrWhlSw 0;
BA_REL_ "GenSigTimeoutTime" BU_SG_REL_ L_ATCU_vMON SG_ 853 L_ATCU_Lib_StrWhlSw 5000;
BA_ "Version" SG_ 853 L_ATCU_Lib_StrWhlSw "23.11.10";
BA_ "Description" SG_ 853 L_ATCU_Lib_DrvSeatHeatSw "This value only use for ATCU Library data monitoring (Only use before SOP)";
BA_ "GenSigSendType" SG_ 853 L_ATCU_Lib_DrvSeatHeatSw 4;
BA_ "UserSigValidity" SG_ 853 L_ATCU_Lib_DrvSeatHeatSw 0;
BA_REL_ "GenSigTimeoutTime" BU_SG_REL_ L_ATCU_vMON SG_ 853 L_ATCU_Lib_DrvSeatHeatSw 5000;
BA_ "Version" SG_ 853 L_ATCU_Lib_DrvSeatHeatSw "23.11.10";
BA_ "Description" SG_ 853 L_ATCU_Lib_DrvSeatVentSw "This value only use for ATCU Library data monitoring (Only use before SOP)";
BA_ "GenSigSendType" SG_ 853 L_ATCU_Lib_DrvSeatVentSw 4;
BA_ "UserSigValidity" SG_ 853 L_ATCU_Lib_DrvSeatVentSw 0;
BA_REL_ "GenSigTimeoutTime" BU_SG_REL_ L_ATCU_vMON SG_ 853 L_ATCU_Lib_DrvSeatVentSw 5000;
BA_ "Version" SG_ 853 L_ATCU_Lib_DrvSeatVentSw "23.11.10";
BA_ "Description" SG_ 853 L_ATCU_Lib_AstSeatHeatSw "This value only use for ATCU Library data monitoring (Only use before SOP)";
BA_ "GenSigSendType" SG_ 853 L_ATCU_Lib_AstSeatHeatSw 4;
BA_ "UserSigValidity" SG_ 853 L_ATCU_Lib_AstSeatHeatSw 0;
BA_REL_ "GenSigTimeoutTime" BU_SG_REL_ L_ATCU_vMON SG_ 853 L_ATCU_Lib_AstSeatHeatSw 5000;
BA_ "Version" SG_ 853 L_ATCU_Lib_AstSeatHeatSw "23.11.10";
BA_ "Description" SG_ 853 L_ATCU_Lib_AstSeatVentSw "This value only use for ATCU Library data monitoring (Only use before SOP)";
BA_ "GenSigSendType" SG_ 853 L_ATCU_Lib_AstSeatVentSw 4;
BA_ "UserSigValidity" SG_ 853 L_ATCU_Lib_AstSeatVentSw 0;
BA_REL_ "GenSigTimeoutTime" BU_SG_REL_ L_ATCU_vMON SG_ 853 L_ATCU_Lib_AstSeatVentSw 5000;
BA_ "Version" SG_ 853 L_ATCU_Lib_AstSeatVentSw "23.11.10";
BA_ "Description" SG_ 853 L_ATCU_Lib_DrvSeatTumblerSw "This value only use for ATCU Library data monitoring (Only use before SOP)";
BA_ "GenSigSendType" SG_ 853 L_ATCU_Lib_DrvSeatTumblerSw 4;
BA_ "UserSigValidity" SG_ 853 L_ATCU_Lib_DrvSeatTumblerSw 0;
BA_REL_ "GenSigTimeoutTime" BU_SG_REL_ L_ATCU_vMON SG_ 853 L_ATCU_Lib_DrvSeatTumblerSw 5000;
BA_ "Version" SG_ 853 L_ATCU_Lib_DrvSeatTumblerSw "23.11.10";
BA_ "Description" SG_ 853 L_ATCU_Lib_ModUpSw "This value only use for ATCU Library data monitoring (Only use before SOP)";
BA_ "GenSigSendType" SG_ 853 L_ATCU_Lib_ModUpSw 4;
BA_ "UserSigValidity" SG_ 853 L_ATCU_Lib_ModUpSw 0;
BA_REL_ "GenSigTimeoutTime" BU_SG_REL_ L_ATCU_vMON SG_ 853 L_ATCU_Lib_ModUpSw 5000;
BA_ "Version" SG_ 853 L_ATCU_Lib_ModUpSw "23.11.10";
BA_ "Description" SG_ 853 L_ATCU_Lib_AstSeatTumblerSw "This value only use for ATCU Library data monitoring (Only use before SOP)";
BA_ "GenSigSendType" SG_ 853 L_ATCU_Lib_AstSeatTumblerSw 4;
BA_ "UserSigValidity" SG_ 853 L_ATCU_Lib_AstSeatTumblerSw 0;
BA_REL_ "GenSigTimeoutTime" BU_SG_REL_ L_ATCU_vMON SG_ 853 L_ATCU_Lib_AstSeatTumblerSw 5000;
BA_ "Version" SG_ 853 L_ATCU_Lib_AstSeatTumblerSw "23.11.10";
BA_ "Description" SG_ 853 L_ATCU_Lib_ModDnSw "This value only use for ATCU Library data monitoring (Only use before SOP)";
BA_ "GenSigSendType" SG_ 853 L_ATCU_Lib_ModDnSw 4;
BA_ "UserSigValidity" SG_ 853 L_ATCU_Lib_ModDnSw 0;
BA_REL_ "GenSigTimeoutTime" BU_SG_REL_ L_ATCU_vMON SG_ 853 L_ATCU_Lib_ModDnSw 5000;
BA_ "Version" SG_ 853 L_ATCU_Lib_ModDnSw "23.11.10";
BA_ "Description" SG_ 853 L_ATCU_Lib_BlrUpSw "This value only use for ATCU Library data monitoring (Only use before SOP)";
BA_ "GenSigSendType" SG_ 853 L_ATCU_Lib_BlrUpSw 4;
BA_ "UserSigValidity" SG_ 853 L_ATCU_Lib_BlrUpSw 0;
BA_REL_ "GenSigTimeoutTime" BU_SG_REL_ L_ATCU_vMON SG_ 853 L_ATCU_Lib_BlrUpSw 5000;
BA_ "Version" SG_ 853 L_ATCU_Lib_BlrUpSw "23.11.10";
BA_ "Description" SG_ 853 L_ATCU_Lib_BlrDnSw "This value only use for ATCU Library data monitoring (Only use before SOP)";
BA_ "GenSigSendType" SG_ 853 L_ATCU_Lib_BlrDnSw 4;
BA_ "UserSigValidity" SG_ 853 L_ATCU_Lib_BlrDnSw 0;
BA_REL_ "GenSigTimeoutTime" BU_SG_REL_ L_ATCU_vMON SG_ 853 L_ATCU_Lib_BlrDnSw 5000;
BA_ "Version" SG_ 853 L_ATCU_Lib_BlrDnSw "23.11.10";
BA_ "GenMsgSendType" BO_ 854 0;
BA_ "GenMsgCycleTime" BO_ 854 500;
BA_ "Description" SG_ 854 L_ATCU_Lib_OffSetSw "This value only use for ATCU Library data monitoring (Only use before SOP)";
BA_ "GenSigSendType" SG_ 854 L_ATCU_Lib_OffSetSw 4;
BA_ "UserSigValidity" SG_ 854 L_ATCU_Lib_OffSetSw 0;
BA_REL_ "GenSigTimeoutTime" BU_SG_REL_ L_ATCU_vMON SG_ 854 L_ATCU_Lib_OffSetSw 5000;
BA_ "Version" SG_ 854 L_ATCU_Lib_OffSetSw "23.11.10";
BA_ "Description" SG_ 854 L_ATCU_Lib_BlrSetSw "This value only use for ATCU Library data monitoring (Only use before SOP)";
BA_ "GenSigSendType" SG_ 854 L_ATCU_Lib_BlrSetSw 4;
BA_ "UserSigValidity" SG_ 854 L_ATCU_Lib_BlrSetSw 0;
BA_REL_ "GenSigTimeoutTime" BU_SG_REL_ L_ATCU_vMON SG_ 854 L_ATCU_Lib_BlrSetSw 5000;
BA_ "Version" SG_ 854 L_ATCU_Lib_BlrSetSw "23.11.10";
BA_ "Description" SG_ 854 L_ATCU_Lib_AutoSetSw "This value only use for ATCU Library data monitoring (Only use before SOP)";
BA_ "GenSigSendType" SG_ 854 L_ATCU_Lib_AutoSetSw 4;
BA_ "UserSigValidity" SG_ 854 L_ATCU_Lib_AutoSetSw 0;
BA_REL_ "GenSigTimeoutTime" BU_SG_REL_ L_ATCU_vMON SG_ 854 L_ATCU_Lib_AutoSetSw 5000;
BA_ "Version" SG_ 854 L_ATCU_Lib_AutoSetSw "23.11.10";
BA_ "Description" SG_ 854 L_ATCU_Lib_DEFSetSw "This value only use for ATCU Library data monitoring (Only use before SOP)";
BA_ "GenSigSendType" SG_ 854 L_ATCU_Lib_DEFSetSw 4;
BA_ "UserSigValidity" SG_ 854 L_ATCU_Lib_DEFSetSw 0;
BA_REL_ "GenSigTimeoutTime" BU_SG_REL_ L_ATCU_vMON SG_ 854 L_ATCU_Lib_DEFSetSw 5000;
BA_ "Version" SG_ 854 L_ATCU_Lib_DEFSetSw "23.11.10";
BA_ "Description" SG_ 854 L_ATCU_Lib_SyncSetSw "This value only use for ATCU Library data monitoring (Only use before SOP)";
BA_ "GenSigSendType" SG_ 854 L_ATCU_Lib_SyncSetSw 4;
BA_ "UserSigValidity" SG_ 854 L_ATCU_Lib_SyncSetSw 0;
BA_REL_ "GenSigTimeoutTime" BU_SG_REL_ L_ATCU_vMON SG_ 854 L_ATCU_Lib_SyncSetSw 5000;
BA_ "Version" SG_ 854 L_ATCU_Lib_SyncSetSw "23.11.10";
BA_ "Description" SG_ 854 L_ATCU_Lib_IntakeSetSw "This value only use for ATCU Library data monitoring (Only use before SOP)";
BA_ "GenSigSendType" SG_ 854 L_ATCU_Lib_IntakeSetSw 4;
BA_ "UserSigValidity" SG_ 854 L_ATCU_Lib_IntakeSetSw 0;
BA_REL_ "GenSigTimeoutTime" BU_SG_REL_ L_ATCU_vMON SG_ 854 L_ATCU_Lib_IntakeSetSw 5000;
BA_ "Version" SG_ 854 L_ATCU_Lib_IntakeSetSw "23.11.10";
BA_ "Description" SG_ 854 L_ATCU_Lib_DrvTempSetSw "This value only use for ATCU Library data monitoring (Only use before SOP)";
BA_ "GenSigSendType" SG_ 854 L_ATCU_Lib_DrvTempSetSw 4;
BA_ "UserSigValidity" SG_ 854 L_ATCU_Lib_DrvTempSetSw 0;
BA_REL_ "GenSigTimeoutTime" BU_SG_REL_ L_ATCU_vMON SG_ 854 L_ATCU_Lib_DrvTempSetSw 5000;
BA_ "Version" SG_ 854 L_ATCU_Lib_DrvTempSetSw "23.11.10";
BA_ "Description" SG_ 854 L_ATCU_Lib_MultiAutoSetSw "This value only use for ATCU Library data monitoring (Only use before SOP)";
BA_ "GenSigSendType" SG_ 854 L_ATCU_Lib_MultiAutoSetSw 4;
BA_ "UserSigValidity" SG_ 854 L_ATCU_Lib_MultiAutoSetSw 0;
BA_REL_ "GenSigTimeoutTime" BU_SG_REL_ L_ATCU_vMON SG_ 854 L_ATCU_Lib_MultiAutoSetSw 5000;
BA_ "Version" SG_ 854 L_ATCU_Lib_MultiAutoSetSw "23.11.10";
BA_ "Description" SG_ 854 L_ATCU_Lib_AstTempSetSw "This value only use for ATCU Library data monitoring (Only use before SOP)";
BA_ "GenSigSendType" SG_ 854 L_ATCU_Lib_AstTempSetSw 4;
BA_ "UserSigValidity" SG_ 854 L_ATCU_Lib_AstTempSetSw 0;
BA_REL_ "GenSigTimeoutTime" BU_SG_REL_ L_ATCU_vMON SG_ 854 L_ATCU_Lib_AstTempSetSw 5000;
BA_ "Version" SG_ 854 L_ATCU_Lib_AstTempSetSw "23.11.10";
BA_ "Description" SG_ 854 L_ATCU_Lib_DrvOnlySetSw "This value only use for ATCU Library data monitoring (Only use before SOP)";
BA_ "GenSigSendType" SG_ 854 L_ATCU_Lib_DrvOnlySetSw 4;
BA_ "UserSigValidity" SG_ 854 L_ATCU_Lib_DrvOnlySetSw 0;
BA_REL_ "GenSigTimeoutTime" BU_SG_REL_ L_ATCU_vMON SG_ 854 L_ATCU_Lib_DrvOnlySetSw 5000;
BA_ "Version" SG_ 854 L_ATCU_Lib_DrvOnlySetSw "23.11.10";
BA_ "Description" SG_ 854 L_ATCU_Lib_DrvTempClickCnt "This value only use for ATCU Library data monitoring (Only use before SOP)";
BA_ "GenSigSendType" SG_ 854 L_ATCU_Lib_DrvTempClickCnt 4;
BA_ "GenSigStartValue" SG_ 854 L_ATCU_Lib_DrvTempClickCnt 255;
BA_ "UserSigValidity" SG_ 854 L_ATCU_Lib_DrvTempClickCnt 0;
BA_REL_ "GenSigTimeoutTime" BU_SG_REL_ L_ATCU_vMON SG_ 854 L_ATCU_Lib_DrvTempClickCnt 5000;
BA_ "Version" SG_ 854 L_ATCU_Lib_DrvTempClickCnt "24.05.08";
BA_ "Description" SG_ 854 L_ATCU_Lib_AstTempClickCnt "This value only use for ATCU Library data monitoring (Only use before SOP)";
BA_ "GenSigSendType" SG_ 854 L_ATCU_Lib_AstTempClickCnt 4;
BA_ "GenSigStartValue" SG_ 854 L_ATCU_Lib_AstTempClickCnt 255;
BA_ "UserSigValidity" SG_ 854 L_ATCU_Lib_AstTempClickCnt 0;
BA_REL_ "GenSigTimeoutTime" BU_SG_REL_ L_ATCU_vMON SG_ 854 L_ATCU_Lib_AstTempClickCnt 5000;
BA_ "Version" SG_ 854 L_ATCU_Lib_AstTempClickCnt "24.05.08";
BA_ "Description" SG_ 854 L_ATCU_Lib_ACSetSw "This value only use for ATCU Library data monitoring (Only use before SOP)";
BA_ "GenSigSendType" SG_ 854 L_ATCU_Lib_ACSetSw 4;
BA_ "UserSigValidity" SG_ 854 L_ATCU_Lib_ACSetSw 0;
BA_REL_ "GenSigTimeoutTime" BU_SG_REL_ L_ATCU_vMON SG_ 854 L_ATCU_Lib_ACSetSw 5000;
BA_ "Version" SG_ 854 L_ATCU_Lib_ACSetSw "23.11.10";
BA_ "Description" SG_ 854 L_ATCU_Lib_ModSetSw "This value only use for ATCU Library data monitoring (Only use before SOP)";
BA_ "GenSigSendType" SG_ 854 L_ATCU_Lib_ModSetSw 4;
BA_ "UserSigValidity" SG_ 854 L_ATCU_Lib_ModSetSw 0;
BA_REL_ "GenSigTimeoutTime" BU_SG_REL_ L_ATCU_vMON SG_ 854 L_ATCU_Lib_ModSetSw 5000;
BA_ "Version" SG_ 854 L_ATCU_Lib_ModSetSw "23.11.10";
BA_ "GenMsgSendType" BO_ 855 0;
BA_ "GenMsgCycleTime" BO_ 855 500;
BA_ "Description" SG_ 855 L_ATCU_Lib_2ndAutoSw "This value only use for ATCU Library data monitoring (Only use before SOP)";
BA_ "GenSigSendType" SG_ 855 L_ATCU_Lib_2ndAutoSw 4;
BA_ "UserSigValidity" SG_ 855 L_ATCU_Lib_2ndAutoSw 0;
BA_REL_ "GenSigTimeoutTime" BU_SG_REL_ L_ATCU_vMON SG_ 855 L_ATCU_Lib_2ndAutoSw 5000;
BA_ "Version" SG_ 855 L_ATCU_Lib_2ndAutoSw "23.11.10";
BA_ "Description" SG_ 855 L_ATCU_Lib_2ndAutoUpSw "This value only use for ATCU Library data monitoring (Only use before SOP)";
BA_ "GenSigSendType" SG_ 855 L_ATCU_Lib_2ndAutoUpSw 4;
BA_ "UserSigValidity" SG_ 855 L_ATCU_Lib_2ndAutoUpSw 0;
BA_REL_ "GenSigTimeoutTime" BU_SG_REL_ L_ATCU_vMON SG_ 855 L_ATCU_Lib_2ndAutoUpSw 5000;
BA_ "Version" SG_ 855 L_ATCU_Lib_2ndAutoUpSw "23.11.10";
BA_ "Description" SG_ 855 L_ATCU_Lib_2LHTempUpSw "This value only use for ATCU Library data monitoring (Only use before SOP)";
BA_ "GenSigSendType" SG_ 855 L_ATCU_Lib_2LHTempUpSw 4;
BA_ "UserSigValidity" SG_ 855 L_ATCU_Lib_2LHTempUpSw 0;
BA_REL_ "GenSigTimeoutTime" BU_SG_REL_ L_ATCU_vMON SG_ 855 L_ATCU_Lib_2LHTempUpSw 5000;
BA_ "Version" SG_ 855 L_ATCU_Lib_2LHTempUpSw "23.11.10";
BA_ "Description" SG_ 855 L_ATCU_Lib_2LHTempDnSw "This value only use for ATCU Library data monitoring (Only use before SOP)";
BA_ "GenSigSendType" SG_ 855 L_ATCU_Lib_2LHTempDnSw 4;
BA_ "UserSigValidity" SG_ 855 L_ATCU_Lib_2LHTempDnSw 0;
BA_REL_ "GenSigTimeoutTime" BU_SG_REL_ L_ATCU_vMON SG_ 855 L_ATCU_Lib_2LHTempDnSw 5000;
BA_ "Version" SG_ 855 L_ATCU_Lib_2LHTempDnSw "23.11.10";
BA_ "Description" SG_ 855 L_ATCU_Lib_2RHTempUpSw "This value only use for ATCU Library data monitoring (Only use before SOP)";
BA_ "GenSigSendType" SG_ 855 L_ATCU_Lib_2RHTempUpSw 4;
BA_ "UserSigValidity" SG_ 855 L_ATCU_Lib_2RHTempUpSw 0;
BA_REL_ "GenSigTimeoutTime" BU_SG_REL_ L_ATCU_vMON SG_ 855 L_ATCU_Lib_2RHTempUpSw 5000;
BA_ "Version" SG_ 855 L_ATCU_Lib_2RHTempUpSw "23.11.10";
BA_ "Description" SG_ 855 L_ATCU_Lib_2RHTempDnSw "This value only use for ATCU Library data monitoring (Only use before SOP)";
BA_ "GenSigSendType" SG_ 855 L_ATCU_Lib_2RHTempDnSw 4;
BA_ "UserSigValidity" SG_ 855 L_ATCU_Lib_2RHTempDnSw 0;
BA_REL_ "GenSigTimeoutTime" BU_SG_REL_ L_ATCU_vMON SG_ 855 L_ATCU_Lib_2RHTempDnSw 5000;
BA_ "Version" SG_ 855 L_ATCU_Lib_2RHTempDnSw "23.11.10";
BA_ "Description" SG_ 855 L_ATCU_Lib_2ndSyncSw "This value only use for ATCU Library data monitoring (Only use before SOP)";
BA_ "GenSigSendType" SG_ 855 L_ATCU_Lib_2ndSyncSw 4;
BA_ "UserSigValidity" SG_ 855 L_ATCU_Lib_2ndSyncSw 0;
BA_REL_ "GenSigTimeoutTime" BU_SG_REL_ L_ATCU_vMON SG_ 855 L_ATCU_Lib_2ndSyncSw 5000;
BA_ "Version" SG_ 855 L_ATCU_Lib_2ndSyncSw "23.11.10";
BA_ "Description" SG_ 855 L_ATCU_Lib_2ndLockSw "This value only use for ATCU Library data monitoring (Only use before SOP)";
BA_ "GenSigSendType" SG_ 855 L_ATCU_Lib_2ndLockSw 4;
BA_ "UserSigValidity" SG_ 855 L_ATCU_Lib_2ndLockSw 0;
BA_REL_ "GenSigTimeoutTime" BU_SG_REL_ L_ATCU_vMON SG_ 855 L_ATCU_Lib_2ndLockSw 5000;
BA_ "Version" SG_ 855 L_ATCU_Lib_2ndLockSw "23.11.10";
BA_ "Description" SG_ 855 L_ATCU_Lib_2LHSeatHeatSw "This value only use for ATCU Library data monitoring (Only use before SOP)";
BA_ "GenSigSendType" SG_ 855 L_ATCU_Lib_2LHSeatHeatSw 4;
BA_ "UserSigValidity" SG_ 855 L_ATCU_Lib_2LHSeatHeatSw 0;
BA_REL_ "GenSigTimeoutTime" BU_SG_REL_ L_ATCU_vMON SG_ 855 L_ATCU_Lib_2LHSeatHeatSw 5000;
BA_ "Version" SG_ 855 L_ATCU_Lib_2LHSeatHeatSw "23.11.10";
BA_ "Description" SG_ 855 L_ATCU_Lib_2LHSeatVentSw "This value only use for ATCU Library data monitoring (Only use before SOP)";
BA_ "GenSigSendType" SG_ 855 L_ATCU_Lib_2LHSeatVentSw 4;
BA_ "UserSigValidity" SG_ 855 L_ATCU_Lib_2LHSeatVentSw 0;
BA_REL_ "GenSigTimeoutTime" BU_SG_REL_ L_ATCU_vMON SG_ 855 L_ATCU_Lib_2LHSeatVentSw 5000;
BA_ "Version" SG_ 855 L_ATCU_Lib_2LHSeatVentSw "23.11.10";
BA_ "Description" SG_ 855 L_ATCU_Lib_2RHSeatHeatSw "This value only use for ATCU Library data monitoring (Only use before SOP)";
BA_ "GenSigSendType" SG_ 855 L_ATCU_Lib_2RHSeatHeatSw 4;
BA_ "UserSigValidity" SG_ 855 L_ATCU_Lib_2RHSeatHeatSw 0;
BA_REL_ "GenSigTimeoutTime" BU_SG_REL_ L_ATCU_vMON SG_ 855 L_ATCU_Lib_2RHSeatHeatSw 5000;
BA_ "Version" SG_ 855 L_ATCU_Lib_2RHSeatHeatSw "23.11.10";
BA_ "Description" SG_ 855 L_ATCU_Lib_2RHSeatVentSw "This value only use for ATCU Library data monitoring (Only use before SOP)";
BA_ "GenSigSendType" SG_ 855 L_ATCU_Lib_2RHSeatVentSw 4;
BA_ "UserSigValidity" SG_ 855 L_ATCU_Lib_2RHSeatVentSw 0;
BA_REL_ "GenSigTimeoutTime" BU_SG_REL_ L_ATCU_vMON SG_ 855 L_ATCU_Lib_2RHSeatVentSw 5000;
BA_ "Version" SG_ 855 L_ATCU_Lib_2RHSeatVentSw "23.11.10";
BA_ "Description" SG_ 855 L_ATCU_Lib_2ndAutoDnSw "This value only use for ATCU Library data monitoring (Only use before SOP)";
BA_ "GenSigSendType" SG_ 855 L_ATCU_Lib_2ndAutoDnSw 4;
BA_ "UserSigValidity" SG_ 855 L_ATCU_Lib_2ndAutoDnSw 0;
BA_REL_ "GenSigTimeoutTime" BU_SG_REL_ L_ATCU_vMON SG_ 855 L_ATCU_Lib_2ndAutoDnSw 5000;
BA_ "Version" SG_ 855 L_ATCU_Lib_2ndAutoDnSw "23.11.10";
BA_ "Description" SG_ 855 L_ATCU_Lib_2LHSeatTumblerSw "This value only use for ATCU Library data monitoring (Only use before SOP)";
BA_ "GenSigSendType" SG_ 855 L_ATCU_Lib_2LHSeatTumblerSw 4;
BA_ "UserSigValidity" SG_ 855 L_ATCU_Lib_2LHSeatTumblerSw 0;
BA_REL_ "GenSigTimeoutTime" BU_SG_REL_ L_ATCU_vMON SG_ 855 L_ATCU_Lib_2LHSeatTumblerSw 5000;
BA_ "Version" SG_ 855 L_ATCU_Lib_2LHSeatTumblerSw "23.11.10";
BA_ "Description" SG_ 855 L_ATCU_Lib_2RHSeatTumblerSw "This value only use for ATCU Library data monitoring (Only use before SOP)";
BA_ "GenSigSendType" SG_ 855 L_ATCU_Lib_2RHSeatTumblerSw 4;
BA_ "UserSigValidity" SG_ 855 L_ATCU_Lib_2RHSeatTumblerSw 0;
BA_REL_ "GenSigTimeoutTime" BU_SG_REL_ L_ATCU_vMON SG_ 855 L_ATCU_Lib_2RHSeatTumblerSw 5000;
BA_ "Version" SG_ 855 L_ATCU_Lib_2RHSeatTumblerSw "23.11.10";
BA_ "Description" SG_ 855 L_ATCU_Lib_2ndOffSetSw "This value only use for ATCU Library data monitoring (Only use before SOP)";
BA_ "GenSigSendType" SG_ 855 L_ATCU_Lib_2ndOffSetSw 4;
BA_ "UserSigValidity" SG_ 855 L_ATCU_Lib_2ndOffSetSw 0;
BA_REL_ "GenSigTimeoutTime" BU_SG_REL_ L_ATCU_vMON SG_ 855 L_ATCU_Lib_2ndOffSetSw 5000;
BA_ "Version" SG_ 855 L_ATCU_Lib_2ndOffSetSw "23.11.10";
BA_ "Description" SG_ 855 L_ATCU_Lib_2ndAutoSetSw "This value only use for ATCU Library data monitoring (Only use before SOP)";
BA_ "GenSigSendType" SG_ 855 L_ATCU_Lib_2ndAutoSetSw 4;
BA_ "UserSigValidity" SG_ 855 L_ATCU_Lib_2ndAutoSetSw 0;
BA_REL_ "GenSigTimeoutTime" BU_SG_REL_ L_ATCU_vMON SG_ 855 L_ATCU_Lib_2ndAutoSetSw 5000;
BA_ "Version" SG_ 855 L_ATCU_Lib_2ndAutoSetSw "23.11.10";
BA_ "Description" SG_ 855 L_ATCU_Lib_2ndMultiAutoSetSw "This value only use for ATCU Library data monitoring (Only use before SOP)";
BA_ "GenSigSendType" SG_ 855 L_ATCU_Lib_2ndMultiAutoSetSw 4;
BA_ "UserSigValidity" SG_ 855 L_ATCU_Lib_2ndMultiAutoSetSw 0;
BA_REL_ "GenSigTimeoutTime" BU_SG_REL_ L_ATCU_vMON SG_ 855 L_ATCU_Lib_2ndMultiAutoSetSw 5000;
BA_ "Version" SG_ 855 L_ATCU_Lib_2ndMultiAutoSetSw "23.11.10";
BA_ "Description" SG_ 855 L_ATCU_Lib_2LHModSw "This value only use for ATCU Library data monitoring (Only use before SOP)";
BA_ "GenSigSendType" SG_ 855 L_ATCU_Lib_2LHModSw 4;
BA_ "UserSigValidity" SG_ 855 L_ATCU_Lib_2LHModSw 0;
BA_REL_ "GenSigTimeoutTime" BU_SG_REL_ L_ATCU_vMON SG_ 855 L_ATCU_Lib_2LHModSw 5000;
BA_ "Version" SG_ 855 L_ATCU_Lib_2LHModSw "23.11.10";
BA_ "Description" SG_ 855 L_ATCU_Lib_2ndACSetSw "This value only use for ATCU Library data monitoring (Only use before SOP)";
BA_ "GenSigSendType" SG_ 855 L_ATCU_Lib_2ndACSetSw 4;
BA_ "UserSigValidity" SG_ 855 L_ATCU_Lib_2ndACSetSw 0;
BA_REL_ "GenSigTimeoutTime" BU_SG_REL_ L_ATCU_vMON SG_ 855 L_ATCU_Lib_2ndACSetSw 5000;
BA_ "Version" SG_ 855 L_ATCU_Lib_2ndACSetSw "23.11.10";
BA_ "Description" SG_ 855 L_ATCU_Lib_2LHModSetSw "This value only use for ATCU Library data monitoring (Only use before SOP)";
BA_ "GenSigSendType" SG_ 855 L_ATCU_Lib_2LHModSetSw 4;
BA_ "UserSigValidity" SG_ 855 L_ATCU_Lib_2LHModSetSw 0;
BA_REL_ "GenSigTimeoutTime" BU_SG_REL_ L_ATCU_vMON SG_ 855 L_ATCU_Lib_2LHModSetSw 5000;
BA_ "Version" SG_ 855 L_ATCU_Lib_2LHModSetSw "23.11.10";
BA_ "Description" SG_ 855 L_ATCU_Lib_2LHBlrSetSw "This value only use for ATCU Library data monitoring (Only use before SOP)";
BA_ "GenSigSendType" SG_ 855 L_ATCU_Lib_2LHBlrSetSw 4;
BA_ "UserSigValidity" SG_ 855 L_ATCU_Lib_2LHBlrSetSw 0;
BA_REL_ "GenSigTimeoutTime" BU_SG_REL_ L_ATCU_vMON SG_ 855 L_ATCU_Lib_2LHBlrSetSw 5000;
BA_ "Version" SG_ 855 L_ATCU_Lib_2LHBlrSetSw "23.11.10";
BA_ "Description" SG_ 855 L_ATCU_Lib_2LHModUpSw "This value only use for ATCU Library data monitoring (Only use before SOP)";
BA_ "GenSigSendType" SG_ 855 L_ATCU_Lib_2LHModUpSw 4;
BA_ "UserSigValidity" SG_ 855 L_ATCU_Lib_2LHModUpSw 0;
BA_REL_ "GenSigTimeoutTime" BU_SG_REL_ L_ATCU_vMON SG_ 855 L_ATCU_Lib_2LHModUpSw 5000;
BA_ "Version" SG_ 855 L_ATCU_Lib_2LHModUpSw "23.11.10";
BA_ "Description" SG_ 855 L_ATCU_Lib_2LHTempSetSw "This value only use for ATCU Library data monitoring (Only use before SOP)";
BA_ "GenSigSendType" SG_ 855 L_ATCU_Lib_2LHTempSetSw 4;
BA_ "UserSigValidity" SG_ 855 L_ATCU_Lib_2LHTempSetSw 0;
BA_REL_ "GenSigTimeoutTime" BU_SG_REL_ L_ATCU_vMON SG_ 855 L_ATCU_Lib_2LHTempSetSw 5000;
BA_ "Version" SG_ 855 L_ATCU_Lib_2LHTempSetSw "23.11.10";
BA_ "Description" SG_ 855 L_ATCU_Lib_2ndSyncSetSw "This value only use for ATCU Library data monitoring (Only use before SOP)";
BA_ "GenSigSendType" SG_ 855 L_ATCU_Lib_2ndSyncSetSw 4;
BA_ "UserSigValidity" SG_ 855 L_ATCU_Lib_2ndSyncSetSw 0;
BA_REL_ "GenSigTimeoutTime" BU_SG_REL_ L_ATCU_vMON SG_ 855 L_ATCU_Lib_2ndSyncSetSw 5000;
BA_ "Version" SG_ 855 L_ATCU_Lib_2ndSyncSetSw "23.11.10";
BA_ "Description" SG_ 855 L_ATCU_Lib_2ndOffSw "This value only use for ATCU Library data monitoring (Only use before SOP)";
BA_ "GenSigSendType" SG_ 855 L_ATCU_Lib_2ndOffSw 4;
BA_ "UserSigValidity" SG_ 855 L_ATCU_Lib_2ndOffSw 0;
BA_REL_ "GenSigTimeoutTime" BU_SG_REL_ L_ATCU_vMON SG_ 855 L_ATCU_Lib_2ndOffSw 5000;
BA_ "Version" SG_ 855 L_ATCU_Lib_2ndOffSw "23.11.10";
BA_ "Description" SG_ 855 L_ATCU_Lib_2RHTempSetSw "This value only use for ATCU Library data monitoring (Only use before SOP)";
BA_ "GenSigSendType" SG_ 855 L_ATCU_Lib_2RHTempSetSw 4;
BA_ "UserSigValidity" SG_ 855 L_ATCU_Lib_2RHTempSetSw 0;
BA_REL_ "GenSigTimeoutTime" BU_SG_REL_ L_ATCU_vMON SG_ 855 L_ATCU_Lib_2RHTempSetSw 5000;
BA_ "Version" SG_ 855 L_ATCU_Lib_2RHTempSetSw "23.11.10";
BA_ "Description" SG_ 855 L_ATCU_Lib_2LHModDnSw "This value only use for ATCU Library data monitoring (Only use before SOP)";
BA_ "GenSigSendType" SG_ 855 L_ATCU_Lib_2LHModDnSw 4;
BA_ "UserSigValidity" SG_ 855 L_ATCU_Lib_2LHModDnSw 0;
BA_REL_ "GenSigTimeoutTime" BU_SG_REL_ L_ATCU_vMON SG_ 855 L_ATCU_Lib_2LHModDnSw 5000;
BA_ "Version" SG_ 855 L_ATCU_Lib_2LHModDnSw "23.11.10";
BA_ "Description" SG_ 855 L_ATCU_Lib_2ndLockSetSw "This value only use for ATCU Library data monitoring (Only use before SOP)";
BA_ "GenSigSendType" SG_ 855 L_ATCU_Lib_2ndLockSetSw 4;
BA_ "UserSigValidity" SG_ 855 L_ATCU_Lib_2ndLockSetSw 0;
BA_REL_ "GenSigTimeoutTime" BU_SG_REL_ L_ATCU_vMON SG_ 855 L_ATCU_Lib_2ndLockSetSw 5000;
BA_ "Version" SG_ 855 L_ATCU_Lib_2ndLockSetSw "23.11.10";
BA_ "Description" SG_ 855 L_ATCU_Lib_DrvBlrClickCnt "This value only use for ATCU Library data monitoring (Only use before SOP)";
BA_ "GenSigSendType" SG_ 855 L_ATCU_Lib_DrvBlrClickCnt 4;
BA_ "GenSigStartValue" SG_ 855 L_ATCU_Lib_DrvBlrClickCnt 255;
BA_ "UserSigValidity" SG_ 855 L_ATCU_Lib_DrvBlrClickCnt 0;
BA_REL_ "GenSigTimeoutTime" BU_SG_REL_ L_ATCU_vMON SG_ 855 L_ATCU_Lib_DrvBlrClickCnt 5000;
BA_ "Version" SG_ 855 L_ATCU_Lib_DrvBlrClickCnt "24.05.08";
BA_ "Description" SG_ 855 L_ATCU_Lib_2LHBlrUpSw "This value only use for ATCU Library data monitoring (Only use before SOP)";
BA_ "GenSigSendType" SG_ 855 L_ATCU_Lib_2LHBlrUpSw 4;
BA_ "UserSigValidity" SG_ 855 L_ATCU_Lib_2LHBlrUpSw 0;
BA_REL_ "GenSigTimeoutTime" BU_SG_REL_ L_ATCU_vMON SG_ 855 L_ATCU_Lib_2LHBlrUpSw 5000;
BA_ "Version" SG_ 855 L_ATCU_Lib_2LHBlrUpSw "23.11.10";
BA_ "Description" SG_ 855 L_ATCU_Lib_2LHBlrDnSw "This value only use for ATCU Library data monitoring (Only use before SOP)";
BA_ "GenSigSendType" SG_ 855 L_ATCU_Lib_2LHBlrDnSw 4;
BA_ "UserSigValidity" SG_ 855 L_ATCU_Lib_2LHBlrDnSw 0;
BA_REL_ "GenSigTimeoutTime" BU_SG_REL_ L_ATCU_vMON SG_ 855 L_ATCU_Lib_2LHBlrDnSw 5000;
BA_ "Version" SG_ 855 L_ATCU_Lib_2LHBlrDnSw "23.11.10";
BA_ "Description" SG_ 855 L_ATCU_Lib_2LHBlrDnOffReq "This value only use for ATCU Library data monitoring (Only use before SOP)";
BA_ "GenSigSendType" SG_ 855 L_ATCU_Lib_2LHBlrDnOffReq 4;
BA_ "UserSigValidity" SG_ 855 L_ATCU_Lib_2LHBlrDnOffReq 0;
BA_REL_ "GenSigTimeoutTime" BU_SG_REL_ L_ATCU_vMON SG_ 855 L_ATCU_Lib_2LHBlrDnOffReq 5000;
BA_ "Version" SG_ 855 L_ATCU_Lib_2LHBlrDnOffReq "23.11.10";
BA_ "Description" SG_ 855 L_ATCU_Lib_2ndACSw "This value only use for ATCU Library data monitoring (Only use before SOP)";
BA_ "GenSigSendType" SG_ 855 L_ATCU_Lib_2ndACSw 4;
BA_ "UserSigValidity" SG_ 855 L_ATCU_Lib_2ndACSw 0;
BA_REL_ "GenSigTimeoutTime" BU_SG_REL_ L_ATCU_vMON SG_ 855 L_ATCU_Lib_2ndACSw 5000;
BA_ "Version" SG_ 855 L_ATCU_Lib_2ndACSw "23.11.10";
BA_ "GenMsgSendType" BO_ 865 0;
BA_ "GenMsgCycleTime" BO_ 865 500;
BA_ "Description" SG_ 865 L_ATCU_Lib_MngrIntakeBuf0 "This value only use for ATCU Library data monitoring (Only use before SOP)";
BA_ "GenSigSendType" SG_ 865 L_ATCU_Lib_MngrIntakeBuf0 4;
BA_ "UserSigValidity" SG_ 865 L_ATCU_Lib_MngrIntakeBuf0 0;
BA_REL_ "GenSigTimeoutTime" BU_SG_REL_ L_ATCU_vMON SG_ 865 L_ATCU_Lib_MngrIntakeBuf0 5000;
BA_ "Version" SG_ 865 L_ATCU_Lib_MngrIntakeBuf0 "25.05.03";
BA_ "Description" SG_ 865 L_ATCU_Lib_MngrIntakeBufLow1 "This value only use for ATCU Library data monitoring (Only use before SOP)";
BA_ "GenSigSendType" SG_ 865 L_ATCU_Lib_MngrIntakeBufLow1 4;
BA_ "UserSigValidity" SG_ 865 L_ATCU_Lib_MngrIntakeBufLow1 0;
BA_REL_ "GenSigTimeoutTime" BU_SG_REL_ L_ATCU_vMON SG_ 865 L_ATCU_Lib_MngrIntakeBufLow1 5000;
BA_ "Version" SG_ 865 L_ATCU_Lib_MngrIntakeBufLow1 "24.09.00";
BA_ "Description" SG_ 865 L_ATCU_Lib_MngrIntakeBuf2 "This value only use for ATCU Library data monitoring (Only use before SOP)";
BA_ "GenSigSendType" SG_ 865 L_ATCU_Lib_MngrIntakeBuf2 4;
BA_ "UserSigValidity" SG_ 865 L_ATCU_Lib_MngrIntakeBuf2 0;
BA_REL_ "GenSigTimeoutTime" BU_SG_REL_ L_ATCU_vMON SG_ 865 L_ATCU_Lib_MngrIntakeBuf2 5000;
BA_ "Version" SG_ 865 L_ATCU_Lib_MngrIntakeBuf2 "25.05.03";
BA_ "Description" SG_ 865 L_ATCU_Lib_MngrTempBuf0 "This value only use for ATCU Library data monitoring (Only use before SOP)";
BA_ "GenSigSendType" SG_ 865 L_ATCU_Lib_MngrTempBuf0 4;
BA_ "UserSigValidity" SG_ 865 L_ATCU_Lib_MngrTempBuf0 0;
BA_REL_ "GenSigTimeoutTime" BU_SG_REL_ L_ATCU_vMON SG_ 865 L_ATCU_Lib_MngrTempBuf0 5000;
BA_ "Version" SG_ 865 L_ATCU_Lib_MngrTempBuf0 "23.11.10";
BA_ "Description" SG_ 865 L_ATCU_Lib_MngrIntakeBuf3 "This value only use for ATCU Library data monitoring (Only use before SOP)";
BA_ "GenSigSendType" SG_ 865 L_ATCU_Lib_MngrIntakeBuf3 4;
BA_ "UserSigValidity" SG_ 865 L_ATCU_Lib_MngrIntakeBuf3 0;
BA_REL_ "GenSigTimeoutTime" BU_SG_REL_ L_ATCU_vMON SG_ 865 L_ATCU_Lib_MngrIntakeBuf3 5000;
BA_ "Version" SG_ 865 L_ATCU_Lib_MngrIntakeBuf3 "25.05.03";
BA_ "Description" SG_ 865 L_ATCU_Lib_MngrTempBuf1 "This value only use for ATCU Library data monitoring (Only use before SOP)";
BA_ "GenSigSendType" SG_ 865 L_ATCU_Lib_MngrTempBuf1 4;
BA_ "UserSigValidity" SG_ 865 L_ATCU_Lib_MngrTempBuf1 0;
BA_REL_ "GenSigTimeoutTime" BU_SG_REL_ L_ATCU_vMON SG_ 865 L_ATCU_Lib_MngrTempBuf1 5000;
BA_ "Version" SG_ 865 L_ATCU_Lib_MngrTempBuf1 "23.11.10";
BA_ "Description" SG_ 865 L_ATCU_Lib_MngrIntakeBuf4 "This value only use for ATCU Library data monitoring (Only use before SOP)";
BA_ "GenSigSendType" SG_ 865 L_ATCU_Lib_MngrIntakeBuf4 4;
BA_ "UserSigValidity" SG_ 865 L_ATCU_Lib_MngrIntakeBuf4 0;
BA_REL_ "GenSigTimeoutTime" BU_SG_REL_ L_ATCU_vMON SG_ 865 L_ATCU_Lib_MngrIntakeBuf4 5000;
BA_ "Version" SG_ 865 L_ATCU_Lib_MngrIntakeBuf4 "25.05.03";
BA_ "Description" SG_ 865 L_ATCU_Lib_MngrTempBuf2 "This value only use for ATCU Library data monitoring (Only use before SOP)";
BA_ "GenSigSendType" SG_ 865 L_ATCU_Lib_MngrTempBuf2 4;
BA_ "UserSigValidity" SG_ 865 L_ATCU_Lib_MngrTempBuf2 0;
BA_REL_ "GenSigTimeoutTime" BU_SG_REL_ L_ATCU_vMON SG_ 865 L_ATCU_Lib_MngrTempBuf2 5000;
BA_ "Version" SG_ 865 L_ATCU_Lib_MngrTempBuf2 "23.11.10";
BA_ "Description" SG_ 865 L_ATCU_Lib_MngrIntakeBuf5 "This value only use for ATCU Library data monitoring (Only use before SOP)";
BA_ "GenSigSendType" SG_ 865 L_ATCU_Lib_MngrIntakeBuf5 4;
BA_ "UserSigValidity" SG_ 865 L_ATCU_Lib_MngrIntakeBuf5 0;
BA_REL_ "GenSigTimeoutTime" BU_SG_REL_ L_ATCU_vMON SG_ 865 L_ATCU_Lib_MngrIntakeBuf5 5000;
BA_ "Version" SG_ 865 L_ATCU_Lib_MngrIntakeBuf5 "25.05.03";
BA_ "Description" SG_ 865 L_ATCU_Lib_MngrTempBuf3 "This value only use for ATCU Library data monitoring (Only use before SOP)";
BA_ "GenSigSendType" SG_ 865 L_ATCU_Lib_MngrTempBuf3 4;
BA_ "UserSigValidity" SG_ 865 L_ATCU_Lib_MngrTempBuf3 0;
BA_REL_ "GenSigTimeoutTime" BU_SG_REL_ L_ATCU_vMON SG_ 865 L_ATCU_Lib_MngrTempBuf3 5000;
BA_ "Version" SG_ 865 L_ATCU_Lib_MngrTempBuf3 "23.11.10";
BA_ "Description" SG_ 865 L_ATCU_Lib_MngrIntakeBuf6 "This value only use for ATCU Library data monitoring (Only use before SOP)";
BA_ "GenSigSendType" SG_ 865 L_ATCU_Lib_MngrIntakeBuf6 4;
BA_ "UserSigValidity" SG_ 865 L_ATCU_Lib_MngrIntakeBuf6 0;
BA_REL_ "GenSigTimeoutTime" BU_SG_REL_ L_ATCU_vMON SG_ 865 L_ATCU_Lib_MngrIntakeBuf6 5000;
BA_ "Version" SG_ 865 L_ATCU_Lib_MngrIntakeBuf6 "25.05.03";
BA_ "Description" SG_ 865 L_ATCU_Lib_MngrIntakeBufLow0 "This value only use for ATCU Library data monitoring (Only use before SOP)";
BA_ "GenSigSendType" SG_ 865 L_ATCU_Lib_MngrIntakeBufLow0 4;
BA_ "UserSigValidity" SG_ 865 L_ATCU_Lib_MngrIntakeBufLow0 0;
BA_REL_ "GenSigTimeoutTime" BU_SG_REL_ L_ATCU_vMON SG_ 865 L_ATCU_Lib_MngrIntakeBufLow0 5000;
BA_ "Version" SG_ 865 L_ATCU_Lib_MngrIntakeBufLow0 "24.09.00";
BA_ "Description" SG_ 865 L_ATCU_Lib_MngrTempBuf4 "This value only use for ATCU Library data monitoring (Only use before SOP)";
BA_ "GenSigSendType" SG_ 865 L_ATCU_Lib_MngrTempBuf4 4;
BA_ "UserSigValidity" SG_ 865 L_ATCU_Lib_MngrTempBuf4 0;
BA_REL_ "GenSigTimeoutTime" BU_SG_REL_ L_ATCU_vMON SG_ 865 L_ATCU_Lib_MngrTempBuf4 5000;
BA_ "Version" SG_ 865 L_ATCU_Lib_MngrTempBuf4 "23.11.10";
BA_ "Description" SG_ 865 L_ATCU_Lib_MngrIntakeBuf7 "This value only use for ATCU Library data monitoring (Only use before SOP)";
BA_ "GenSigSendType" SG_ 865 L_ATCU_Lib_MngrIntakeBuf7 4;
BA_ "UserSigValidity" SG_ 865 L_ATCU_Lib_MngrIntakeBuf7 0;
BA_REL_ "GenSigTimeoutTime" BU_SG_REL_ L_ATCU_vMON SG_ 865 L_ATCU_Lib_MngrIntakeBuf7 5000;
BA_ "Version" SG_ 865 L_ATCU_Lib_MngrIntakeBuf7 "25.05.03";
BA_ "Description" SG_ 865 L_ATCU_Lib_MngrTempBufLow2 "This value only use for ATCU Library data monitoring (Only use before SOP)";
BA_ "GenSigSendType" SG_ 865 L_ATCU_Lib_MngrTempBufLow2 4;
BA_ "UserSigValidity" SG_ 865 L_ATCU_Lib_MngrTempBufLow2 0;
BA_REL_ "GenSigTimeoutTime" BU_SG_REL_ L_ATCU_vMON SG_ 865 L_ATCU_Lib_MngrTempBufLow2 5000;
BA_ "Version" SG_ 865 L_ATCU_Lib_MngrTempBufLow2 "23.11.10";
BA_ "Description" SG_ 865 L_ATCU_Lib_MngrIntakeBuf1 "This value only use for ATCU Library data monitoring (Only use before SOP)";
BA_ "GenSigSendType" SG_ 865 L_ATCU_Lib_MngrIntakeBuf1 4;
BA_ "UserSigValidity" SG_ 865 L_ATCU_Lib_MngrIntakeBuf1 0;
BA_REL_ "GenSigTimeoutTime" BU_SG_REL_ L_ATCU_vMON SG_ 865 L_ATCU_Lib_MngrIntakeBuf1 5000;
BA_ "Version" SG_ 865 L_ATCU_Lib_MngrIntakeBuf1 "25.05.03";
BA_ "GenMsgSendType" BO_ 866 0;
BA_ "GenMsgCycleTime" BO_ 866 500;
BA_ "Description" SG_ 866 L_ATCU_Lib_2LHMngrModBuf0 "This value only use for ATCU Library data monitoring (Only use before SOP)";
BA_ "GenSigSendType" SG_ 866 L_ATCU_Lib_2LHMngrModBuf0 4;
BA_ "UserSigValidity" SG_ 866 L_ATCU_Lib_2LHMngrModBuf0 0;
BA_REL_ "GenSigTimeoutTime" BU_SG_REL_ L_ATCU_vMON SG_ 866 L_ATCU_Lib_2LHMngrModBuf0 5000;
BA_ "Version" SG_ 866 L_ATCU_Lib_2LHMngrModBuf0 "25.05.03";
BA_ "Description" SG_ 866 L_ATCU_Lib_2LHMngrModBuf3 "This value only use for ATCU Library data monitoring (Only use before SOP)";
BA_ "GenSigSendType" SG_ 866 L_ATCU_Lib_2LHMngrModBuf3 4;
BA_ "UserSigValidity" SG_ 866 L_ATCU_Lib_2LHMngrModBuf3 0;
BA_REL_ "GenSigTimeoutTime" BU_SG_REL_ L_ATCU_vMON SG_ 866 L_ATCU_Lib_2LHMngrModBuf3 5000;
BA_ "Version" SG_ 866 L_ATCU_Lib_2LHMngrModBuf3 "25.05.03";
BA_ "Description" SG_ 866 L_ATCU_Lib_2LHMngrModBuf4 "This value only use for ATCU Library data monitoring (Only use before SOP)";
BA_ "GenSigSendType" SG_ 866 L_ATCU_Lib_2LHMngrModBuf4 4;
BA_ "UserSigValidity" SG_ 866 L_ATCU_Lib_2LHMngrModBuf4 0;
BA_REL_ "GenSigTimeoutTime" BU_SG_REL_ L_ATCU_vMON SG_ 866 L_ATCU_Lib_2LHMngrModBuf4 5000;
BA_ "Version" SG_ 866 L_ATCU_Lib_2LHMngrModBuf4 "25.05.03";
BA_ "Description" SG_ 866 L_ATCU_Lib_2LHMngrModBuf5 "This value only use for ATCU Library data monitoring (Only use before SOP)";
BA_ "GenSigSendType" SG_ 866 L_ATCU_Lib_2LHMngrModBuf5 4;
BA_ "UserSigValidity" SG_ 866 L_ATCU_Lib_2LHMngrModBuf5 0;
BA_REL_ "GenSigTimeoutTime" BU_SG_REL_ L_ATCU_vMON SG_ 866 L_ATCU_Lib_2LHMngrModBuf5 5000;
BA_ "Version" SG_ 866 L_ATCU_Lib_2LHMngrModBuf5 "25.05.03";
BA_ "Description" SG_ 866 L_ATCU_Lib_2LHMngrModBuf6 "This value only use for ATCU Library data monitoring (Only use before SOP)";
BA_ "GenSigSendType" SG_ 866 L_ATCU_Lib_2LHMngrModBuf6 4;
BA_ "UserSigValidity" SG_ 866 L_ATCU_Lib_2LHMngrModBuf6 0;
BA_REL_ "GenSigTimeoutTime" BU_SG_REL_ L_ATCU_vMON SG_ 866 L_ATCU_Lib_2LHMngrModBuf6 5000;
BA_ "Version" SG_ 866 L_ATCU_Lib_2LHMngrModBuf6 "25.05.03";
BA_ "Description" SG_ 866 L_ATCU_Lib_2LHMngrModBuf7 "This value only use for ATCU Library data monitoring (Only use before SOP)";
BA_ "GenSigSendType" SG_ 866 L_ATCU_Lib_2LHMngrModBuf7 4;
BA_ "UserSigValidity" SG_ 866 L_ATCU_Lib_2LHMngrModBuf7 0;
BA_REL_ "GenSigTimeoutTime" BU_SG_REL_ L_ATCU_vMON SG_ 866 L_ATCU_Lib_2LHMngrModBuf7 5000;
BA_ "Version" SG_ 866 L_ATCU_Lib_2LHMngrModBuf7 "25.05.03";
BA_ "Description" SG_ 866 L_ATCU_Lib_2LHMngrBlwBuf0 "This value only use for ATCU Library data monitoring (Only use before SOP)";
BA_ "GenSigSendType" SG_ 866 L_ATCU_Lib_2LHMngrBlwBuf0 4;
BA_ "UserSigValidity" SG_ 866 L_ATCU_Lib_2LHMngrBlwBuf0 0;
BA_REL_ "GenSigTimeoutTime" BU_SG_REL_ L_ATCU_vMON SG_ 866 L_ATCU_Lib_2LHMngrBlwBuf0 5000;
BA_ "Version" SG_ 866 L_ATCU_Lib_2LHMngrBlwBuf0 "25.05.03";
BA_ "Description" SG_ 866 L_ATCU_Lib_2LHMngrBlwBuf1 "This value only use for ATCU Library data monitoring (Only use before SOP)";
BA_ "GenSigSendType" SG_ 866 L_ATCU_Lib_2LHMngrBlwBuf1 4;
BA_ "UserSigValidity" SG_ 866 L_ATCU_Lib_2LHMngrBlwBuf1 0;
BA_REL_ "GenSigTimeoutTime" BU_SG_REL_ L_ATCU_vMON SG_ 866 L_ATCU_Lib_2LHMngrBlwBuf1 5000;
BA_ "Version" SG_ 866 L_ATCU_Lib_2LHMngrBlwBuf1 "25.05.03";
BA_ "Description" SG_ 866 L_ATCU_Lib_2LHMngrModBuf1 "This value only use for ATCU Library data monitoring (Only use before SOP)";
BA_ "GenSigSendType" SG_ 866 L_ATCU_Lib_2LHMngrModBuf1 4;
BA_ "UserSigValidity" SG_ 866 L_ATCU_Lib_2LHMngrModBuf1 0;
BA_REL_ "GenSigTimeoutTime" BU_SG_REL_ L_ATCU_vMON SG_ 866 L_ATCU_Lib_2LHMngrModBuf1 5000;
BA_ "Version" SG_ 866 L_ATCU_Lib_2LHMngrModBuf1 "25.05.03";
BA_ "Description" SG_ 866 L_ATCU_Lib_2LHMngrBlwBuf2 "This value only use for ATCU Library data monitoring (Only use before SOP)";
BA_ "GenSigSendType" SG_ 866 L_ATCU_Lib_2LHMngrBlwBuf2 4;
BA_ "UserSigValidity" SG_ 866 L_ATCU_Lib_2LHMngrBlwBuf2 0;
BA_REL_ "GenSigTimeoutTime" BU_SG_REL_ L_ATCU_vMON SG_ 866 L_ATCU_Lib_2LHMngrBlwBuf2 5000;
BA_ "Version" SG_ 866 L_ATCU_Lib_2LHMngrBlwBuf2 "25.05.03";
BA_ "Description" SG_ 866 L_ATCU_Lib_2LHMngrBlwBuf3 "This value only use for ATCU Library data monitoring (Only use before SOP)";
BA_ "GenSigSendType" SG_ 866 L_ATCU_Lib_2LHMngrBlwBuf3 4;
BA_ "UserSigValidity" SG_ 866 L_ATCU_Lib_2LHMngrBlwBuf3 0;
BA_REL_ "GenSigTimeoutTime" BU_SG_REL_ L_ATCU_vMON SG_ 866 L_ATCU_Lib_2LHMngrBlwBuf3 5000;
BA_ "Version" SG_ 866 L_ATCU_Lib_2LHMngrBlwBuf3 "25.05.03";
BA_ "Description" SG_ 866 L_ATCU_Lib_2LHMngrBlwBuf4 "This value only use for ATCU Library data monitoring (Only use before SOP)";
BA_ "GenSigSendType" SG_ 866 L_ATCU_Lib_2LHMngrBlwBuf4 4;
BA_ "UserSigValidity" SG_ 866 L_ATCU_Lib_2LHMngrBlwBuf4 0;
BA_REL_ "GenSigTimeoutTime" BU_SG_REL_ L_ATCU_vMON SG_ 866 L_ATCU_Lib_2LHMngrBlwBuf4 5000;
BA_ "Version" SG_ 866 L_ATCU_Lib_2LHMngrBlwBuf4 "25.05.03";
BA_ "Description" SG_ 866 L_ATCU_Lib_2LHMngrBlwBuf5 "This value only use for ATCU Library data monitoring (Only use before SOP)";
BA_ "GenSigSendType" SG_ 866 L_ATCU_Lib_2LHMngrBlwBuf5 4;
BA_ "UserSigValidity" SG_ 866 L_ATCU_Lib_2LHMngrBlwBuf5 0;
BA_REL_ "GenSigTimeoutTime" BU_SG_REL_ L_ATCU_vMON SG_ 866 L_ATCU_Lib_2LHMngrBlwBuf5 5000;
BA_ "Version" SG_ 866 L_ATCU_Lib_2LHMngrBlwBuf5 "25.05.03";
BA_ "Description" SG_ 866 L_ATCU_Lib_2LHMngrBlwBuf6 "This value only use for ATCU Library data monitoring (Only use before SOP)";
BA_ "GenSigSendType" SG_ 866 L_ATCU_Lib_2LHMngrBlwBuf6 4;
BA_ "UserSigValidity" SG_ 866 L_ATCU_Lib_2LHMngrBlwBuf6 0;
BA_REL_ "GenSigTimeoutTime" BU_SG_REL_ L_ATCU_vMON SG_ 866 L_ATCU_Lib_2LHMngrBlwBuf6 5000;
BA_ "Version" SG_ 866 L_ATCU_Lib_2LHMngrBlwBuf6 "25.05.03";
BA_ "Description" SG_ 866 L_ATCU_Lib_2LHMngrBlwBufHi0 "This value only use for ATCU Library data monitoring (Only use before SOP)";
BA_ "GenSigSendType" SG_ 866 L_ATCU_Lib_2LHMngrBlwBufHi0 4;
BA_ "UserSigValidity" SG_ 866 L_ATCU_Lib_2LHMngrBlwBufHi0 0;
BA_REL_ "GenSigTimeoutTime" BU_SG_REL_ L_ATCU_vMON SG_ 866 L_ATCU_Lib_2LHMngrBlwBufHi0 5000;
BA_ "Version" SG_ 866 L_ATCU_Lib_2LHMngrBlwBufHi0 "23.11.10";
BA_ "Description" SG_ 866 L_ATCU_Lib_2LHMngrBlwBufHi1 "This value only use for ATCU Library data monitoring (Only use before SOP)";
BA_ "GenSigSendType" SG_ 866 L_ATCU_Lib_2LHMngrBlwBufHi1 4;
BA_ "UserSigValidity" SG_ 866 L_ATCU_Lib_2LHMngrBlwBufHi1 0;
BA_REL_ "GenSigTimeoutTime" BU_SG_REL_ L_ATCU_vMON SG_ 866 L_ATCU_Lib_2LHMngrBlwBufHi1 5000;
BA_ "Version" SG_ 866 L_ATCU_Lib_2LHMngrBlwBufHi1 "23.11.10";
BA_ "Description" SG_ 866 L_ATCU_Lib_2LHMngrModBuf2 "This value only use for ATCU Library data monitoring (Only use before SOP)";
BA_ "GenSigSendType" SG_ 866 L_ATCU_Lib_2LHMngrModBuf2 4;
BA_ "UserSigValidity" SG_ 866 L_ATCU_Lib_2LHMngrModBuf2 0;
BA_REL_ "GenSigTimeoutTime" BU_SG_REL_ L_ATCU_vMON SG_ 866 L_ATCU_Lib_2LHMngrModBuf2 5000;
BA_ "Version" SG_ 866 L_ATCU_Lib_2LHMngrModBuf2 "25.05.03";
BA_ "GenMsgSendType" BO_ 867 0;
BA_ "GenMsgCycleTime" BO_ 867 500;
BA_ "Description" SG_ 867 L_ATCU_Lib_2LHMngrTempBuf0 "This value only use for ATCU Library data monitoring (Only use before SOP)";
BA_ "GenSigSendType" SG_ 867 L_ATCU_Lib_2LHMngrTempBuf0 4;
BA_ "UserSigValidity" SG_ 867 L_ATCU_Lib_2LHMngrTempBuf0 0;
BA_REL_ "GenSigTimeoutTime" BU_SG_REL_ L_ATCU_vMON SG_ 867 L_ATCU_Lib_2LHMngrTempBuf0 5000;
BA_ "Version" SG_ 867 L_ATCU_Lib_2LHMngrTempBuf0 "23.11.10";
BA_ "Description" SG_ 867 L_ATCU_Lib_2RHMngrTempBuf0 "This value only use for ATCU Library data monitoring (Only use before SOP)";
BA_ "GenSigSendType" SG_ 867 L_ATCU_Lib_2RHMngrTempBuf0 4;
BA_ "UserSigValidity" SG_ 867 L_ATCU_Lib_2RHMngrTempBuf0 0;
BA_REL_ "GenSigTimeoutTime" BU_SG_REL_ L_ATCU_vMON SG_ 867 L_ATCU_Lib_2RHMngrTempBuf0 5000;
BA_ "Version" SG_ 867 L_ATCU_Lib_2RHMngrTempBuf0 "23.11.10";
BA_ "Description" SG_ 867 L_ATCU_Lib_2RHMngrTempBuf1 "This value only use for ATCU Library data monitoring (Only use before SOP)";
BA_ "GenSigSendType" SG_ 867 L_ATCU_Lib_2RHMngrTempBuf1 4;
BA_ "UserSigValidity" SG_ 867 L_ATCU_Lib_2RHMngrTempBuf1 0;
BA_REL_ "GenSigTimeoutTime" BU_SG_REL_ L_ATCU_vMON SG_ 867 L_ATCU_Lib_2RHMngrTempBuf1 5000;
BA_ "Version" SG_ 867 L_ATCU_Lib_2RHMngrTempBuf1 "23.11.10";
BA_ "Description" SG_ 867 L_ATCU_Lib_2RHMngrTempBuf2 "This value only use for ATCU Library data monitoring (Only use before SOP)";
BA_ "GenSigSendType" SG_ 867 L_ATCU_Lib_2RHMngrTempBuf2 4;
BA_ "UserSigValidity" SG_ 867 L_ATCU_Lib_2RHMngrTempBuf2 0;
BA_REL_ "GenSigTimeoutTime" BU_SG_REL_ L_ATCU_vMON SG_ 867 L_ATCU_Lib_2RHMngrTempBuf2 5000;
BA_ "Version" SG_ 867 L_ATCU_Lib_2RHMngrTempBuf2 "23.11.10";
BA_ "Description" SG_ 867 L_ATCU_Lib_2LHMngrTempBuf1 "This value only use for ATCU Library data monitoring (Only use before SOP)";
BA_ "GenSigSendType" SG_ 867 L_ATCU_Lib_2LHMngrTempBuf1 4;
BA_ "UserSigValidity" SG_ 867 L_ATCU_Lib_2LHMngrTempBuf1 0;
BA_REL_ "GenSigTimeoutTime" BU_SG_REL_ L_ATCU_vMON SG_ 867 L_ATCU_Lib_2LHMngrTempBuf1 5000;
BA_ "Version" SG_ 867 L_ATCU_Lib_2LHMngrTempBuf1 "23.11.10";
BA_ "Description" SG_ 867 L_ATCU_Lib_2LHMngrTempBuf2 "This value only use for ATCU Library data monitoring (Only use before SOP)";
BA_ "GenSigSendType" SG_ 867 L_ATCU_Lib_2LHMngrTempBuf2 4;
BA_ "UserSigValidity" SG_ 867 L_ATCU_Lib_2LHMngrTempBuf2 0;
BA_REL_ "GenSigTimeoutTime" BU_SG_REL_ L_ATCU_vMON SG_ 867 L_ATCU_Lib_2LHMngrTempBuf2 5000;
BA_ "Version" SG_ 867 L_ATCU_Lib_2LHMngrTempBuf2 "23.11.10";
BA_ "GenMsgSendType" BO_ 868 0;
BA_ "GenMsgCycleTime" BO_ 868 1000;
BA_ "Description" SG_ 868 L_ATCU_Lib_SWVer "Local CAN Signal to check library application version";
BA_ "GenSigSendType" SG_ 868 L_ATCU_Lib_SWVer 4;
BA_ "UserSigValidity" SG_ 868 L_ATCU_Lib_SWVer 0;
BA_REL_ "GenSigTimeoutTime" BU_SG_REL_ L_ATCU_vMON SG_ 868 L_ATCU_Lib_SWVer 3000;
BA_ "Version" SG_ 868 L_ATCU_Lib_SWVer "25.05.03";
BA_ "Description" SG_ 868 L_ATCU_Lib_BlrMax "ATCU Library Blower Manager Buffer Max Data";
BA_ "GenSigSendType" SG_ 868 L_ATCU_Lib_BlrMax 4;
BA_ "UserSigValidity" SG_ 868 L_ATCU_Lib_BlrMax 0;
BA_REL_ "GenSigTimeoutTime" BU_SG_REL_ L_ATCU_vMON SG_ 868 L_ATCU_Lib_BlrMax 3000;
BA_ "Version" SG_ 868 L_ATCU_Lib_BlrMax "25.05.03";
BA_ "Description" SG_ 868 L_ATCU_Lib_ModMax "ATCU Library Mode Manager Buffer Max Data";
BA_ "GenSigSendType" SG_ 868 L_ATCU_Lib_ModMax 4;
BA_ "UserSigValidity" SG_ 868 L_ATCU_Lib_ModMax 0;
BA_REL_ "GenSigTimeoutTime" BU_SG_REL_ L_ATCU_vMON SG_ 868 L_ATCU_Lib_ModMax 3000;
BA_ "Version" SG_ 868 L_ATCU_Lib_ModMax "25.05.03";
BA_ "Description" SG_ 868 L_ATCU_Lib_IntakeMax "ATCU Library Intake Manager Buffer Max Data";
BA_ "GenSigSendType" SG_ 868 L_ATCU_Lib_IntakeMax 4;
BA_ "UserSigValidity" SG_ 868 L_ATCU_Lib_IntakeMax 0;
BA_REL_ "GenSigTimeoutTime" BU_SG_REL_ L_ATCU_vMON SG_ 868 L_ATCU_Lib_IntakeMax 3000;
BA_ "Version" SG_ 868 L_ATCU_Lib_IntakeMax "25.05.03";
BA_ "Description" SG_ 868 L_ATCU_Lib_ACMax "ATCU Library AC Manager Buffer Max Data";
BA_ "GenSigSendType" SG_ 868 L_ATCU_Lib_ACMax 4;
BA_ "UserSigValidity" SG_ 868 L_ATCU_Lib_ACMax 0;
BA_REL_ "GenSigTimeoutTime" BU_SG_REL_ L_ATCU_vMON SG_ 868 L_ATCU_Lib_ACMax 3000;
BA_ "Version" SG_ 868 L_ATCU_Lib_ACMax "25.05.03";
BA_ "GenMsgSendType" BO_ 869 0;
BA_ "GenMsgCycleTime" BO_ 869 2000;
BA_ "Description" SG_ 869 L_ATCU_Lib_StatMngr_Humid "This value only use for ATCU Library data monitoring (Only use before SOP)";
BA_ "GenSigSendType" SG_ 869 L_ATCU_Lib_StatMngr_Humid 4;
BA_ "UserSigValidity" SG_ 869 L_ATCU_Lib_StatMngr_Humid 0;
BA_REL_ "GenSigTimeoutTime" BU_SG_REL_ L_ATCU_vMON SG_ 869 L_ATCU_Lib_StatMngr_Humid 5000;
BA_ "Version" SG_ 869 L_ATCU_Lib_StatMngr_Humid "24.09.01";
BA_ "GenMsgSendType" BO_ 870 0;
BA_ "GenMsgCycleTime" BO_ 870 2000;
BA_ "Description" SG_ 870 L_ATCU_Lib_StatMngr_Temp "This value only use for ATCU Library data monitoring (Only use before SOP)";
BA_ "GenSigSendType" SG_ 870 L_ATCU_Lib_StatMngr_Temp 4;
BA_ "UserSigValidity" SG_ 870 L_ATCU_Lib_StatMngr_Temp 0;
BA_REL_ "GenSigTimeoutTime" BU_SG_REL_ L_ATCU_vMON SG_ 870 L_ATCU_Lib_StatMngr_Temp 5000;
BA_ "Version" SG_ 870 L_ATCU_Lib_StatMngr_Temp "24.09.01";
BA_ "GenMsgSendType" BO_ 871 0;
BA_ "GenMsgCycleTime" BO_ 871 2000;
BA_ "Description" SG_ 871 L_ATCU_Lib_StatMngr_SafetynCool "This value only use for ATCU Library data monitoring (Only use before SOP)";
BA_ "GenSigSendType" SG_ 871 L_ATCU_Lib_StatMngr_SafetynCool 4;
BA_ "UserSigValidity" SG_ 871 L_ATCU_Lib_StatMngr_SafetynCool 0;
BA_REL_ "GenSigTimeoutTime" BU_SG_REL_ L_ATCU_vMON SG_ 871 L_ATCU_Lib_StatMngr_SafetynCool 5000;
BA_ "Version" SG_ 871 L_ATCU_Lib_StatMngr_SafetynCool "24.09.01";
BA_ "GenMsgSendType" BO_ 872 0;
BA_ "GenMsgCycleTime" BO_ 872 2000;
BA_ "Description" SG_ 872 L_ATCU_Lib_StatMngr_Mngr "This value only use for ATCU Library data monitoring (Only use before SOP)";
BA_ "GenSigSendType" SG_ 872 L_ATCU_Lib_StatMngr_Mngr 4;
BA_ "UserSigValidity" SG_ 872 L_ATCU_Lib_StatMngr_Mngr 0;
BA_REL_ "GenSigTimeoutTime" BU_SG_REL_ L_ATCU_vMON SG_ 872 L_ATCU_Lib_StatMngr_Mngr 5000;
BA_ "Version" SG_ 872 L_ATCU_Lib_StatMngr_Mngr "24.09.01";
BA_ "GenMsgSendType" BO_ 873 0;
BA_ "GenMsgCycleTime" BO_ 873 2000;
BA_ "Description" SG_ 873 L_ATCU_Lib_StatMngr_Convenience "This value only use for ATCU Library data monitoring (Only use before SOP)";
BA_ "GenSigSendType" SG_ 873 L_ATCU_Lib_StatMngr_Convenience 4;
BA_ "UserSigValidity" SG_ 873 L_ATCU_Lib_StatMngr_Convenience 0;
BA_REL_ "GenSigTimeoutTime" BU_SG_REL_ L_ATCU_vMON SG_ 873 L_ATCU_Lib_StatMngr_Convenience 5000;
BA_ "Version" SG_ 873 L_ATCU_Lib_StatMngr_Convenience "24.09.01";
BA_ "GenMsgSendType" BO_ 874 0;
BA_ "GenMsgCycleTime" BO_ 874 2000;
BA_ "Description" SG_ 874 L_ATCU_Lib_StatMngr_AirQuality "This value only use for ATCU Library data monitoring (Only use before SOP)";
BA_ "GenSigSendType" SG_ 874 L_ATCU_Lib_StatMngr_AirQuality 4;
BA_ "UserSigValidity" SG_ 874 L_ATCU_Lib_StatMngr_AirQuality 0;
BA_REL_ "GenSigTimeoutTime" BU_SG_REL_ L_ATCU_vMON SG_ 874 L_ATCU_Lib_StatMngr_AirQuality 5000;
BA_ "Version" SG_ 874 L_ATCU_Lib_StatMngr_AirQuality "24.09.01";
BA_ "GenMsgSendType" BO_ 875 0;
BA_ "GenMsgCycleTime" BO_ 875 2000;
BA_ "Description" SG_ 875 L_ATCU_Lib_StatMngr_ETC "This value only use for ATCU Library data monitoring (Only use before SOP)";
BA_ "GenSigSendType" SG_ 875 L_ATCU_Lib_StatMngr_ETC 4;
BA_ "UserSigValidity" SG_ 875 L_ATCU_Lib_StatMngr_ETC 0;
BA_REL_ "GenSigTimeoutTime" BU_SG_REL_ L_ATCU_vMON SG_ 875 L_ATCU_Lib_StatMngr_ETC 5000;
BA_ "Version" SG_ 875 L_ATCU_Lib_StatMngr_ETC "24.09.01";
BA_ "GenMsgSendType" BO_ 876 0;
BA_ "GenMsgCycleTime" BO_ 876 2000;
BA_ "Description" SG_ 876 L_ATCU_Lib_StatMngr_FuelEfficiency "This value only use for ATCU Library data monitoring (Only use before SOP)";
BA_ "GenSigSendType" SG_ 876 L_ATCU_Lib_StatMngr_FuelEfficiency 4;
BA_ "UserSigValidity" SG_ 876 L_ATCU_Lib_StatMngr_FuelEfficiency 0;
BA_REL_ "GenSigTimeoutTime" BU_SG_REL_ L_ATCU_vMON SG_ 876 L_ATCU_Lib_StatMngr_FuelEfficiency 5000;
BA_ "Version" SG_ 876 L_ATCU_Lib_StatMngr_FuelEfficiency "24.09.01";
BA_ "GenMsgSendType" BO_ 877 0;
BA_ "GenMsgCycleTime" BO_ 877 2000;
BA_ "Description" SG_ 877 L_ATCU_Lib_StatMngr_Snsr "This value only use for ATCU Library data monitoring (Only use before SOP)";
BA_ "GenSigSendType" SG_ 877 L_ATCU_Lib_StatMngr_Snsr 4;
BA_ "UserSigValidity" SG_ 877 L_ATCU_Lib_StatMngr_Snsr 0;
BA_REL_ "GenSigTimeoutTime" BU_SG_REL_ L_ATCU_vMON SG_ 877 L_ATCU_Lib_StatMngr_Snsr 5000;
BA_ "Version" SG_ 877 L_ATCU_Lib_StatMngr_Snsr "24.09.01";
BA_ "GenMsgSendType" BO_ 878 0;
BA_ "GenMsgCycleTime" BO_ 878 2000;
BA_ "Description" SG_ 878 L_ATCU_Lib_StatMngr_2ndHumid "This value only use for ATCU Library data monitoring (Only use before SOP)";
BA_ "GenSigSendType" SG_ 878 L_ATCU_Lib_StatMngr_2ndHumid 4;
BA_ "UserSigValidity" SG_ 878 L_ATCU_Lib_StatMngr_2ndHumid 0;
BA_REL_ "GenSigTimeoutTime" BU_SG_REL_ L_ATCU_vMON SG_ 878 L_ATCU_Lib_StatMngr_2ndHumid 5000;
BA_ "Version" SG_ 878 L_ATCU_Lib_StatMngr_2ndHumid "24.09.01";
BA_ "GenMsgSendType" BO_ 879 0;
BA_ "GenMsgCycleTime" BO_ 879 2000;
BA_ "Description" SG_ 879 L_ATCU_Lib_StatMngr_2ndTemp "This value only use for ATCU Library data monitoring (Only use before SOP)";
BA_ "GenSigSendType" SG_ 879 L_ATCU_Lib_StatMngr_2ndTemp 4;
BA_ "UserSigValidity" SG_ 879 L_ATCU_Lib_StatMngr_2ndTemp 0;
BA_REL_ "GenSigTimeoutTime" BU_SG_REL_ L_ATCU_vMON SG_ 879 L_ATCU_Lib_StatMngr_2ndTemp 5000;
BA_ "Version" SG_ 879 L_ATCU_Lib_StatMngr_2ndTemp "24.09.01";
BA_ "GenMsgCycleTime" BO_ 1040 0;
BA_ "GenSigSendType" SG_ 1040 L_EVNT_FrDrEVntAutoFlowOSDReq 4;
BA_ "UserSigValidity" SG_ 1040 L_EVNT_FrDrEVntAutoFlowOSDReq 7;
BA_REL_ "GenSigTimeoutTime" BU_SG_REL_ L_ATCU SG_ 1040 L_EVNT_FrDrEVntAutoFlowOSDReq 0;
BA_ "Version" SG_ 1040 L_EVNT_FrDrEVntAutoFlowOSDReq "25.09.01";
BA_ "GenSigSendType" SG_ 1040 L_EVNT_FrAstEVntAutoFlowOSDReq 4;
BA_ "UserSigValidity" SG_ 1040 L_EVNT_FrAstEVntAutoFlowOSDReq 7;
BA_REL_ "GenSigTimeoutTime" BU_SG_REL_ L_ATCU SG_ 1040 L_EVNT_FrAstEVntAutoFlowOSDReq 0;
BA_ "Version" SG_ 1040 L_EVNT_FrAstEVntAutoFlowOSDReq "25.09.01";
BA_ "GenMsgSendType" BO_ 320 0;
BA_ "GenMsgCycleTime" BO_ 320 20;
BA_ "GenMsgCycleTimeFast" BO_ 320 0;
BA_ "GenMsgNrOfRepetition" BO_ 320 0;
BA_ "GenMsgDelayTime" BO_ 320 0;
BA_ "UserSigValidity" SG_ 320 FHPTC_DrRdySta 7;
BA_ "Version" SG_ 320 FHPTC_DrRdySta "23.08.08";
BA_ "UserSigValidity" SG_ 320 FHPTC_DrOpSta 7;
BA_ "Version" SG_ 320 FHPTC_DrOpSta "23.08.08";
BA_ "UserSigValidity" SG_ 320 FHPTC_DrCnsmptPwr_W 7;
BA_ "Version" SG_ 320 FHPTC_DrCnsmptPwr_W "23.08.08";
BA_ "UserSigValidity" SG_ 320 FHPTC_DrCurrent_A 7;
BA_ "Version" SG_ 320 FHPTC_DrCurrent_A "23.08.08";
BA_ "UserSigValidity" SG_ 320 FHPTC_DrCoreTemp_C 7;
BA_ "Version" SG_ 320 FHPTC_DrCoreTemp_C "23.08.08";
BA_ "Description" SG_ 320 FHPTC_DrDutyFB_Pec "Duty Conversion to PTC Consumption power value, 40w~6kw -> 10%~95%";
BA_ "UserSigValidity" SG_ 320 FHPTC_DrDutyFB_Pec 7;
BA_ "Version" SG_ 320 FHPTC_DrDutyFB_Pec "23.08.08";
BA_ "Description" SG_ 320 FHPTC_DrDutyFB_IGBT "PWM DUTY of PTC IGBT (0~100%)";
BA_ "UserSigValidity" SG_ 320 FHPTC_DrDutyFB_IGBT 7;
BA_ "Version" SG_ 320 FHPTC_DrDutyFB_IGBT "23.08.08";
BA_ "UserSigValidity" SG_ 320 FHPTC_DrCtrlTyp 7;
BA_ "Version" SG_ 320 FHPTC_DrCtrlTyp "23.08.08";
BA_ "UserSigValidity" SG_ 320 FHPTC_DrVoltage_V 7;
BA_ "Version" SG_ 320 FHPTC_DrVoltage_V "23.08.08";
BA_ "GenMsgSendType" BO_ 321 0;
BA_ "GenMsgCycleTime" BO_ 321 20;
BA_ "GenMsgCycleTimeFast" BO_ 321 0;
BA_ "GenMsgNrOfRepetition" BO_ 321 0;
BA_ "GenMsgDelayTime" BO_ 321 0;
BA_ "UserSigValidity" SG_ 321 FHPTC_DrFlt 7;
BA_ "Version" SG_ 321 FHPTC_DrFlt "23.08.08";
BA_ "UserSigValidity" SG_ 321 FHPTC_DrFltLVLow 7;
BA_ "Version" SG_ 321 FHPTC_DrFltLVLow "23.08.08";
BA_ "UserSigValidity" SG_ 321 FHPTC_DrFailLVSnr 7;
BA_ "Version" SG_ 321 FHPTC_DrFailLVSnr "23.08.08";
BA_ "UserSigValidity" SG_ 321 FHPTC_DrFailCurrentSnr 7;
BA_ "Version" SG_ 321 FHPTC_DrFailCurrentSnr "23.08.08";
BA_ "UserSigValidity" SG_ 321 FHPTC_DrFailCoreTempSnr 7;
BA_ "Version" SG_ 321 FHPTC_DrFailCoreTempSnr "23.08.08";
BA_ "UserSigValidity" SG_ 321 FHPTC_DrFailPcbTempSnr 7;
BA_ "Version" SG_ 321 FHPTC_DrFailPcbTempSnr "23.08.08";
BA_ "UserSigValidity" SG_ 321 FHPTC_DrFailIGBT 7;
BA_ "Version" SG_ 321 FHPTC_DrFailIGBT "23.08.08";
BA_ "UserSigValidity" SG_ 321 FHPTC_DrFailOpenLoad 7;
BA_ "Version" SG_ 321 FHPTC_DrFailOpenLoad "23.08.08";
BA_ "UserSigValidity" SG_ 321 FHPTC_DrLtdOpCause 7;
BA_ "Version" SG_ 321 FHPTC_DrLtdOpCause "23.08.08";
BA_ "UserSigValidity" SG_ 321 FHPTC_DrFltLVHigh 7;
BA_ "Version" SG_ 321 FHPTC_DrFltLVHigh "23.08.08";
BA_ "UserSigValidity" SG_ 321 FHPTC_DrSwVer 7;
BA_ "Version" SG_ 321 FHPTC_DrSwVer "23.08.08";
BA_ "UserSigValidity" SG_ 321 FHPTC_DrFltHVLow 7;
BA_ "Version" SG_ 321 FHPTC_DrFltHVLow "23.08.08";
BA_ "Description" SG_ 321 FHPTC_CnsmptPwrTtl_W "Total Power Consumption Value = FHPTC_DrConsumptionPower_W + FHPTC_PassConsumptionPower_W";
BA_ "UserSigValidity" SG_ 321 FHPTC_CnsmptPwrTtl_W 7;
BA_ "Version" SG_ 321 FHPTC_CnsmptPwrTtl_W "23.08.08";
BA_ "UserSigValidity" SG_ 321 FHPTC_DrFltHVHigh 7;
BA_ "Version" SG_ 321 FHPTC_DrFltHVHigh "23.08.08";
BA_ "UserSigValidity" SG_ 321 FHPTC_IntlkSta 7;
BA_ "Version" SG_ 321 FHPTC_IntlkSta "25.04.02";
BA_ "UserSigValidity" SG_ 321 FHPTC_DrFltOverCurrent 7;
BA_ "Version" SG_ 321 FHPTC_DrFltOverCurrent "23.08.08";
BA_ "UserSigValidity" SG_ 321 FHPTC_DrFltThermalShutDn 7;
BA_ "Version" SG_ 321 FHPTC_DrFltThermalShutDn "23.08.08";
BA_ "UserSigValidity" SG_ 321 FHPTC_DrFltPcbThermalShutDn 7;
BA_ "Version" SG_ 321 FHPTC_DrFltPcbThermalShutDn "23.08.08";
BA_ "UserSigValidity" SG_ 321 FHPTC_DrFltMsgTmOutATCU 7;
BA_ "Version" SG_ 321 FHPTC_DrFltMsgTmOutATCU "23.08.08";
BA_ "UserSigValidity" SG_ 321 FHPTC_DrFailHVSnr 7;
BA_ "Version" SG_ 321 FHPTC_DrFailHVSnr "23.08.08";
BA_ "GenMsgSendType" BO_ 322 0;
BA_ "GenMsgCycleTime" BO_ 322 20;
BA_ "GenMsgCycleTimeFast" BO_ 322 0;
BA_ "GenMsgNrOfRepetition" BO_ 322 0;
BA_ "GenMsgDelayTime" BO_ 322 0;
BA_ "UserSigValidity" SG_ 322 FHPTC_PassRdySta 7;
BA_ "Version" SG_ 322 FHPTC_PassRdySta "23.08.08";
BA_ "UserSigValidity" SG_ 322 FHPTC_PassOpSta 7;
BA_ "Version" SG_ 322 FHPTC_PassOpSta "23.08.08";
BA_ "UserSigValidity" SG_ 322 FHPTC_PassCnsmptPwr_W 7;
BA_ "Version" SG_ 322 FHPTC_PassCnsmptPwr_W "23.08.08";
BA_ "UserSigValidity" SG_ 322 FHPTC_PassCtrlTyp 7;
BA_ "Version" SG_ 322 FHPTC_PassCtrlTyp "23.08.08";
BA_ "UserSigValidity" SG_ 322 FHPTC_PassVoltage_V 7;
BA_ "Version" SG_ 322 FHPTC_PassVoltage_V "23.08.08";
BA_ "UserSigValidity" SG_ 322 FHPTC_PassCurrent_A 7;
BA_ "Version" SG_ 322 FHPTC_PassCurrent_A "23.08.08";
BA_ "Description" SG_ 322 FHPTC_PassDutyFB_Pec "Duty Conversion to PTC Consumption power value, 40w~6kw -> 10%~95%";
BA_ "UserSigValidity" SG_ 322 FHPTC_PassDutyFB_Pec 7;
BA_ "Version" SG_ 322 FHPTC_PassDutyFB_Pec "23.08.08";
BA_ "Description" SG_ 322 FHPTC_PassDutyFB_IGBT "PWM DUTY of PTC IGBT (0~100%)";
BA_ "UserSigValidity" SG_ 322 FHPTC_PassDutyFB_IGBT 7;
BA_ "Version" SG_ 322 FHPTC_PassDutyFB_IGBT "23.08.08";
BA_ "UserSigValidity" SG_ 322 FHPTC_PassCoreTemp_C 7;
BA_ "Version" SG_ 322 FHPTC_PassCoreTemp_C "23.08.08";
BA_ "GenMsgSendType" BO_ 323 0;
BA_ "GenMsgCycleTime" BO_ 323 20;
BA_ "GenMsgCycleTimeFast" BO_ 323 0;
BA_ "GenMsgNrOfRepetition" BO_ 323 0;
BA_ "GenMsgDelayTime" BO_ 323 0;
BA_ "UserSigValidity" SG_ 323 FHPTC_PassFlt 7;
BA_ "Version" SG_ 323 FHPTC_PassFlt "23.08.08";
BA_ "UserSigValidity" SG_ 323 FHPTC_PassFltLVLow 7;
BA_ "Version" SG_ 323 FHPTC_PassFltLVLow "23.08.08";
BA_ "UserSigValidity" SG_ 323 FHPTC_PassFailLVSnr 7;
BA_ "Version" SG_ 323 FHPTC_PassFailLVSnr "23.08.08";
BA_ "UserSigValidity" SG_ 323 FHPTC_PassFailCurrentSnr 7;
BA_ "Version" SG_ 323 FHPTC_PassFailCurrentSnr "23.08.08";
BA_ "UserSigValidity" SG_ 323 FHPTC_PassFailCoreTempSnr 7;
BA_ "Version" SG_ 323 FHPTC_PassFailCoreTempSnr "23.08.08";
BA_ "UserSigValidity" SG_ 323 FHPTC_PassFailPcbTempSnr 7;
BA_ "Version" SG_ 323 FHPTC_PassFailPcbTempSnr "23.08.08";
BA_ "UserSigValidity" SG_ 323 FHPTC_PassFailIGBT 7;
BA_ "Version" SG_ 323 FHPTC_PassFailIGBT "23.08.08";
BA_ "UserSigValidity" SG_ 323 FHPTC_PassFailOpenLoad 7;
BA_ "Version" SG_ 323 FHPTC_PassFailOpenLoad "23.08.08";
BA_ "UserSigValidity" SG_ 323 FHPTC_PassLtdOpCause 7;
BA_ "Version" SG_ 323 FHPTC_PassLtdOpCause "23.08.08";
BA_ "UserSigValidity" SG_ 323 FHPTC_PassFltLVHigh 7;
BA_ "Version" SG_ 323 FHPTC_PassFltLVHigh "23.08.08";
BA_ "UserSigValidity" SG_ 323 FHPTC_PassSwVer 7;
BA_ "Version" SG_ 323 FHPTC_PassSwVer "23.08.08";
BA_ "UserSigValidity" SG_ 323 FHPTC_PassFltHVLow 7;
BA_ "Version" SG_ 323 FHPTC_PassFltHVLow "23.08.08";
BA_ "UserSigValidity" SG_ 323 FHPTC_PassFltHVHigh 7;
BA_ "Version" SG_ 323 FHPTC_PassFltHVHigh "23.08.08";
BA_ "UserSigValidity" SG_ 323 FHPTC_PassFltOverCurrent 7;
BA_ "Version" SG_ 323 FHPTC_PassFltOverCurrent "23.08.08";
BA_ "UserSigValidity" SG_ 323 FHPTC_PassFltThermalShutDn 7;
BA_ "Version" SG_ 323 FHPTC_PassFltThermalShutDn "23.08.08";
BA_ "UserSigValidity" SG_ 323 FHPTC_PassFltPcbThermalShutDn 7;
BA_ "Version" SG_ 323 FHPTC_PassFltPcbThermalShutDn "23.08.08";
BA_ "UserSigValidity" SG_ 323 FHPTC_PassFltMsgTmOutATCU 7;
BA_ "Version" SG_ 323 FHPTC_PassFltMsgTmOutATCU "23.08.08";
BA_ "UserSigValidity" SG_ 323 FHPTC_PassFailHVSnr 7;
BA_ "Version" SG_ 323 FHPTC_PassFailHVSnr "23.08.08";
BA_ "GenMsgSendType" BO_ 324 0;
BA_ "GenMsgCycleTime" BO_ 324 20;
BA_ "GenMsgCycleTimeFast" BO_ 324 0;
BA_ "GenMsgNrOfRepetition" BO_ 324 0;
BA_ "GenMsgDelayTime" BO_ 324 0;
BA_ "UserSigValidity" SG_ 324 FHPTC_2ndDrRdySta 7;
BA_ "Version" SG_ 324 FHPTC_2ndDrRdySta "24.02.06";
BA_ "UserSigValidity" SG_ 324 FHPTC_2ndDrOpSta 7;
BA_ "Version" SG_ 324 FHPTC_2ndDrOpSta "24.02.06";
BA_ "UserSigValidity" SG_ 324 FHPTC_2ndDrCnsmptPwr_W 7;
BA_ "Version" SG_ 324 FHPTC_2ndDrCnsmptPwr_W "24.02.06";
BA_ "UserSigValidity" SG_ 324 FHPTC_2ndDrCurrent_A 7;
BA_ "Version" SG_ 324 FHPTC_2ndDrCurrent_A "24.02.06";
BA_ "UserSigValidity" SG_ 324 FHPTC_2ndDrCoreTemp_C 7;
BA_ "Version" SG_ 324 FHPTC_2ndDrCoreTemp_C "24.02.06";
BA_ "Description" SG_ 324 FHPTC_2ndDrDutyFB_Pec "Duty Conversion to PTC Consumption power value, 40w~6kw -> 10%~95%";
BA_ "UserSigValidity" SG_ 324 FHPTC_2ndDrDutyFB_Pec 7;
BA_ "Version" SG_ 324 FHPTC_2ndDrDutyFB_Pec "24.02.06";
BA_ "Description" SG_ 324 FHPTC_2ndDrDutyFB_IGBT "PWM DUTY of PTC IGBT (0~100%)";
BA_ "UserSigValidity" SG_ 324 FHPTC_2ndDrDutyFB_IGBT 7;
BA_ "Version" SG_ 324 FHPTC_2ndDrDutyFB_IGBT "24.02.06";
BA_ "UserSigValidity" SG_ 324 FHPTC_2ndDrCtrlTyp 7;
BA_ "Version" SG_ 324 FHPTC_2ndDrCtrlTyp "24.02.06";
BA_ "UserSigValidity" SG_ 324 FHPTC_2ndDrVoltage_V 7;
BA_ "Version" SG_ 324 FHPTC_2ndDrVoltage_V "24.02.06";
BA_ "GenMsgSendType" BO_ 325 0;
BA_ "GenMsgCycleTime" BO_ 325 20;
BA_ "GenMsgCycleTimeFast" BO_ 325 0;
BA_ "GenMsgNrOfRepetition" BO_ 325 0;
BA_ "GenMsgDelayTime" BO_ 325 0;
BA_ "UserSigValidity" SG_ 325 FHPTC_2ndDrFlt 7;
BA_ "Version" SG_ 325 FHPTC_2ndDrFlt "24.02.06";
BA_ "UserSigValidity" SG_ 325 FHPTC_2ndDrFltLVLow 7;
BA_ "Version" SG_ 325 FHPTC_2ndDrFltLVLow "24.02.06";
BA_ "UserSigValidity" SG_ 325 FHPTC_2ndDrFailLVSnr 7;
BA_ "Version" SG_ 325 FHPTC_2ndDrFailLVSnr "24.02.06";
BA_ "UserSigValidity" SG_ 325 FHPTC_2ndDrFailCurrentSnr 7;
BA_ "Version" SG_ 325 FHPTC_2ndDrFailCurrentSnr "24.02.06";
BA_ "UserSigValidity" SG_ 325 FHPTC_2ndDrFailCoreTempSnr 7;
BA_ "Version" SG_ 325 FHPTC_2ndDrFailCoreTempSnr "24.02.06";
BA_ "UserSigValidity" SG_ 325 FHPTC_2ndDrFailPcbTempSnr 7;
BA_ "Version" SG_ 325 FHPTC_2ndDrFailPcbTempSnr "24.02.06";
BA_ "UserSigValidity" SG_ 325 FHPTC_2ndDrFailIGBT 7;
BA_ "Version" SG_ 325 FHPTC_2ndDrFailIGBT "24.02.06";
BA_ "UserSigValidity" SG_ 325 FHPTC_2ndDrFailOpenLoad 7;
BA_ "Version" SG_ 325 FHPTC_2ndDrFailOpenLoad "24.02.06";
BA_ "UserSigValidity" SG_ 325 FHPTC_2ndDrLtdOpCause 7;
BA_ "Version" SG_ 325 FHPTC_2ndDrLtdOpCause "24.02.06";
BA_ "UserSigValidity" SG_ 325 FHPTC_2ndDrFltLVHigh 7;
BA_ "Version" SG_ 325 FHPTC_2ndDrFltLVHigh "24.02.06";
BA_ "UserSigValidity" SG_ 325 FHPTC_2ndDrSwVer 7;
BA_ "Version" SG_ 325 FHPTC_2ndDrSwVer "24.02.06";
BA_ "UserSigValidity" SG_ 325 FHPTC_2ndDrFltHVLow 7;
BA_ "Version" SG_ 325 FHPTC_2ndDrFltHVLow "24.02.06";
BA_ "UserSigValidity" SG_ 325 FHPTC_2ndDrFltHVHigh 7;
BA_ "Version" SG_ 325 FHPTC_2ndDrFltHVHigh "24.02.06";
BA_ "UserSigValidity" SG_ 325 FHPTC_2ndDrFltOverCurrent 7;
BA_ "Version" SG_ 325 FHPTC_2ndDrFltOverCurrent "24.02.06";
BA_ "UserSigValidity" SG_ 325 FHPTC_2ndDrFltThermalShutDn 7;
BA_ "Version" SG_ 325 FHPTC_2ndDrFltThermalShutDn "24.02.06";
BA_ "UserSigValidity" SG_ 325 FHPTC_2ndDrFltPcbThermalShutDn 7;
BA_ "Version" SG_ 325 FHPTC_2ndDrFltPcbThermalShutDn "24.02.06";
BA_ "UserSigValidity" SG_ 325 FHPTC_2ndDrFltMsgTmOutATCU 7;
BA_ "Version" SG_ 325 FHPTC_2ndDrFltMsgTmOutATCU "24.02.06";
BA_ "UserSigValidity" SG_ 325 FHPTC_2ndDrFailHVSnr 7;
BA_ "Version" SG_ 325 FHPTC_2ndDrFailHVSnr "24.02.06";
BA_ "GenMsgSendType" BO_ 327 0;
BA_ "GenMsgCycleTime" BO_ 327 20;
BA_ "GenMsgCycleTimeFast" BO_ 327 0;
BA_ "GenMsgNrOfRepetition" BO_ 327 0;
BA_ "GenMsgDelayTime" BO_ 327 0;
BA_ "UserSigValidity" SG_ 327 FHPTC_2ndPsFlt 7;
BA_ "Version" SG_ 327 FHPTC_2ndPsFlt "24.02.06";
BA_ "UserSigValidity" SG_ 327 FHPTC_2ndPsFltLVLow 7;
BA_ "Version" SG_ 327 FHPTC_2ndPsFltLVLow "24.02.06";
BA_ "UserSigValidity" SG_ 327 FHPTC_2ndPsFailLVSnr 7;
BA_ "Version" SG_ 327 FHPTC_2ndPsFailLVSnr "24.02.06";
BA_ "UserSigValidity" SG_ 327 FHPTC_2ndPsFailCurrentSnr 7;
BA_ "Version" SG_ 327 FHPTC_2ndPsFailCurrentSnr "24.02.06";
BA_ "UserSigValidity" SG_ 327 FHPTC_2ndPsFailCoreTempSnr 7;
BA_ "Version" SG_ 327 FHPTC_2ndPsFailCoreTempSnr "24.02.06";
BA_ "UserSigValidity" SG_ 327 FHPTC_2ndPsFailPcbTempSnr 7;
BA_ "Version" SG_ 327 FHPTC_2ndPsFailPcbTempSnr "24.02.06";
BA_ "UserSigValidity" SG_ 327 FHPTC_2ndPsFailIGBT 7;
BA_ "Version" SG_ 327 FHPTC_2ndPsFailIGBT "24.02.06";
BA_ "UserSigValidity" SG_ 327 FHPTC_2ndPsFailOpenLoad 7;
BA_ "Version" SG_ 327 FHPTC_2ndPsFailOpenLoad "24.02.06";
BA_ "UserSigValidity" SG_ 327 FHPTC_2ndPsLtdOpCause 7;
BA_ "Version" SG_ 327 FHPTC_2ndPsLtdOpCause "24.02.06";
BA_ "UserSigValidity" SG_ 327 FHPTC_2ndPsFltLVHigh 7;
BA_ "Version" SG_ 327 FHPTC_2ndPsFltLVHigh "24.02.06";
BA_ "UserSigValidity" SG_ 327 FHPTC_2ndPsSwVer 7;
BA_ "Version" SG_ 327 FHPTC_2ndPsSwVer "24.02.06";
BA_ "UserSigValidity" SG_ 327 FHPTC_2ndPsFltHVLow 7;
BA_ "Version" SG_ 327 FHPTC_2ndPsFltHVLow "24.02.06";
BA_ "UserSigValidity" SG_ 327 FHPTC_2ndPsFltHVHigh 7;
BA_ "Version" SG_ 327 FHPTC_2ndPsFltHVHigh "24.02.06";
BA_ "UserSigValidity" SG_ 327 FHPTC_2ndPsFltOverCurrent 7;
BA_ "Version" SG_ 327 FHPTC_2ndPsFltOverCurrent "24.02.06";
BA_ "UserSigValidity" SG_ 327 FHPTC_2ndPsFltThermalShutDn 7;
BA_ "Version" SG_ 327 FHPTC_2ndPsFltThermalShutDn "24.02.06";
BA_ "UserSigValidity" SG_ 327 FHPTC_2ndPsFltPcbThermalShutDn 7;
BA_ "Version" SG_ 327 FHPTC_2ndPsFltPcbThermalShutDn "24.02.06";
BA_ "UserSigValidity" SG_ 327 FHPTC_2ndPsFltMsgTmOutATCU 7;
BA_ "Version" SG_ 327 FHPTC_2ndPsFltMsgTmOutATCU "24.02.06";
BA_ "UserSigValidity" SG_ 327 FHPTC_2ndPsFailHVSnr 7;
BA_ "Version" SG_ 327 FHPTC_2ndPsFailHVSnr "24.02.06";
BA_ "GenMsgSendType" BO_ 624 0;
BA_ "GenMsgCycleTime" BO_ 624 20;
BA_ "GenMsgCycleTimeFast" BO_ 624 0;
BA_ "GenMsgNrOfRepetition" BO_ 624 0;
BA_ "GenMsgDelayTime" BO_ 624 0;
BA_ "UserSigValidity" SG_ 624 PCM_ActPosFB 7;
BA_ "Version" SG_ 624 PCM_ActPosFB "24.02.06";
BA_ "UserSigValidity" SG_ 624 PCM_Blwr1Sta 7;
BA_ "Version" SG_ 624 PCM_Blwr1Sta "24.02.06";
BA_ "UserSigValidity" SG_ 624 PCM_Blwr2Sta 7;
BA_ "Version" SG_ 624 PCM_Blwr2Sta "24.02.06";
BA_ "UserSigValidity" SG_ 624 PCM_Blwr1Fail 7;
BA_ "Version" SG_ 624 PCM_Blwr1Fail "24.02.06";
BA_ "UserSigValidity" SG_ 624 PCM_Blwr2Fail 7;
BA_ "Version" SG_ 624 PCM_Blwr2Fail "24.02.06";
BA_ "UserSigValidity" SG_ 624 PCM_MainCtrlSta 7;
BA_ "Version" SG_ 624 PCM_MainCtrlSta "24.02.06";
BA_ "UserSigValidity" SG_ 624 PCM_Cart1Sta 7;
BA_ "Version" SG_ 624 PCM_Cart1Sta "24.02.06";
BA_ "UserSigValidity" SG_ 624 PCM_Cart2Sta 7;
BA_ "Version" SG_ 624 PCM_Cart2Sta "24.02.06";
BA_ "UserSigValidity" SG_ 624 PCM_Cart1Kinds 7;
BA_ "Version" SG_ 624 PCM_Cart1Kinds "24.02.06";
BA_ "UserSigValidity" SG_ 624 PCM_Cart2Kinds 7;
BA_ "Version" SG_ 624 PCM_Cart2Kinds "24.02.06";
BA_ "UserSigValidity" SG_ 624 PCM_ActSta 7;
BA_ "Version" SG_ 624 PCM_ActSta "24.02.06";
BA_ "UserSigValidity" SG_ 624 PCM_ActFail 7;
BA_ "Version" SG_ 624 PCM_ActFail "24.02.06";
BA_ "GenMsgSendType" BO_ 625 0;
BA_ "GenMsgCycleTime" BO_ 625 500;
BA_ "GenSigSendType" SG_ 625 PCM_Cart1VectorX 4;
BA_ "UserSigValidity" SG_ 625 PCM_Cart1VectorX 7;
BA_REL_ "GenSigTimeoutTime" BU_SG_REL_ L_ATCU SG_ 625 PCM_Cart1VectorX 5000;
BA_ "Version" SG_ 625 PCM_Cart1VectorX "24.02.06";
BA_ "GenSigSendType" SG_ 625 PCM_Cart1RmnPer 4;
BA_ "UserSigValidity" SG_ 625 PCM_Cart1RmnPer 7;
BA_REL_ "GenSigTimeoutTime" BU_SG_REL_ L_ATCU SG_ 625 PCM_Cart1RmnPer 5000;
BA_ "Version" SG_ 625 PCM_Cart1RmnPer "24.02.06";
BA_ "GenSigSendType" SG_ 625 PCM_Cart1ExpSta 4;
BA_ "UserSigValidity" SG_ 625 PCM_Cart1ExpSta 7;
BA_REL_ "GenSigTimeoutTime" BU_SG_REL_ L_ATCU SG_ 625 PCM_Cart1ExpSta 5000;
BA_ "Version" SG_ 625 PCM_Cart1ExpSta "24.02.06";
BA_ "GenSigSendType" SG_ 625 PCM_Cart1RmnDisp 4;
BA_ "UserSigValidity" SG_ 625 PCM_Cart1RmnDisp 7;
BA_REL_ "GenSigTimeoutTime" BU_SG_REL_ L_ATCU SG_ 625 PCM_Cart1RmnDisp 5000;
BA_ "Version" SG_ 625 PCM_Cart1RmnDisp "24.02.06";
BA_ "GenSigSendType" SG_ 625 PCM_Cart1VectorY 4;
BA_ "UserSigValidity" SG_ 625 PCM_Cart1VectorY 7;
BA_REL_ "GenSigTimeoutTime" BU_SG_REL_ L_ATCU SG_ 625 PCM_Cart1VectorY 5000;
BA_ "Version" SG_ 625 PCM_Cart1VectorY "24.02.06";
BA_ "GenMsgSendType" BO_ 626 0;
BA_ "GenMsgCycleTime" BO_ 626 500;
BA_ "GenSigSendType" SG_ 626 PCM_Cart2VectorX 4;
BA_ "UserSigValidity" SG_ 626 PCM_Cart2VectorX 7;
BA_REL_ "GenSigTimeoutTime" BU_SG_REL_ L_ATCU SG_ 626 PCM_Cart2VectorX 5000;
BA_ "Version" SG_ 626 PCM_Cart2VectorX "24.02.06";
BA_ "GenSigSendType" SG_ 626 PCM_Cart2RmnPer 4;
BA_ "UserSigValidity" SG_ 626 PCM_Cart2RmnPer 7;
BA_REL_ "GenSigTimeoutTime" BU_SG_REL_ L_ATCU SG_ 626 PCM_Cart2RmnPer 5000;
BA_ "Version" SG_ 626 PCM_Cart2RmnPer "24.02.06";
BA_ "GenSigSendType" SG_ 626 PCM_Cart2ExpSta 4;
BA_ "UserSigValidity" SG_ 626 PCM_Cart2ExpSta 7;
BA_REL_ "GenSigTimeoutTime" BU_SG_REL_ L_ATCU SG_ 626 PCM_Cart2ExpSta 5000;
BA_ "Version" SG_ 626 PCM_Cart2ExpSta "24.02.06";
BA_ "GenSigSendType" SG_ 626 PCM_Cart2RmnDisp 4;
BA_ "UserSigValidity" SG_ 626 PCM_Cart2RmnDisp 7;
BA_REL_ "GenSigTimeoutTime" BU_SG_REL_ L_ATCU SG_ 626 PCM_Cart2RmnDisp 5000;
BA_ "Version" SG_ 626 PCM_Cart2RmnDisp "24.02.06";
BA_ "GenSigSendType" SG_ 626 PCM_Cart2VectorY 4;
BA_ "UserSigValidity" SG_ 626 PCM_Cart2VectorY 7;
BA_REL_ "GenSigTimeoutTime" BU_SG_REL_ L_ATCU SG_ 626 PCM_Cart2VectorY 5000;
BA_ "Version" SG_ 626 PCM_Cart2VectorY "24.02.06";
VAL_ 97 L_2HKBD_SW_Ver1 0 "0x00~0x7E:ASCII value" 126 "0x00~0x7E:ASCII value" 127 "Invalid" ;
VAL_ 97 L_2HKBD_SW_Ver2 0 "0x00~0x7E:ASCII value" 126 "0x00~0x7E:ASCII value" 127 "Invalid" ;
VAL_ 97 L_2HKBD_SW_Ver3 0 "0x00~0x7E:ASCII value" 126 "0x00~0x7E:ASCII value" 127 "Invalid" ;
VAL_ 98 L_2HKBD_Rr_EvapVolVal 0 "0x0~0xFA:0~5V" 250 "0x0~0xFA:0~5V" 255 "Error Indicator" ;
VAL_ 98 L_2HKBD_Rr_TempActrSt 0 "Normal" 1 "Open" 2 "Short" 3 "Stuck" ;
VAL_ 98 L_2HKBD_Rr_TempAsstActrFB 1023 "Error Indicator" ;
VAL_ 98 L_2HKBD_Rr_TempAsstActrSt 0 "Normal" 1 "Open" 2 "Short" 3 "Stuck" ;
VAL_ 98 L_2HKBD_Rr_ModeActrFB 1023 "Error Indicator" ;
VAL_ 98 L_2HKBD_Rr_ModeActrSt 0 "Normal" 1 "Open" 2 "Short" 3 "Stuck" ;
VAL_ 98 L_2HKBD_Rr_BLDCError 0 "No error" 1 "Over Current" 2 "Under Voltage" 3 "Over Voltage" 4 "Stall" 5 "Over Temperature" 6 "Controller Shutdown (Internal Error)" 7 "Current Limit" 8 "Limp mode" 9 "LIN Fail" 10 "RESERVED" 11 "RESERVED" 12 "RESERVED" 13 "RESERVED" 14 "RESERVED" 15 "RESERVED" ;
VAL_ 98 L_2HKBD_Rr_TempActrFB 1023 "Error Indicator" ;
VAL_ 99 L_2HKBD_ResetOpSta 0 "Normal" 1 "Reset Complete" 2 "Reset Fail" 3 "RESERVED" ;
VAL_ 100 L_2HKBD_RrDrModeDnSw 0 "Off" 1 "On" ;
VAL_ 100 L_2HKBD_RrDrModeUpSw 0 "Off" 1 "On" ;
VAL_ 100 L_2HKBD_RrDrAutoSw 0 "Off" 1 "On" ;
VAL_ 100 L_2HKBD_Rr_OffSw 0 "Off" 1 "On" ;
VAL_ 100 L_2HKBD_RrSyncSw 0 "Off" 1 "On" ;
VAL_ 100 L_2HKBD_RrAcSw 0 "Off" 1 "On" ;
VAL_ 100 L_2HKBD_RLStHtrSwReq 0 "Off" 1 "On" ;
VAL_ 100 L_2HKBD_RLStVentSwReq 0 "Off" 1 "On" ;
VAL_ 100 L_2HKBD_RRStHtrSwReq 0 "Off" 1 "On" ;
VAL_ 100 L_2HKBD_RRStVentSwReq 0 "Off" 1 "On" ;
VAL_ 100 L_2HKBD_RrDrMultiAutoSw 0 "RESERVED" 1 "Low" 2 "Medium" 3 "High" 4 "RESERVED" 5 "RESERVED" 6 "RESERVED" 7 "Invalid" ;
VAL_ 100 L_2HKBD_RrDrModeSw 0 "Off" 1 "On" ;
VAL_ 100 L_2HKBD_RrPsModeSw 0 "Off" 1 "On" ;
VAL_ 100 L_2HKBD_RrPsModeDnSw 0 "Off" 1 "On" ;
VAL_ 100 L_2HKBD_RrPsModeUpSw 0 "Off" 1 "On" ;
VAL_ 100 L_2HKBD_RrPsModeVentSw 0 "Off" 1 "On" ;
VAL_ 100 L_2HKBD_RrPsModeFloorSw 0 "Off" 1 "On" ;
VAL_ 100 L_2HKBD_RrPsModeBiLvlSw 0 "Off" 1 "On" ;
VAL_ 100 L_2HKBD_RrPsTempDnSw 0 "Off" 1 "On" ;
VAL_ 100 L_2HKBD_RrPsTempUpSw 0 "Off" 1 "On" ;
VAL_ 100 L_2HKBD_RrPsBlwUpSw 0 "Off" 1 "On" ;
VAL_ 100 L_2HKBD_RrDRModeVentSw 0 "Off" 1 "On" ;
VAL_ 100 L_2HKBD_RrPsBlwDnSw 0 "Off" 1 "On" ;
VAL_ 100 L_2HKBD_RrPsAutoSw 0 "Off" 1 "On" ;
VAL_ 100 L_2HKBD_RrPsMultiAutoSw 0 "RESERVED" 1 "Low" 2 "Medium" 3 "High" 4 "RESERVED" 5 "RESERVED" 6 "RESERVED" 7 "Invalid" ;
VAL_ 100 L_2HKBD_RrDrBlwDnOffSw 0 "Off" 1 "On" ;
VAL_ 100 L_2HKBD_RrPsBlwDnOffSw 0 "Off" 1 "On" ;
VAL_ 100 L_2HKBD_RrOnOffSet 0 "Default" 1 "On" 2 "Off" 3 "Invalid" ;
VAL_ 100 L_2HKBD_RrDrblwUpMaxSw 0 "Off" 1 "On" ;
VAL_ 100 L_2HKBD_RrDrModeFloorSw 0 "Off" 1 "On" ;
VAL_ 100 L_2HKBD_RrPsblwUpMaxSw 0 "Off" 1 "On" ;
VAL_ 100 L_2HKBD_RrDrModeBiLvlSw 0 "Off" 1 "On" ;
VAL_ 100 L_2HKBD_RrDrTempDnSw 0 "Off" 1 "On" ;
VAL_ 100 L_2HKBD_RrDrTempUpSw 0 "Off" 1 "On" ;
VAL_ 100 L_2HKBD_RrDrBlwDnSw 0 "Off" 1 "On" ;
VAL_ 100 L_2HKBD_RrDrBlwUpSw 0 "Off" 1 "On" ;
VAL_ 101 L_2HKBD_RrFlrDuctSnsr 0 "0x0~0xFA:0~5V" 250 "0x0~0xFA:0~5V" 255 "Error Indicator" ;
VAL_ 101 L_2HKBD_RrVntDuctSnsr 0 "0x0~0xFA:0~5V" 250 "0x0~0xFA:0~5V" 255 "Error Indicator" ;
VAL_ 102 L_2HKBD_RrDrTempClickCnt 0 "RESERVED" 1 "01~0x7F:Clockwise" 127 "01~0x7F:Clockwise" 128 "80~0xFE:Counter Clockwise" 254 "80~0xFE:Counter Clockwise" 255 "Invalid" ;
VAL_ 102 L_2HKBD_RrPsTempClickCnt 0 "RESERVED" 1 "01~0x7F:Clockwise" 127 "01~0x7F:Clockwise" 128 "80~0xFE:Counter Clockwise" 254 "80~0xFE:Counter Clockwise" 255 "Invalid" ;
VAL_ 102 L_2HKBD_RrPsBlwrClickCnt 0 "RESERVED" 1 "01~0x7F:Clockwise" 127 "01~0x7F:Clockwise" 128 "80~0xFE:Counter Clockwise" 254 "80~0xFE:Counter Clockwise" 255 "Invalid" ;
VAL_ 102 L_2HKBD_RrTempKnobCnt 0 "0" 1 "1" 2 "2" 3 "invlaid" ;
VAL_ 102 L_2HKBD_RrBlwKnobCnt 0 "0" 1 "1" 2 "2" 3 "invlaid" ;
VAL_ 102 L_2HKBD_RrCurtainBtn 0 "Default" 1 "Open ON" 2 "Close ON" 3 "Invalid" ;
VAL_ 102 L_2HKBD_HVACPnlBckLight_Res 0 "Invalid(Default)" 1 "On" 2 "Off" 3 "RESERVED" ;
VAL_ 102 L_2HKBD_RrDrBlwrClickCnt 0 "RESERVED" 1 "01~0x7F:Clockwise" 127 "01~0x7F:Clockwise" 128 "80~0xFE:Counter Clockwise" 254 "80~0xFE:Counter Clockwise" 255 "Invalid" ;
VAL_ 368 L_ATCU_AVNCluUSMReset 0 "Default" 1 "USM Reset" 2 "RESERVED" 3 "Invalid" ;
VAL_ 368 L_ATCU_HVACPnlBckLight_Set 0 "Invalid(Default)" 1 "On" 2 "Off" 3 "RESERVED" ;
VAL_ 849 L_ATCU_Lib_SnsrInCarTemp 0 "0x0~0x3EB:-40.0~60.0¡É" 1003 "0x0~0x3EB:-40.0~60.0¡É" 1004 "3EC~0xFFFE:RESERVED" 65534 "3EC~0xFFFE:RESERVED" 65535 "Invalid" ;
VAL_ 849 L_ATCU_Lib_SnsrAMBTemp 0 "0x0~0x3EB:-40.0~60.0¡É" 1003 "0x0~0x3EB:-40.0~60.0¡É" 1004 "3EC~0xFFFE:RESERVED" 65534 "3EC~0xFFFE:RESERVED" 65535 "Invalid" ;
VAL_ 849 L_ATCU_Lib_SnsrDOH 0 "0x0~0x64:0~100%" 100 "0x0~0x64:0~100%" 101 "65~0xFFFE:RESERVED" 65534 "65~0xFFFE:RESERVED" 65535 "Invalid" ;
VAL_ 849 L_ATCU_Lib_SnsrEvapTemp 0 "0x0~0x258:-20.0~40.0¡É" 600 "0x0~0x258:-20.0~40.0¡É" 601 "259~0xFFFE:RESERVED" 65534 "259~0xFFFE:RESERVED" 65535 "Invalid" ;
VAL_ 850 L_ATCU_Lib_SnsrWaterTemp 0 "0x0~0x60E0:-48.00~200.00¡É" 24800 "0x0~0x60E0:-48.00~200.00¡É" 24801 "60E1~0xFFFE:RESERVED" 65534 "60E1~0xFFFE:RESERVED" 65535 "Invalid" ;
VAL_ 850 L_ATCU_Lib_SnsrFineDust 0 "0x0~0xFF:0~255" 255 "0x0~0xFF:0~255" 256 "100~0xFFFE:RESERVED" 65534 "100~0xFFFE:RESERVED" 65535 "Invalid" ;
VAL_ 850 L_ATCU_Lib_SnsrLHPhoto 0 "0x0~0x1388:0~5.000V" 5000 "0x0~0x1388:0~5.000V" 5001 "1389~0xFFFE:RESERVED" 65534 "1389~0xFFFE:RESERVED" 65535 "Invalid" ;
VAL_ 850 L_ATCU_Lib_SnsrRHPhoto 0 "0x0~0x1388:0~5.000V" 5000 "0x0~0x1388:0~5.000V" 5001 "1389~0xFFFE:RESERVED" 65534 "1389~0xFFFE:RESERVED" 65535 "Invalid" ;
VAL_ 851 L_ATCU_Lib_SnsrDrvVentDuct 0 "0x0~0x640:-40.0~160.0¡É" 1600 "0x0~0x640:-40.0~160.0¡É" 1601 "641~0xFFFE:RESERVED" 65534 "641~0xFFFE:RESERVED" 65535 "Invalid" ;
VAL_ 851 L_ATCU_Lib_SnsrAstVentDuct 0 "0x0~0x640:-40.0~160.0¡É" 1600 "0x0~0x640:-40.0~160.0¡É" 1601 "641~0xFFFE:RESERVED" 65534 "641~0xFFFE:RESERVED" 65535 "Invalid" ;
VAL_ 851 L_ATCU_Lib_SnsrDrvFloorDuct 0 "0x0~0x640:-40.0~160.0¡É" 1600 "0x0~0x640:-40.0~160.0¡É" 1601 "641~0xFFFE:RESERVED" 65534 "641~0xFFFE:RESERVED" 65535 "Invalid" ;
VAL_ 851 L_ATCU_Lib_SnsrAstFloorDuct 0 "0x0~0x640:-40.0~160.0¡É" 1600 "0x0~0x640:-40.0~160.0¡É" 1601 "641~0xFFFE:RESERVED" 65534 "641~0xFFFE:RESERVED" 65535 "Invalid" ;
VAL_ 852 L_ATCU_Lib_Snsr2LHVentDuct 0 "0x0~0x640:-40.0~160.0¡É" 1600 "0x0~0x640:-40.0~160.0¡É" 1601 "641~0xFFFE:RESERVED" 65534 "641~0xFFFE:RESERVED" 65535 "Invalid" ;
VAL_ 852 L_ATCU_Lib_Snsr2LHFloorDuct 0 "0x0~0x640:-40.0~160.0¡É" 1600 "0x0~0x640:-40.0~160.0¡É" 1601 "641~0xFFFE:RESERVED" 65534 "641~0xFFFE:RESERVED" 65535 "Invalid" ;
VAL_ 852 L_ATCU_Lib_SnsrDEFDuct 0 "0x0~0x640:-40.0~160.0¡É" 1600 "0x0~0x640:-40.0~160.0¡É" 1601 "641~0xFFFE:RESERVED" 65534 "641~0xFFFE:RESERVED" 65535 "Invalid" ;
VAL_ 853 L_ATCU_Lib_OffSw 0 "Off" 1 "On" ;
VAL_ 853 L_ATCU_Lib_AutoSw 0 "Off" 1 "On" ;
VAL_ 853 L_ATCU_Lib_BlrDnOffReq 0 "Off" 1 "On" ;
VAL_ 853 L_ATCU_Lib_IntakeRECSw 0 "Off" 1 "On" ;
VAL_ 853 L_ATCU_Lib_IntakeFRESw 0 "Off" 1 "On" ;
VAL_ 853 L_ATCU_Lib_ACSw 0 "Off" 1 "On" ;
VAL_ 853 L_ATCU_Lib_DEFSw 0 "Off" 1 "On" ;
VAL_ 853 L_ATCU_Lib_DrvTempUpSw 0 "Off" 1 "On" ;
VAL_ 853 L_ATCU_Lib_DrvTempDnSw 0 "Off" 1 "On" ;
VAL_ 853 L_ATCU_Lib_AstTempUpSw 0 "Off" 1 "On" ;
VAL_ 853 L_ATCU_Lib_AstTempDnSw 0 "Off" 1 "On" ;
VAL_ 853 L_ATCU_Lib_SyncSw 0 "Off" 1 "On" ;
VAL_ 853 L_ATCU_Lib_ModSw 0 "Off" 1 "On" ;
VAL_ 853 L_ATCU_Lib_DrvOnlySw 0 "Off" 1 "On" ;
VAL_ 853 L_ATCU_Lib_ClimateSw 0 "Off" 1 "On" ;
VAL_ 853 L_ATCU_Lib_RearDEFSw 0 "Off" 1 "On" ;
VAL_ 853 L_ATCU_Lib_StrWhlSw 0 "Off" 1 "On" ;
VAL_ 853 L_ATCU_Lib_DrvSeatHeatSw 0 "Off" 1 "On" ;
VAL_ 853 L_ATCU_Lib_DrvSeatVentSw 0 "Off" 1 "On" ;
VAL_ 853 L_ATCU_Lib_AstSeatHeatSw 0 "Off" 1 "On" ;
VAL_ 853 L_ATCU_Lib_AstSeatVentSw 0 "Off" 1 "On" ;
VAL_ 853 L_ATCU_Lib_DrvSeatTumblerSw 0 "Off" 1 "Up" 2 "Down" 3 "RESERVED" ;
VAL_ 853 L_ATCU_Lib_ModUpSw 0 "Off" 1 "On" ;
VAL_ 853 L_ATCU_Lib_AstSeatTumblerSw 0 "Off" 1 "Up" 2 "Down" 3 "RESERVED" ;
VAL_ 853 L_ATCU_Lib_ModDnSw 0 "Off" 1 "On" ;
VAL_ 853 L_ATCU_Lib_BlrUpSw 0 "Off" 1 "On" ;
VAL_ 853 L_ATCU_Lib_BlrDnSw 0 "Off" 1 "On" ;
VAL_ 854 L_ATCU_Lib_OffSetSw 0 "Off" 1 "Release" 2 "Set" 3 "RESERVED" ;
VAL_ 854 L_ATCU_Lib_BlrSetSw 0 "None" 1 "1Step" 2 "2Step" 3 "3Step" 4 "4Step" 5 "5Step" 6 "6Step" 7 "7Step" 8 "8Step" 9 "DATC_Off" 10 "RESERVED" 11 "RESERVED" 12 "RESERVED" 13 "RESERVED" 14 "RESERVED" 15 "RESERVED" ;
VAL_ 854 L_ATCU_Lib_AutoSetSw 0 "Off" 1 "Release" 2 "Set" 3 "RESERVED" ;
VAL_ 854 L_ATCU_Lib_DEFSetSw 0 "Off" 1 "Release" 2 "Set" 3 "RESERVED" ;
VAL_ 854 L_ATCU_Lib_SyncSetSw 0 "Off" 1 "Release" 2 "Set" 3 "RESERVED" ;
VAL_ 854 L_ATCU_Lib_IntakeSetSw 0 "FRE(0.0%)" 1 "1~0x3E7:Intake(0.1~99.9%)" 999 "1~0x3E7:Intake(0.1~99.9%)" 1000 "REC(100.0%)" 1001 "RESERVED" 1002 "RESERVED" 1003 "RESERVED" 1004 "RESERVED" 1005 "RESERVED" 1006 "RESERVED" 1007 "RESERVED" 1008 "RESERVED" 1009 "RESERVED" 1010 "RESERVED" 1011 "RESERVED" 1012 "RESERVED" 1013 "RESERVED" 1014 "RESERVED" 1015 "RESERVED" 1016 "RESERVED" 1017 "RESERVED" 1018 "RESERVED" 1019 "RESERVED" 1020 "RESERVED" 1021 "RESERVED" 1022 "RESERVED" 1023 "None" ;
VAL_ 854 L_ATCU_Lib_DrvTempSetSw 0 "Off" 1 "Max_Cool" 2 "TempStep" 3 "TempStep" 4 "TempStep" 5 "TempStep" 6 "TempStep" 7 "TempStep" 8 "TempStep" 9 "TempStep" 10 "TempStep" 11 "TempStep" 12 "TempStep" 13 "TempStep" 14 "TempStep" 15 "TempStep" 16 "TempStep" 17 "TempStep" 18 "TempStep" 19 "TempStep" 20 "TempStep" 21 "TempStep" 22 "TempStep" 23 "Max_Hot" 24 "RESERVED" 25 "RESERVED" 26 "RESERVED" 27 "RESERVED" 28 "RESERVED" 29 "RESERVED" 30 "RESERVED" 31 "RESERVED" ;
VAL_ 854 L_ATCU_Lib_MultiAutoSetSw 0 "Off" 1 "1Step" 2 "2Step" 3 "3Step" ;
VAL_ 854 L_ATCU_Lib_AstTempSetSw 0 "Off" 1 "Max_Cool" 2 "TempStep" 3 "TempStep" 4 "TempStep" 5 "TempStep" 6 "TempStep" 7 "TempStep" 8 "TempStep" 9 "TempStep" 10 "TempStep" 11 "TempStep" 12 "TempStep" 13 "TempStep" 14 "TempStep" 15 "TempStep" 16 "TempStep" 17 "TempStep" 18 "TempStep" 19 "TempStep" 20 "TempStep" 21 "TempStep" 22 "TempStep" 23 "Max_Hot" 24 "RESERVED" 25 "RESERVED" 26 "RESERVED" 27 "RESERVED" 28 "RESERVED" 29 "RESERVED" 30 "RESERVED" 31 "RESERVED" ;
VAL_ 854 L_ATCU_Lib_DrvOnlySetSw 0 "Off" 1 "Release" 2 "Set" 3 "RESERVED" ;
VAL_ 854 L_ATCU_Lib_DrvTempClickCnt 0 "RESERVED" 1 "1~0x7F:clockwise" 127 "1~0x7F:clockwise" 128 "80~0xFE:Counterclockwise" 254 "80~0xFE:Counterclockwise" 255 "Invalid" ;
VAL_ 854 L_ATCU_Lib_AstTempClickCnt 0 "RESERVED" 1 "1~0x7F:clockwise" 127 "1~0x7F:clockwise" 128 "80~0xFE:Counterclockwise" 254 "80~0xFE:Counterclockwise" 255 "Invalid" ;
VAL_ 854 L_ATCU_Lib_ACSetSw 0 "Off" 1 "Release" 2 "Set" 3 "RESERVED" ;
VAL_ 854 L_ATCU_Lib_ModSetSw 0 "Off" 1 "Floor" 2 "Vent" 3 "BL" 4 "Def_EU" 5 "Mix" 6 "Def_Vent" 7 "All" 8 "Vent_Bleed" 9 "Floor_100" 10 "Warm_Floor" 11 "Cool_Mix" 12 "Def" 13 "RESERVED" 14 "RESERVED" 15 "None" ;
VAL_ 855 L_ATCU_Lib_2ndAutoSw 0 "Off" 1 "On" ;
VAL_ 855 L_ATCU_Lib_2ndAutoUpSw 0 "Off" 1 "On" ;
VAL_ 855 L_ATCU_Lib_2LHTempUpSw 0 "Off" 1 "On" ;
VAL_ 855 L_ATCU_Lib_2LHTempDnSw 0 "Off" 1 "On" ;
VAL_ 855 L_ATCU_Lib_2RHTempUpSw 0 "Off" 1 "On" ;
VAL_ 855 L_ATCU_Lib_2RHTempDnSw 0 "Off" 1 "On" ;
VAL_ 855 L_ATCU_Lib_2ndSyncSw 0 "Off" 1 "On" ;
VAL_ 855 L_ATCU_Lib_2ndLockSw 0 "Off" 1 "On" ;
VAL_ 855 L_ATCU_Lib_2LHSeatHeatSw 0 "Off" 1 "On" ;
VAL_ 855 L_ATCU_Lib_2LHSeatVentSw 0 "Off" 1 "On" ;
VAL_ 855 L_ATCU_Lib_2RHSeatHeatSw 0 "Off" 1 "On" ;
VAL_ 855 L_ATCU_Lib_2RHSeatVentSw 0 "Off" 1 "On" ;
VAL_ 855 L_ATCU_Lib_2ndAutoDnSw 0 "Off" 1 "On" ;
VAL_ 855 L_ATCU_Lib_2LHSeatTumblerSw 0 "Off" 1 "Up" 2 "Down" 3 "RESERVED" ;
VAL_ 855 L_ATCU_Lib_2RHSeatTumblerSw 0 "Off" 1 "Up" 2 "Down" 3 "RESERVED" ;
VAL_ 855 L_ATCU_Lib_2ndOffSetSw 0 "Off" 1 "Release" 2 "Set" 3 "RESERVED" ;
VAL_ 855 L_ATCU_Lib_2ndAutoSetSw 0 "Off" 1 "Release" 2 "Set" 3 "RESERVED" ;
VAL_ 855 L_ATCU_Lib_2ndMultiAutoSetSw 0 "Off" 1 "1Step" 2 "2Step" 3 "3Step" ;
VAL_ 855 L_ATCU_Lib_2LHModSw 0 "Off" 1 "On" ;
VAL_ 855 L_ATCU_Lib_2ndACSetSw 0 "Off" 1 "Release" 2 "Set" 3 "RESERVED" ;
VAL_ 855 L_ATCU_Lib_2LHModSetSw 0 "Off" 1 "Floor" 2 "Vent" 3 "BL" 4 "Def_EU" 5 "Mix" 6 "Def_Vent" 7 "All" 8 "Vent_Bleed" 9 "Floor_100" 10 "Warm_Floor" 11 "Cool_Mix" 12 "Def" 13 "RESERVED" 14 "RESERVED" 15 "None" ;
VAL_ 855 L_ATCU_Lib_2LHBlrSetSw 0 "None" 1 "1Step" 2 "2Step" 3 "3Step" 4 "4Step" 5 "5Step" 6 "6Step" 7 "7Step" 8 "8Step" 9 "DATC_Off" 10 "RESERVED" 11 "RESERVED" 12 "RESERVED" 13 "RESERVED" 14 "RESERVED" 15 "RESERVED" ;
VAL_ 855 L_ATCU_Lib_2LHModUpSw 0 "Off" 1 "On" ;
VAL_ 855 L_ATCU_Lib_2LHTempSetSw 0 "Off" 1 "Max_Cool" 2 "TempStep" 3 "TempStep" 4 "TempStep" 5 "TempStep" 6 "TempStep" 7 "TempStep" 8 "TempStep" 9 "TempStep" 10 "TempStep" 11 "TempStep" 12 "TempStep" 13 "TempStep" 14 "TempStep" 15 "TempStep" 16 "TempStep" 17 "TempStep" 18 "TempStep" 19 "TempStep" 20 "TempStep" 21 "TempStep" 22 "TempStep" 23 "Max_Hot" 24 "RESERVED" 25 "RESERVED" 26 "RESERVED" 27 "RESERVED" 28 "RESERVED" 29 "RESERVED" 30 "RESERVED" 31 "RESERVED" ;
VAL_ 855 L_ATCU_Lib_2ndSyncSetSw 0 "Off" 1 "Release" 2 "Set" 3 "RESERVED" ;
VAL_ 855 L_ATCU_Lib_2ndOffSw 0 "Off" 1 "On" ;
VAL_ 855 L_ATCU_Lib_2RHTempSetSw 0 "Off" 1 "Max_Cool" 2 "TempStep" 3 "TempStep" 4 "TempStep" 5 "TempStep" 6 "TempStep" 7 "TempStep" 8 "TempStep" 9 "TempStep" 10 "TempStep" 11 "TempStep" 12 "TempStep" 13 "TempStep" 14 "TempStep" 15 "TempStep" 16 "TempStep" 17 "TempStep" 18 "TempStep" 19 "TempStep" 20 "TempStep" 21 "TempStep" 22 "TempStep" 23 "Max_Hot" 24 "RESERVED" 25 "RESERVED" 26 "RESERVED" 27 "RESERVED" 28 "RESERVED" 29 "RESERVED" 30 "RESERVED" 31 "RESERVED" ;
VAL_ 855 L_ATCU_Lib_2LHModDnSw 0 "Off" 1 "On" ;
VAL_ 855 L_ATCU_Lib_2ndLockSetSw 0 "Off" 1 "Release" 2 "Set" 3 "RESERVED" ;
VAL_ 855 L_ATCU_Lib_DrvBlrClickCnt 0 "RESERVED" 1 "1~0x7F:clockwise" 127 "1~0x7F:clockwise" 128 "80~0xFE:Counterclockwise" 254 "80~0xFE:Counterclockwise" 255 "Invalid" ;
VAL_ 855 L_ATCU_Lib_2LHBlrUpSw 0 "Off" 1 "On" ;
VAL_ 855 L_ATCU_Lib_2LHBlrDnSw 0 "Off" 1 "On" ;
VAL_ 855 L_ATCU_Lib_2LHBlrDnOffReq 0 "Off" 1 "On" ;
VAL_ 855 L_ATCU_Lib_2ndACSw 0 "Off" 1 "On" ;
VAL_ 865 L_ATCU_Lib_MngrIntakeBuf0 0 "KeyOff" 1 "SmartVencForcedOn" 2 "RemoteFATC" 3 "RemoteFATC_DEF" 4 "AutoWash" 5 "Washer" 6 "ADS" 7 "Sunroof" 8 "Tunnel" 9 "AirPurify" 10 "DEF" 11 "MIX" 12 "FloorPurge" 13 "AQS_REC" 14 "AQS_FRE" 15 "FREbyTime" 16 "protectEvapRust" 17 "ManualSw_FRE" 18 "ManualSw_REC" 19 "SmrtVent" 20 "SysOff" 21 "MaxHot" 22 "MaxCool" 23 "StayMod" 24 "SchdldVent" 25 "AfterBlow" 26 "Auto_FRE" 27 "Num" 28 "RESERVED" 29 "RESERVED" 30 "RESERVED" 31 "RESERVED" ;
VAL_ 865 L_ATCU_Lib_MngrIntakeBufLow1 0 "PTG" 1 "PartialIntake" 2 "ISG" 3 "RESERVED" ;
VAL_ 865 L_ATCU_Lib_MngrIntakeBuf2 0 "KeyOff" 1 "SmartVencForcedOn" 2 "RemoteFATC" 3 "RemoteFATC_DEF" 4 "AutoWash" 5 "Washer" 6 "ADS" 7 "Sunroof" 8 "Tunnel" 9 "AirPurify" 10 "DEF" 11 "MIX" 12 "FloorPurge" 13 "AQS_REC" 14 "AQS_FRE" 15 "FREbyTime" 16 "protectEvapRust" 17 "ManualSw_FRE" 18 "ManualSw_REC" 19 "SmrtVent" 20 "SysOff" 21 "MaxHot" 22 "MaxCool" 23 "StayMod" 24 "SchdldVent" 25 "AfterBlow" 26 "Auto_FRE" 27 "Num" 28 "RESERVED" 29 "RESERVED" 30 "RESERVED" 31 "RESERVED" ;
VAL_ 865 L_ATCU_Lib_MngrTempBuf0 0 "MaxCool" 1 "MaxHot" 2 "Last" 3 "AfterBlow" 4 "Auto" 5 "Num" 6 "RESERVED" 7 "RESERVED" ;
VAL_ 865 L_ATCU_Lib_MngrIntakeBuf3 0 "KeyOff" 1 "SmartVencForcedOn" 2 "RemoteFATC" 3 "RemoteFATC_DEF" 4 "AutoWash" 5 "Washer" 6 "ADS" 7 "Sunroof" 8 "Tunnel" 9 "AirPurify" 10 "DEF" 11 "MIX" 12 "FloorPurge" 13 "AQS_REC" 14 "AQS_FRE" 15 "FREbyTime" 16 "protectEvapRust" 17 "ManualSw_FRE" 18 "ManualSw_REC" 19 "SmrtVent" 20 "SysOff" 21 "MaxHot" 22 "MaxCool" 23 "StayMod" 24 "SchdldVent" 25 "AfterBlow" 26 "Auto_FRE" 27 "Num" 28 "RESERVED" 29 "RESERVED" 30 "RESERVED" 31 "RESERVED" ;
VAL_ 865 L_ATCU_Lib_MngrTempBuf1 0 "MaxCool" 1 "MaxHot" 2 "Last" 3 "AfterBlow" 4 "Auto" 5 "Num" 6 "RESERVED" 7 "RESERVED" ;
VAL_ 865 L_ATCU_Lib_MngrIntakeBuf4 0 "KeyOff" 1 "SmartVencForcedOn" 2 "RemoteFATC" 3 "RemoteFATC_DEF" 4 "SMKRemoteFATC" 5 "Washer" 6 "ADS" 7 "Sunroof" 8 "Tunnel" 9 "AirPurify" 10 "DEF" 11 "MIX" 12 "FloorPurge" 13 "AQS_REC" 14 "AQS_FRE" 15 "FREbyTime" 16 "protectEvapRust" 17 "ManualSw_FRE" 18 "ManualSw_REC" 19 "SmrtVent" 20 "SysOff" 21 "MaxHot" 22 "MaxCool" 23 "StayMod" 24 "SchdldVent" 25 "AfterBlow" 26 "Auto_FRE" 27 "Num" 28 "RESERVED" 29 "RESERVED" 30 "RESERVED" 31 "RESERVED" ;
VAL_ 865 L_ATCU_Lib_MngrTempBuf2 0 "MaxCool" 1 "MaxHot" 2 "Last" 3 "AfterBlow" 4 "Auto" 5 "Num" 6 "RESERVED" 7 "RESERVED" ;
VAL_ 865 L_ATCU_Lib_MngrIntakeBuf5 0 "KeyOff" 1 "SmartVencForcedOn" 2 "RemoteFATC" 3 "RemoteFATC_DEF" 4 "SMKRemoteFATC" 5 "Washer" 6 "ADS" 7 "Sunroof" 8 "Tunnel" 9 "AirPurify" 10 "DEF" 11 "MIX" 12 "FloorPurge" 13 "AQS_REC" 14 "AQS_FRE" 15 "FREbyTime" 16 "protectEvapRust" 17 "ManualSw_FRE" 18 "ManualSw_REC" 19 "SmrtVent" 20 "SysOff" 21 "MaxHot" 22 "MaxCool" 23 "StayMod" 24 "SchdldVent" 25 "AfterBlow" 26 "Auto_FRE" 27 "Num" 28 "RESERVED" 29 "RESERVED" 30 "RESERVED" 31 "RESERVED" ;
VAL_ 865 L_ATCU_Lib_MngrTempBuf3 0 "MaxCool" 1 "MaxHot" 2 "Last" 3 "AfterBlow" 4 "Auto" 5 "Num" 6 "RESERVED" 7 "RESERVED" ;
VAL_ 865 L_ATCU_Lib_MngrIntakeBuf6 0 "KeyOff" 1 "SmartVencForcedOn" 2 "RemoteFATC" 3 "RemoteFATC_DEF" 4 "SMKRemoteFATC" 5 "Washer" 6 "ADS" 7 "Sunroof" 8 "Tunnel" 9 "AirPurify" 10 "DEF" 11 "MIX" 12 "FloorPurge" 13 "AQS_REC" 14 "AQS_FRE" 15 "FREbyTime" 16 "protectEvapRust" 17 "ManualSw_FRE" 18 "ManualSw_REC" 19 "SmrtVent" 20 "SysOff" 21 "MaxHot" 22 "MaxCool" 23 "StayMod" 24 "SchdldVent" 25 "AfterBlow" 26 "Auto_FRE" 27 "Num" 28 "RESERVED" 29 "RESERVED" 30 "RESERVED" 31 "RESERVED" ;
VAL_ 865 L_ATCU_Lib_MngrIntakeBufLow0 0 "PTG" 1 "PartialIntake" 2 "ISG" 3 "RESERVED" ;
VAL_ 865 L_ATCU_Lib_MngrTempBuf4 0 "MaxCool" 1 "MaxHot" 2 "Last" 3 "AfterBlow" 4 "Auto" 5 "Num" 6 "RESERVED" 7 "RESERVED" ;
VAL_ 865 L_ATCU_Lib_MngrIntakeBuf7 0 "KeyOff" 1 "SmartVencForcedOn" 2 "RemoteFATC" 3 "RemoteFATC_DEF" 4 "SMKRemoteFATC" 5 "Washer" 6 "ADS" 7 "Sunroof" 8 "Tunnel" 9 "AirPurify" 10 "DEF" 11 "MIX" 12 "FloorPurge" 13 "AQS_REC" 14 "AQS_FRE" 15 "FREbyTime" 16 "protectEvapRust" 17 "ManualSw_FRE" 18 "ManualSw_REC" 19 "SmrtVent" 20 "SysOff" 21 "MaxHot" 22 "MaxCool" 23 "StayMod" 24 "SchdldVent" 25 "AfterBlow" 26 "Auto_FRE" 27 "Num" 28 "RESERVED" 29 "RESERVED" 30 "RESERVED" 31 "RESERVED" ;
VAL_ 865 L_ATCU_Lib_MngrTempBufLow2 0 "EvapDry" 1 "ADS" 2 "PECbyDEF" 3 "Num" ;
VAL_ 865 L_ATCU_Lib_MngrIntakeBuf1 0 "KeyOff" 1 "SmartVencForcedOn" 2 "RemoteFATC" 3 "RemoteFATC_DEF" 4 "AutoWash" 5 "Washer" 6 "ADS" 7 "Sunroof" 8 "Tunnel" 9 "AirPurify" 10 "DEF" 11 "MIX" 12 "FloorPurge" 13 "AQS_REC" 14 "AQS_FRE" 15 "FREbyTime" 16 "protectEvapRust" 17 "ManualSw_FRE" 18 "ManualSw_REC" 19 "SmrtVent" 20 "SysOff" 21 "MaxHot" 22 "MaxCool" 23 "StayMod" 24 "SchdldVent" 25 "AfterBlow" 26 "Auto_FRE" 27 "Num" 28 "RESERVED" 29 "RESERVED" 30 "RESERVED" 31 "RESERVED" ;
VAL_ 866 L_ATCU_Lib_2LHMngrModBuf0 0 "KeyOff" 1 "ManualSw" 2 "MaxCool" 3 "HotStart" 4 "FootZone" 5 "MaxHot" 6 "Auto" 7 "Num" 8 "RESERVED" 9 "RESERVED" 10 "RESERVED" 11 "RESERVED" 12 "RESERVED" 13 "RESERVED" 14 "RESERVED" 15 "RESERVED" ;
VAL_ 866 L_ATCU_Lib_2LHMngrModBuf3 0 "KeyOff" 1 "ManualSw" 2 "MaxCool" 3 "HotStart" 4 "FootZone" 5 "MaxHot" 6 "Auto" 7 "Num" 8 "RESERVED" 9 "RESERVED" 10 "RESERVED" 11 "RESERVED" 12 "RESERVED" 13 "RESERVED" 14 "RESERVED" 15 "RESERVED" ;
VAL_ 866 L_ATCU_Lib_2LHMngrModBuf4 0 "KeyOff" 1 "ManualSw" 2 "MaxCool" 3 "HotStart" 4 "FootZone" 5 "MaxHot" 6 "Auto" 7 "Num" 8 "RESERVED" 9 "RESERVED" 10 "RESERVED" 11 "RESERVED" 12 "RESERVED" 13 "RESERVED" 14 "RESERVED" 15 "RESERVED" ;
VAL_ 866 L_ATCU_Lib_2LHMngrModBuf5 0 "KeyOff" 1 "ManualSw" 2 "MaxCool" 3 "HotStart" 4 "FootZone" 5 "MaxHot" 6 "Auto" 7 "Num" 8 "RESERVED" 9 "RESERVED" 10 "RESERVED" 11 "RESERVED" 12 "RESERVED" 13 "RESERVED" 14 "RESERVED" 15 "RESERVED" ;
VAL_ 866 L_ATCU_Lib_2LHMngrModBuf6 0 "KeyOff" 1 "ManualSw" 2 "MaxCool" 3 "HotStart" 4 "FootZone" 5 "MaxHot" 6 "Auto" 7 "Num" 8 "RESERVED" 9 "RESERVED" 10 "RESERVED" 11 "RESERVED" 12 "RESERVED" 13 "RESERVED" 14 "RESERVED" 15 "RESERVED" ;
VAL_ 866 L_ATCU_Lib_2LHMngrModBuf7 0 "KeyOff" 1 "ManualSw" 2 "MaxCool" 3 "HotStart" 4 "FootZone" 5 "MaxHot" 6 "Auto" 7 "Num" 8 "RESERVED" 9 "RESERVED" 10 "RESERVED" 11 "RESERVED" 12 "RESERVED" 13 "RESERVED" 14 "RESERVED" 15 "RESERVED" ;
VAL_ 866 L_ATCU_Lib_2LHMngrBlwBuf0 0 "MaxCool" 1 "HotStart" 2 "MaxHot" 3 "ManualSw" 4 "Auto" 5 "Num" 6 "RESERVED" 7 "RESERVED" 8 "RESERVED" 9 "RESERVED" 10 "RESERVED" 11 "RESERVED" 12 "RESERVED" 13 "RESERVED" 14 "RESERVED" 15 "RESERVED" ;
VAL_ 866 L_ATCU_Lib_2LHMngrBlwBuf1 0 "MaxCool" 1 "HotStart" 2 "MaxHot" 3 "ManualSw" 4 "Auto" 5 "Num" 6 "RESERVED" 7 "RESERVED" 8 "RESERVED" 9 "RESERVED" 10 "RESERVED" 11 "RESERVED" 12 "RESERVED" 13 "RESERVED" 14 "RESERVED" 15 "RESERVED" ;
VAL_ 866 L_ATCU_Lib_2LHMngrModBuf1 0 "KeyOff" 1 "ManualSw" 2 "MaxCool" 3 "HotStart" 4 "FootZone" 5 "MaxHot" 6 "Auto" 7 "Num" 8 "RESERVED" 9 "RESERVED" 10 "RESERVED" 11 "RESERVED" 12 "RESERVED" 13 "RESERVED" 14 "RESERVED" 15 "RESERVED" ;
VAL_ 866 L_ATCU_Lib_2LHMngrBlwBuf2 0 "StartBlower" 1 "MaxCool" 2 "HotStart" 3 "MaxHot" 4 "ManualSw" 5 "Auto" 6 "Num" 7 "RESERVED" 8 "RESERVED" 9 "RESERVED" 10 "RESERVED" 11 "RESERVED" 12 "RESERVED" 13 "RESERVED" 14 "RESERVED" 15 "RESERVED" ;
VAL_ 866 L_ATCU_Lib_2LHMngrBlwBuf3 0 "MaxCool" 1 "HotStart" 2 "MaxHot" 3 "ManualSw" 4 "Auto" 5 "Num" 6 "RESERVED" 7 "RESERVED" 8 "RESERVED" 9 "RESERVED" 10 "RESERVED" 11 "RESERVED" 12 "RESERVED" 13 "RESERVED" 14 "RESERVED" 15 "RESERVED" ;
VAL_ 866 L_ATCU_Lib_2LHMngrBlwBuf4 0 "MaxCool" 1 "HotStart" 2 "MaxHot" 3 "ManualSw" 4 "Auto" 5 "Num" 6 "RESERVED" 7 "RESERVED" 8 "RESERVED" 9 "RESERVED" 10 "RESERVED" 11 "RESERVED" 12 "RESERVED" 13 "RESERVED" 14 "RESERVED" 15 "RESERVED" ;
VAL_ 866 L_ATCU_Lib_2LHMngrBlwBuf5 0 "MaxCool" 1 "HotStart" 2 "MaxHot" 3 "ManualSw" 4 "Auto" 5 "Num" 6 "RESERVED" 7 "RESERVED" 8 "RESERVED" 9 "RESERVED" 10 "RESERVED" 11 "RESERVED" 12 "RESERVED" 13 "RESERVED" 14 "RESERVED" 15 "RESERVED" ;
VAL_ 866 L_ATCU_Lib_2LHMngrBlwBuf6 0 "MaxCool" 1 "HotStart" 2 "MaxHot" 3 "ManualSw" 4 "Auto" 5 "Num" 6 "RESERVED" 7 "RESERVED" 8 "RESERVED" 9 "RESERVED" 10 "RESERVED" 11 "RESERVED" 12 "RESERVED" 13 "RESERVED" 14 "RESERVED" 15 "RESERVED" ;
VAL_ 866 L_ATCU_Lib_2LHMngrBlwBufHi0 0 "AirFlowLinkage" 1 "ISG" 2 "Num" 3 "RESERVED" ;
VAL_ 866 L_ATCU_Lib_2LHMngrBlwBufHi1 0 "AirFlowLinkage" 1 "ISG" 2 "Num" 3 "RESERVED" ;
VAL_ 866 L_ATCU_Lib_2LHMngrModBuf2 0 "KeyOff" 1 "ManualSw" 2 "MaxCool" 3 "HotStart" 4 "FootZone" 5 "MaxHot" 6 "Auto" 7 "Num" 8 "RESERVED" 9 "RESERVED" 10 "RESERVED" 11 "RESERVED" 12 "RESERVED" 13 "RESERVED" 14 "RESERVED" 15 "RESERVED" ;
VAL_ 867 L_ATCU_Lib_2LHMngrTempBuf0 0 "MaxCool" 1 "MaxHot" 2 "Auto" 3 "Num" 4 "RESERVED" 5 "RESERVED" 6 "RESERVED" 7 "RESERVED" ;
VAL_ 867 L_ATCU_Lib_2RHMngrTempBuf0 0 "MaxCool" 1 "MaxHot" 2 "Auto" 3 "Num" 4 "RESERVED" 5 "RESERVED" 6 "RESERVED" 7 "RESERVED" ;
VAL_ 867 L_ATCU_Lib_2RHMngrTempBuf1 0 "MaxCool" 1 "MaxHot" 2 "Auto" 3 "Num" 4 "RESERVED" 5 "RESERVED" 6 "RESERVED" 7 "RESERVED" ;
VAL_ 867 L_ATCU_Lib_2RHMngrTempBuf2 0 "MaxCool" 1 "MaxHot" 2 "Auto" 3 "Num" 4 "RESERVED" 5 "RESERVED" 6 "RESERVED" 7 "RESERVED" ;
VAL_ 867 L_ATCU_Lib_2LHMngrTempBuf1 0 "MaxCool" 1 "MaxHot" 2 "Auto" 3 "Num" 4 "RESERVED" 5 "RESERVED" 6 "RESERVED" 7 "RESERVED" ;
VAL_ 867 L_ATCU_Lib_2LHMngrTempBuf2 0 "MaxCool" 1 "MaxHot" 2 "Auto" 3 "Num" 4 "RESERVED" 5 "RESERVED" 6 "RESERVED" 7 "RESERVED" ;
VAL_ 868 L_ATCU_Lib_SWVer 0 "0x00~0xFFFF:Only HEX, Not ASCII value" 65535 "0x00~0xFFFF:Only HEX, Not ASCII value" ;
VAL_ 1040 L_EVNT_FrDrEVntAutoFlowOSDReq 0 "Default" 1 "Mode Set (Drv)" 2 "Open/Close Set (Drv)" 3 "Invalid" ;
VAL_ 1040 L_EVNT_FrAstEVntAutoFlowOSDReq 2 "Open/Close Set (Ast)" 3 "Invalid" 0 "Default" 1 "Mode Set (Ast)" ;
VAL_ 320 FHPTC_DrRdySta 0 "Not Ready(Disable to control)" 1 "Ready (Enable to Control)" ;
VAL_ 320 FHPTC_DrOpSta 0 "Stop Mode" 1 "Operation Mode" 2 "Failure Mode" 3 "Limited operation Mode" ;
VAL_ 320 FHPTC_DrCnsmptPwr_W 0 "0x0~0x2710:Power" 10000 "0x0~0x2710:Power" 65535 "ERROR" ;
VAL_ 320 FHPTC_DrCurrent_A 0 "0x0~0xFA:Current" 250 "0x0~0xFA:Current" 251 "RESERVED" 252 "RESERVED" 253 "RESERVED" 254 "RESERVED" 255 "ERROR" ;
VAL_ 320 FHPTC_DrCoreTemp_C 0 "0x00~0xF0:Temperature" 240 "0x00~0xF0:Temperature" 241 "RESERVED" 242 "RESERVED" 243 "RESERVED" 244 "RESERVED" 245 "RESERVED" 246 "RESERVED" 247 "RESERVED" 248 "RESERVED" 249 "RESERVED" 250 "RESERVED" 251 "RESERVED" 252 "RESERVED" 253 "The thermister is open." 254 "The thermister is short." 255 "ERROR" ;
VAL_ 320 FHPTC_DrDutyFB_Pec 0 "0x0~0xC8:Duty" 200 "0x0~0xC8:Duty" 201 "RESERVED" 202 "RESERVED" 203 "RESERVED" 204 "RESERVED" 205 "RESERVED" 206 "RESERVED" 207 "RESERVED" 208 "RESERVED" 209 "RESERVED" 210 "RESERVED" 211 "RESERVED" 212 "RESERVED" 213 "RESERVED" 214 "RESERVED" 215 "RESERVED" 216 "RESERVED" 217 "RESERVED" 218 "RESERVED" 219 "RESERVED" 220 "RESERVED" 221 "RESERVED" 222 "RESERVED" 223 "RESERVED" 224 "RESERVED" 225 "RESERVED" 226 "RESERVED" 227 "RESERVED" 228 "RESERVED" 229 "RESERVED" 230 "RESERVED" 231 "RESERVED" 232 "RESERVED" 233 "RESERVED" 234 "RESERVED" 235 "RESERVED" 236 "RESERVED" 237 "RESERVED" 238 "RESERVED" 239 "RESERVED" 240 "RESERVED" 241 "RESERVED" 242 "RESERVED" 243 "RESERVED" 244 "RESERVED" 245 "RESERVED" 246 "RESERVED" 247 "RESERVED" 248 "RESERVED" 249 "RESERVED" 250 "RESERVED" 251 "RESERVED" 252 "RESERVED" 253 "RESERVED" 254 "RESERVED" 255 "ERROR" ;
VAL_ 320 FHPTC_DrDutyFB_IGBT 0 "0x0~0xC8:Duty" 200 "0x0~0xC8:Duty" 201 "RESERVED" 202 "RESERVED" 203 "RESERVED" 204 "RESERVED" 205 "RESERVED" 206 "RESERVED" 207 "RESERVED" 208 "RESERVED" 209 "RESERVED" 210 "RESERVED" 211 "RESERVED" 212 "RESERVED" 213 "RESERVED" 214 "RESERVED" 215 "RESERVED" 216 "RESERVED" 217 "RESERVED" 218 "RESERVED" 219 "RESERVED" 220 "RESERVED" 221 "RESERVED" 222 "RESERVED" 223 "RESERVED" 224 "RESERVED" 225 "RESERVED" 226 "RESERVED" 227 "RESERVED" 228 "RESERVED" 229 "RESERVED" 230 "RESERVED" 231 "RESERVED" 232 "RESERVED" 233 "RESERVED" 234 "RESERVED" 235 "RESERVED" 236 "RESERVED" 237 "RESERVED" 238 "RESERVED" 239 "RESERVED" 240 "RESERVED" 241 "RESERVED" 242 "RESERVED" 243 "RESERVED" 244 "RESERVED" 245 "RESERVED" 246 "RESERVED" 247 "RESERVED" 248 "RESERVED" 249 "RESERVED" 250 "RESERVED" 251 "RESERVED" 252 "RESERVED" 253 "RESERVED" 254 "RESERVED" 255 "ERROR" ;
VAL_ 320 FHPTC_DrCtrlTyp 0 "Single PTC & Single Control" 1 "Dual PTC & Single Control" 2 "Dual PTC & Dual Control" ;
VAL_ 320 FHPTC_DrVoltage_V 0 "0x0~0xFA:Voltage" 250 "0x0~0xFA:Voltage" 251 "RESERVED" 252 "RESERVED" 253 "RESERVED" 254 "RESERVED" 255 "ERROR" ;
VAL_ 321 FHPTC_DrFlt 0 "Normal" 1 "Fault" ;
VAL_ 321 FHPTC_DrFltLVLow 0 "Normal" 1 "Fault" ;
VAL_ 321 FHPTC_DrFailLVSnr 0 "Normal" 1 "Fault(Open or Short)" ;
VAL_ 321 FHPTC_DrFailCurrentSnr 0 "Normal" 1 "Fault(Open or Short)" ;
VAL_ 321 FHPTC_DrFailCoreTempSnr 0 "Normal" 1 "Fault(Open or Short)" ;
VAL_ 321 FHPTC_DrFailPcbTempSnr 0 "Normal" 1 "Fault(Open or Short)" ;
VAL_ 321 FHPTC_DrFailIGBT 0 "Normal" 1 "Fault" ;
VAL_ 321 FHPTC_DrFailOpenLoad 0 "Normal" 1 "Fault" ;
VAL_ 321 FHPTC_DrLtdOpCause 0 "Normal Operation" 1 "Ltd Operation by LVLowDr" 2 "Ltd Operation by LVHighDr" 3 "Ltd Operation by HVLowDr" 4 "Ltd Operation by HVHighDr" 5 "Ltd Operation by OverCurrentDr" 8 "Ltd Operation by ThermalShutDnDr" 9 "Ltd Operation by PCBThermalShutDnDr" 10 "A~0xFF:RESERVED" 255 "A~0xFF:RESERVED" ;
VAL_ 321 FHPTC_DrFltLVHigh 0 "Normal" 1 "Fault" ;
VAL_ 321 FHPTC_DrFltHVLow 0 "Normal" 1 "Fault" ;
VAL_ 321 FHPTC_CnsmptPwrTtl_W 0 "0x0~0x2710:Power" 10000 "0x0~0x2710:Power" 65535 "ERROR" ;
VAL_ 321 FHPTC_DrFltHVHigh 0 "Normal" 1 "Fault" ;
VAL_ 321 FHPTC_IntlkSta 0 "Disconnect" 1 "Connect" 2 "Default" 3 "Error Indicator" ;
VAL_ 321 FHPTC_DrFltOverCurrent 0 "Normal" 1 "Fault" ;
VAL_ 321 FHPTC_DrFltThermalShutDn 0 "Normal" 1 "Fault" ;
VAL_ 321 FHPTC_DrFltPcbThermalShutDn 0 "Normal" 1 "Fault" ;
VAL_ 321 FHPTC_DrFltMsgTmOutATCU 0 "Normal" 1 "Message Timeout" ;
VAL_ 321 FHPTC_DrFailHVSnr 0 "Normal" 1 "Fault(Open or Short)" ;
VAL_ 322 FHPTC_PassRdySta 0 "Not Ready(Disable to control)" 1 "Ready (Enable to Control)" ;
VAL_ 322 FHPTC_PassOpSta 0 "Stop Mode" 1 "Operation Mode" 2 "Failure Mode" 3 "Limited operation Mode" ;
VAL_ 322 FHPTC_PassCnsmptPwr_W 0 "0x0~0x2710:Power" 10000 "0x0~0x2710:Power" 65535 "ERROR" ;
VAL_ 322 FHPTC_PassCtrlTyp 0 "Single PTC & Single Control" 1 "Dual PTC & Single Control" 2 "Dual PTC & Dual Control" ;
VAL_ 322 FHPTC_PassVoltage_V 0 "0x0~0xFA:Voltage" 250 "0x0~0xFA:Voltage" 251 "RESERVED0xFF:ERROR" 252 "RESERVED0xFF:ERROR" 253 "RESERVED0xFF:ERROR" 254 "RESERVED0xFF:ERROR" ;
VAL_ 322 FHPTC_PassCurrent_A 0 "0x0~0xFA:Current" 250 "0x0~0xFA:Current" 251 "RESERVED" 252 "RESERVED" 253 "RESERVED" 254 "RESERVED" 255 "ERROR" ;
VAL_ 322 FHPTC_PassDutyFB_Pec 0 "0x0~0xC8:Duty" 200 "0x0~0xC8:Duty" 201 "RESERVED" 202 "RESERVED" 203 "RESERVED" 204 "RESERVED" 205 "RESERVED" 206 "RESERVED" 207 "RESERVED" 208 "RESERVED" 209 "RESERVED" 210 "RESERVED" 211 "RESERVED" 212 "RESERVED" 213 "RESERVED" 214 "RESERVED" 215 "RESERVED" 216 "RESERVED" 217 "RESERVED" 218 "RESERVED" 219 "RESERVED" 220 "RESERVED" 221 "RESERVED" 222 "RESERVED" 223 "RESERVED" 224 "RESERVED" 225 "RESERVED" 226 "RESERVED" 227 "RESERVED" 228 "RESERVED" 229 "RESERVED" 230 "RESERVED" 231 "RESERVED" 232 "RESERVED" 233 "RESERVED" 234 "RESERVED" 235 "RESERVED" 236 "RESERVED" 237 "RESERVED" 238 "RESERVED" 239 "RESERVED" 240 "RESERVED" 241 "RESERVED" 242 "RESERVED" 243 "RESERVED" 244 "RESERVED" 245 "RESERVED" 246 "RESERVED" 247 "RESERVED" 248 "RESERVED" 249 "RESERVED" 250 "RESERVED" 251 "RESERVED" 252 "RESERVED" 253 "RESERVED" 254 "RESERVED" 255 "ERROR" ;
VAL_ 322 FHPTC_PassDutyFB_IGBT 0 "0x0~0xC8:Duty" 200 "0x0~0xC8:Duty" 201 "RESERVED" 202 "RESERVED" 203 "RESERVED" 204 "RESERVED" 205 "RESERVED" 206 "RESERVED" 207 "RESERVED" 208 "RESERVED" 209 "RESERVED" 210 "RESERVED" 211 "RESERVED" 212 "RESERVED" 213 "RESERVED" 214 "RESERVED" 215 "RESERVED" 216 "RESERVED" 217 "RESERVED" 218 "RESERVED" 219 "RESERVED" 220 "RESERVED" 221 "RESERVED" 222 "RESERVED" 223 "RESERVED" 224 "RESERVED" 225 "RESERVED" 226 "RESERVED" 227 "RESERVED" 228 "RESERVED" 229 "RESERVED" 230 "RESERVED" 231 "RESERVED" 232 "RESERVED" 233 "RESERVED" 234 "RESERVED" 235 "RESERVED" 236 "RESERVED" 237 "RESERVED" 238 "RESERVED" 239 "RESERVED" 240 "RESERVED" 241 "RESERVED" 242 "RESERVED" 243 "RESERVED" 244 "RESERVED" 245 "RESERVED" 246 "RESERVED" 247 "RESERVED" 248 "RESERVED" 249 "RESERVED" 250 "RESERVED" 251 "RESERVED" 252 "RESERVED" 253 "RESERVED" 254 "RESERVED" 255 "ERROR" ;
VAL_ 322 FHPTC_PassCoreTemp_C 0 "0x0~0xF0:Temperature" 240 "0x0~0xF0:Temperature" 241 "RESERVED/0XFD:The thermister is open" 242 "RESERVED/0XFD:The thermister is open" 243 "RESERVED/0XFD:The thermister is open" 244 "RESERVED/0XFD:The thermister is open" 245 "RESERVED/0XFD:The thermister is open" 246 "RESERVED/0XFD:The thermister is open" 247 "RESERVED/0XFD:The thermister is open" 248 "RESERVED/0XFD:The thermister is open" 249 "RESERVED/0XFD:The thermister is open" 250 "RESERVED/0XFD:The thermister is open" 251 "RESERVED/0XFD:The thermister is open" 252 "RESERVED/0XFD:The thermister is open" 254 "The thermister is short" 255 "ERROR" ;
VAL_ 323 FHPTC_PassFlt 0 "Normal" 1 "Fault" ;
VAL_ 323 FHPTC_PassFltLVLow 0 "Normal" 1 "Fault" ;
VAL_ 323 FHPTC_PassFailLVSnr 0 "Normal" 1 "Fault(Open or Short)" ;
VAL_ 323 FHPTC_PassFailCurrentSnr 0 "Normal" 1 "Fault(Open or Short)" ;
VAL_ 323 FHPTC_PassFailCoreTempSnr 0 "Normal" 1 "Fault(Open or Short)" ;
VAL_ 323 FHPTC_PassFailPcbTempSnr 0 "Normal" 1 "Fault(Open or Short)" ;
VAL_ 323 FHPTC_PassFailIGBT 0 "Normal" 1 "Fault" ;
VAL_ 323 FHPTC_PassFailOpenLoad 0 "Normal" 1 "Fault" ;
VAL_ 323 FHPTC_PassLtdOpCause 0 "Normal Operation" 1 "Ltd Operation by LVLowDr" 2 "Ltd Operation by LVHighDr" 3 "Ltd Operation by HVLowDr" 4 "Ltd Operation by HVHighDr" 5 "Ltd Operation by OverCurrentDr" ;
VAL_ 323 FHPTC_PassFltLVHigh 0 "Normal" 1 "Fault" ;
VAL_ 323 FHPTC_PassFltHVLow 0 "Normal" 1 "Fault" ;
VAL_ 323 FHPTC_PassFltHVHigh 0 "Normal" 1 "Fault" ;
VAL_ 323 FHPTC_PassFltOverCurrent 0 "Normal" 1 "Fault" ;
VAL_ 323 FHPTC_PassFltThermalShutDn 0 "Normal" 1 "Fault" ;
VAL_ 323 FHPTC_PassFltPcbThermalShutDn 0 "Normal" 1 "Fault" ;
VAL_ 323 FHPTC_PassFltMsgTmOutATCU 0 "Normal" 1 "Message Timeout" ;
VAL_ 323 FHPTC_PassFailHVSnr 0 "Normal" 1 "Fault(Open or Short)" ;
VAL_ 324 FHPTC_2ndDrRdySta 0 "Not Ready(Disable to control)" 1 "Ready (Enable to Control)" ;
VAL_ 324 FHPTC_2ndDrOpSta 0 "Stop Mode" 1 "Operation Mode" 2 "Failure Mode" 3 "Limited operation Mode" ;
VAL_ 324 FHPTC_2ndDrCnsmptPwr_W 0 "0x0~0x2710:Power" 10000 "0x0~0x2710:Power" 65535 "ERROR" ;
VAL_ 324 FHPTC_2ndDrCurrent_A 0 "0x0~0xFA:Current" 250 "0x0~0xFA:Current" 251 "RESERVED" 252 "RESERVED" 253 "RESERVED" 254 "RESERVED" 255 "ERROR" ;
VAL_ 324 FHPTC_2ndDrCoreTemp_C 0 "0x00~0xF0:Temperature" 240 "0x00~0xF0:Temperature" 241 "RESERVED" 242 "RESERVED" 243 "RESERVED" 244 "RESERVED" 245 "RESERVED" 246 "RESERVED" 247 "RESERVED" 248 "RESERVED" 249 "RESERVED" 250 "RESERVED" 251 "RESERVED" 252 "RESERVED" 253 "The thermister is open." 254 "The thermister is short." 255 "ERROR" ;
VAL_ 324 FHPTC_2ndDrDutyFB_Pec 0 "0x0~0xC8:Duty" 200 "0x0~0xC8:Duty" 201 "RESERVED" 202 "RESERVED" 203 "RESERVED" 204 "RESERVED" 205 "RESERVED" 206 "RESERVED" 207 "RESERVED" 208 "RESERVED" 209 "RESERVED" 210 "RESERVED" 211 "RESERVED" 212 "RESERVED" 213 "RESERVED" 214 "RESERVED" 215 "RESERVED" 216 "RESERVED" 217 "RESERVED" 218 "RESERVED" 219 "RESERVED" 220 "RESERVED" 221 "RESERVED" 222 "RESERVED" 223 "RESERVED" 224 "RESERVED" 225 "RESERVED" 226 "RESERVED" 227 "RESERVED" 228 "RESERVED" 229 "RESERVED" 230 "RESERVED" 231 "RESERVED" 232 "RESERVED" 233 "RESERVED" 234 "RESERVED" 235 "RESERVED" 236 "RESERVED" 237 "RESERVED" 238 "RESERVED" 239 "RESERVED" 240 "RESERVED" 241 "RESERVED" 242 "RESERVED" 243 "RESERVED" 244 "RESERVED" 245 "RESERVED" 246 "RESERVED" 247 "RESERVED" 248 "RESERVED" 249 "RESERVED" 250 "RESERVED" 251 "RESERVED" 252 "RESERVED" 253 "RESERVED" 254 "RESERVED" 255 "ERROR" ;
VAL_ 324 FHPTC_2ndDrDutyFB_IGBT 0 "0x0~0xC8:Duty" 200 "0x0~0xC8:Duty" 201 "RESERVED" 202 "RESERVED" 203 "RESERVED" 204 "RESERVED" 205 "RESERVED" 206 "RESERVED" 207 "RESERVED" 208 "RESERVED" 209 "RESERVED" 210 "RESERVED" 211 "RESERVED" 212 "RESERVED" 213 "RESERVED" 214 "RESERVED" 215 "RESERVED" 216 "RESERVED" 217 "RESERVED" 218 "RESERVED" 219 "RESERVED" 220 "RESERVED" 221 "RESERVED" 222 "RESERVED" 223 "RESERVED" 224 "RESERVED" 225 "RESERVED" 226 "RESERVED" 227 "RESERVED" 228 "RESERVED" 229 "RESERVED" 230 "RESERVED" 231 "RESERVED" 232 "RESERVED" 233 "RESERVED" 234 "RESERVED" 235 "RESERVED" 236 "RESERVED" 237 "RESERVED" 238 "RESERVED" 239 "RESERVED" 240 "RESERVED" 241 "RESERVED" 242 "RESERVED" 243 "RESERVED" 244 "RESERVED" 245 "RESERVED" 246 "RESERVED" 247 "RESERVED" 248 "RESERVED" 249 "RESERVED" 250 "RESERVED" 251 "RESERVED" 252 "RESERVED" 253 "RESERVED" 254 "RESERVED" 255 "ERROR" ;
VAL_ 324 FHPTC_2ndDrCtrlTyp 0 "Single PTC & Single Control" 1 "Dual PTC & Single Control" 2 "Dual PTC & Dual Control" ;
VAL_ 324 FHPTC_2ndDrVoltage_V 0 "0x0~0xFA:Voltage" 250 "0x0~0xFA:Voltage" 251 "RESERVED" 252 "RESERVED" 253 "RESERVED" 254 "RESERVED" 255 "ERROR" ;
VAL_ 325 FHPTC_2ndDrFlt 0 "Normal" 1 "Fault" ;
VAL_ 325 FHPTC_2ndDrFltLVLow 0 "Normal" 1 "Fault" ;
VAL_ 325 FHPTC_2ndDrFailLVSnr 0 "Normal" 1 "Fault(Open or Short)" ;
VAL_ 325 FHPTC_2ndDrFailCurrentSnr 0 "Normal" 1 "Fault(Open or Short)" ;
VAL_ 325 FHPTC_2ndDrFailCoreTempSnr 0 "Normal" 1 "Fault(Open or Short)" ;
VAL_ 325 FHPTC_2ndDrFailPcbTempSnr 0 "Normal" 1 "Fault(Open or Short)" ;
VAL_ 325 FHPTC_2ndDrFailIGBT 0 "Normal" 1 "Fault" ;
VAL_ 325 FHPTC_2ndDrFailOpenLoad 0 "Normal" 1 "Fault" ;
VAL_ 325 FHPTC_2ndDrLtdOpCause 0 "Normal Operation" 1 "Ltd Operation by LVLowDr" 2 "Ltd Operation by LVHighDr" 3 "Ltd Operation by HVLowDr" 4 "Ltd Operation by HVHighDr" 5 "Ltd Operation by OverCurrentDr" 8 "Ltd Operation by ThermalShutDnDr" 9 "Ltd Operation by PCBThermalShutDnDr" 10 "A~0xFF:RESERVED" 255 "A~0xFF:RESERVED" ;
VAL_ 325 FHPTC_2ndDrFltLVHigh 0 "Normal" 1 "Fault" ;
VAL_ 325 FHPTC_2ndDrFltHVLow 0 "Normal" 1 "Fault" ;
VAL_ 325 FHPTC_2ndDrFltHVHigh 0 "Normal" 1 "Fault" ;
VAL_ 325 FHPTC_2ndDrFltOverCurrent 0 "Normal" 1 "Fault" ;
VAL_ 325 FHPTC_2ndDrFltThermalShutDn 0 "Normal" 1 "Fault" ;
VAL_ 325 FHPTC_2ndDrFltPcbThermalShutDn 0 "Normal" 1 "Fault" ;
VAL_ 325 FHPTC_2ndDrFltMsgTmOutATCU 0 "Normal" 1 "Message Timeout" ;
VAL_ 325 FHPTC_2ndDrFailHVSnr 0 "Normal" 1 "Fault(Open or Short)" ;
VAL_ 327 FHPTC_2ndPsFlt 0 "Normal" 1 "Fault" ;
VAL_ 327 FHPTC_2ndPsFltLVLow 0 "Normal" 1 "Fault" ;
VAL_ 327 FHPTC_2ndPsFailLVSnr 0 "Normal" 1 "Fault(Open or Short)" ;
VAL_ 327 FHPTC_2ndPsFailCurrentSnr 0 "Normal" 1 "Fault(Open or Short)" ;
VAL_ 327 FHPTC_2ndPsFailCoreTempSnr 0 "Normal" 1 "Fault(Open or Short)" ;
VAL_ 327 FHPTC_2ndPsFailPcbTempSnr 0 "Normal" 1 "Fault(Open or Short)" ;
VAL_ 327 FHPTC_2ndPsFailIGBT 0 "Normal" 1 "Fault" ;
VAL_ 327 FHPTC_2ndPsFailOpenLoad 0 "Normal" 1 "Fault" ;
VAL_ 327 FHPTC_2ndPsLtdOpCause 0 "Normal Operation" 1 "Ltd Operation by LVLowDr" 2 "Ltd Operation by LVHighDr" 3 "Ltd Operation by HVLowDr" 4 "Ltd Operation by HVHighDr" 5 "Ltd Operation by OverCurrentDr" ;
VAL_ 327 FHPTC_2ndPsFltLVHigh 0 "Normal" 1 "Fault" ;
VAL_ 327 FHPTC_2ndPsFltHVLow 0 "Normal" 1 "Fault" ;
VAL_ 327 FHPTC_2ndPsFltHVHigh 0 "Normal" 1 "Fault" ;
VAL_ 327 FHPTC_2ndPsFltOverCurrent 0 "Normal" 1 "Fault" ;
VAL_ 327 FHPTC_2ndPsFltThermalShutDn 0 "Normal" 1 "Fault" ;
VAL_ 327 FHPTC_2ndPsFltPcbThermalShutDn 0 "Normal" 1 "Fault" ;
VAL_ 327 FHPTC_2ndPsFltMsgTmOutATCU 0 "Normal" 1 "Message Timeout" ;
VAL_ 327 FHPTC_2ndPsFailHVSnr 0 "Normal" 1 "Fault(Open or Short)" ;
VAL_ 624 PCM_ActPosFB 0 "OFF" 1 "Cartridge#1" 2 "Cartridge#2" 3 "Calibrating" 4 "Moving - #1 to #2" 5 "Moving - #1 to Off" 6 "Moving - #2 to #1" 7 "Moving - #2 to Off" 8 "Moving Off to #1" 9 "Moving Off to #2" 10 "RESERVED" 11 "RESERVED" 12 "RESERVED" 13 "RESERVED" 14 "RESERVED" 15 "Error Indicator" ;
VAL_ 624 PCM_Blwr1Sta 0 "Normal OFF" 1 "Normal ON" 2 "Temporary Failure" 3 "Permanent Failure" ;
VAL_ 624 PCM_Blwr2Sta 0 "Normal OFF" 1 "Normal ON" 2 "Temporary Failure" 3 "Permanent Failure" ;
VAL_ 624 PCM_Blwr1Fail 0 "Normal" 1 "Circuit Open/Short (internal error, diagnosis/Siganl line open/short)" 2 "Motor Stall" 3 "Over Current" 4 "Over Temperature" 5 "Under Voltage" 6 "Over Voltage" 7 "reserved" ;
VAL_ 624 PCM_Blwr2Fail 0 "Normal" 1 "Circuit Open/Short (internal error, diagnosis/Siganl line open/short)" 2 "Motor Stall" 3 "Over Current" 4 "Over Temperature" 5 "Under Voltage" 6 "Over Voltage" 7 "reserved" ;
VAL_ 624 PCM_MainCtrlSta 0 "Initialization" 1 "Normal" 2 "Abnormal" 3 "reserved" ;
VAL_ 624 PCM_Cart1Sta 0 "Contacted, Normal" 1 "Reserved" 2 "Temporary Failure" 3 "Not-Contacted" ;
VAL_ 624 PCM_Cart2Sta 0 "Contacted, Normal" 1 "Reserved" 2 "Temporary Failure" 3 "Not-Contacted" ;
VAL_ 624 PCM_Cart1Kinds 0 "Default" 1 "THE DRIVER'S AWAKENING" 2 "MY FAVOURITE PLACE" 3 "THE CREAT OUTDOORS" 4 "RESERVED" 5 "RESERVED" 6 "RESERVED" 7 "RESERVED" 8 "RESERVED" 9 "RESERVED" 10 "RESERVED" 11 "RESERVED" 12 "New Frangrance Mounted(Genuine cartidge, Not registered new frangrance)" 13 "No Cartridge Mounted" 14 "Unknown Cartridge Mounted (Not Genuine cartidge)" 15 "Error Indicator" ;
VAL_ 624 PCM_Cart2Kinds 0 "Default" 1 "THE DRIVER'S AWAKENING" 2 "MY FAVOURITE PLACE" 3 "THE CREAT OUTDOORS" 4 "RESERVED" 5 "RESERVED" 6 "RESERVED" 7 "RESERVED" 8 "RESERVED" 9 "RESERVED" 10 "RESERVED" 11 "RESERVED" 12 "New Frangrance Mounted(Genuine cartidge, Not registered new frangrance)" 13 "No Cartridge Mounted" 14 "Unknown Cartridge Mounted (Not Genuine cartidge)" 15 "Error Indicator" ;
VAL_ 624 PCM_ActSta 0 "Normal Stop" 1 "Normal Moving" 2 "Calibration" 3 "Reserved" 4 "Reserved" 5 "Reserved" 6 "Reserved" 7 "Reserved" 8 "Reserved" 9 "Reserved" 10 "Reserved" 11 "Reserved" 12 "Reserved" 13 "Reserved" 14 "Temporary Failure" 15 "Permanent Failure" ;
VAL_ 624 PCM_ActFail 0 "Normal" 1 "Motor Stall" 2 "Motor circuit open/short(Motor Internal error, Over Current)" 3 "Over temperature" 4 "Over/Under Voltage" 5 "LIN Tiemout" 6 "reserved" 7 "reserved" ;
VAL_ 625 PCM_Cart1VectorX 0 "coordinate" 1 "coordinate" 2 "coordinate" 3 "coordinate" 4 "coordinate" 5 "coordinate" 6 "coordinate" 7 "coordinate" 8 "coordinate" 9 "coordinate" 10 "coordinate" 11 "coordinate" 12 "coordinate" 13 "coordinate" 14 "coordinate" 15 "coordinate" 16 "coordinate" 17 "coordinate" 18 "coordinate" 19 "coordinate" 20 "coordinate" 21 "15~0xFD:RESERVED" 253 "15~0xFD:RESERVED" 254 "Cartridge Not Contacted" 255 "Error Indicator" ;
VAL_ 625 PCM_Cart1RmnPer 0 "0x0000~0x03E8:0~100.0%" 1000 "0x0000~0x03E8:0~100.0%" 1001 "03E9~0xFFFE:Reserverd" 65534 "03E9~0xFFFE:Reserverd" 65535 "Error Indicator" ;
VAL_ 625 PCM_Cart1ExpSta 0 "Default" 1 "Normal" 2 "Expired" 3 "Error Indicator" ;
VAL_ 625 PCM_Cart1RmnDisp 0 "Default" 1 "Remains 100% (70~100%)" 2 "Remains 70% (30~70%)" 3 "Remains 30% (1~30%)" 4 "Remains 0%" 5 "Reserved" 6 "Unknown" 7 "Error Indicator" ;
VAL_ 625 PCM_Cart1VectorY 0 "coordinate" 1 "coordinate" 2 "coordinate" 3 "coordinate" 4 "coordinate" 5 "coordinate" 6 "coordinate" 7 "coordinate" 8 "coordinate" 9 "coordinate" 10 "coordinate" 11 "coordinate" 12 "coordinate" 13 "coordinate" 14 "coordinate" 15 "coordinate" 16 "coordinate" 17 "coordinate" 18 "coordinate" 19 "coordinate" 20 "coordinate" 21 "15~0xFD:RESERVED" 253 "15~0xFD:RESERVED" 254 "Cartridge Not Contacted" 255 "Error Indicator" ;
VAL_ 626 PCM_Cart2VectorX 0 "coordinate" 1 "coordinate" 2 "coordinate" 3 "coordinate" 4 "coordinate" 5 "coordinate" 6 "coordinate" 7 "coordinate" 8 "coordinate" 9 "coordinate" 10 "coordinate" 11 "coordinate" 12 "coordinate" 13 "coordinate" 14 "coordinate" 15 "coordinate" 16 "coordinate" 17 "coordinate" 18 "coordinate" 19 "coordinate" 20 "coordinate" 21 "15~0xFD:RESERVED" 253 "15~0xFD:RESERVED" 254 "Cartridge Not Contacted" 255 "Error Indicator" ;
VAL_ 626 PCM_Cart2RmnPer 0 "0x0000~0x03E8:0~100.0%" 1000 "0x0000~0x03E8:0~100.0%" 1001 "03E9~0xFFFE:Reserverd" 65534 "03E9~0xFFFE:Reserverd" 65535 "Error Indicator" ;
VAL_ 626 PCM_Cart2ExpSta 0 "Default" 1 "Normal" 2 "Expired" 3 "Error Indicator" ;
VAL_ 626 PCM_Cart2RmnDisp 0 "Default" 1 "Remains 100% (70~100%)" 2 "Remains 70% (30~70%)" 3 "Remains 30% (1~30%)" 4 "Remains 0%" 5 "Reserved" 6 "Unknown" 7 "Error Indicator" ;
VAL_ 626 PCM_Cart2VectorY 0 "coordinate" 1 "coordinate" 2 "coordinate" 3 "coordinate" 4 "coordinate" 5 "coordinate" 6 "coordinate" 7 "coordinate" 8 "coordinate" 9 "coordinate" 10 "coordinate" 11 "coordinate" 12 "coordinate" 13 "coordinate" 14 "coordinate" 15 "coordinate" 16 "coordinate" 17 "coordinate" 18 "coordinate" 19 "coordinate" 20 "coordinate" 21 "15~0xFD:RESERVED" 253 "15~0xFD:RESERVED" 254 "Cartridge Not Contacted" 255 "Error Indicator" ;
